BU_:  Airbag BAP_Tester ICAS1_Gateway ICAS1_KommunikationsServer LE1 LE2 Motor_BEV Schaltbetaetigung

BU_:  Airbag BAP_Tester ICAS1_Gateway ICAS1_KommunikationsServer LE1 LE2 Motor_BEV Schaltbetaetigung

BO_ 980 SMLS_01: 8 ICAS1_Gateway
 SG_ SMLS_01_CRC  : 0|8@1+ (1.000000,0.000000) [0.000000|255.000000] "" Vector__XXX
 SG_ SMLS_01_BZ  : 8|4@1+ (1.000000,0.000000) [0.000000|15.000000] "" Vector__XXX
 SG_ BH_Blinker_li  : 12|1@1+ (1.000000,0.000000) [0.000000|1.000000] "" Motor_BEV
 SG_ BH_Blinker_re  : 13|1@1+ (1.000000,0.000000) [0.000000|1.000000] "" Motor_BEV
 SG_ BH_Lichthupe  : 14|1@1+ (1.000000,0.000000) [0.000000|1.000000] "" Vector__XXX
 SG_ BH_Fernlicht  : 15|1@1+ (1.000000,0.000000) [0.000000|1.000000] "" Vector__XXX
 SG_ WH_Tipwischen  : 16|1@1+ (1.000000,0.000000) [0.000000|1.000000] "" Vector__XXX
 SG_ WH_Intervall  : 17|1@1+ (1.000000,0.000000) [0.000000|1.000000] "" Vector__XXX
 SG_ WH_WischerStufe1  : 18|1@1+ (1.000000,0.000000) [0.000000|1.000000] "" Vector__XXX
 SG_ WH_WischerStufe2  : 19|1@1+ (1.000000,0.000000) [0.000000|1.000000] "" Vector__XXX
 SG_ WH_Frontwaschen  : 20|1@1+ (1.000000,0.000000) [0.000000|1.000000] "" Vector__XXX
 SG_ WH_Heckintervall  : 21|1@1+ (1.000000,0.000000) [0.000000|1.000000] "" Vector__XXX
 SG_ WH_Heckwaschen  : 22|1@1+ (1.000000,0.000000) [0.000000|1.000000] "" Vector__XXX
 SG_ WH_Intervallstufen  : 23|4@1+ (1.000000,0.000000) [0.000000|15.000000] "" Vector__XXX
 SG_ FAS_Taster  : 27|1@1+ (1.000000,0.000000) [0.000000|1.000000] "" Vector__XXX
 SG_ FAS_Taster_Fehler  : 28|1@1+ (1.000000,0.000000) [0.000000|1.000000] "" Vector__XXX
 SG_ SMLS_Hupe  : 29|1@1+ (1.000000,0.000000) [0.000000|1.000000] "" Vector__XXX
 SG_ LRH_on_off  : 30|2@1+ (1.000000,0.000000) [0.000000|3.000000] "" Vector__XXX
 SG_ LSS_Tastencode  : 32|8@1+ (1.000000,0.000000) [0.000000|255.000000] "" Vector__XXX
 SG_ LRH_aktiv  : 40|1@1+ (1.000000,0.000000) [0.000000|1.000000] "" Vector__XXX
 SG_ SMLS_P_verriegelt  : 41|2@1+ (1.000000,0.000000) [0.000000|3.000000] "" Vector__XXX
 SG_ SMLS_P_verriegelt_plausibel  : 43|1@1+ (1.000000,0.000000) [0.000000|1.000000] "" Vector__XXX
 SG_ WH_SRA  : 44|1@1+ (1.000000,0.000000) [0.000000|1.000000] "" Vector__XXX
 SG_ WH_Wischer_Fehler  : 45|1@1+ (1.000000,0.000000) [0.000000|1.000000] "" Vector__XXX
 SG_ BH_Blinker_Fehler  : 46|1@1+ (1.000000,0.000000) [0.000000|1.000000] "" Vector__XXX
 SG_ SMLS_PTT  : 47|1@1+ (1.000000,0.000000) [0.000000|1.000000] "" Vector__XXX
 SG_ WH_Tipwischen_lang  : 48|1@1+ (1.000000,0.000000) [0.000000|1.000000] "" Vector__XXX

BO_ 2464153718 SOK_FoD_MO_01_Req_Chal_01: 8 Motor_BEV
 SG_ SOK_FoD_MO_01_Req_Challenge  : 0|64@1+ (1.000000,0.000000) [0.000000|18446744073709551616.000000] "Unit_None" ICAS1_Gateway

BO_ 2464284790 SOK_FoD_MO_01_Resp_Chal_01: 8 ICAS1_Gateway
 SG_ SOK_FoD_MO_01_Resp_Challenge  : 0|64@1+ (1.000000,0.000000) [0.000000|18446744073709551616.000000] "Unit_None" Motor_BEV

BO_ 1413 Systeminfo_01: 8 ICAS1_Gateway
 SG_ SI_Sammel_SG_Fehler  : 0|6@1+ (1.000000,0.000000) [0.000000|60.000000] "" Vector__XXX
 SG_ SI_P_Mode_gueltig  : 6|1@1+ (1.000000,0.000000) [0.000000|1.000000] "" Vector__XXX
 SG_ SI_Diagnose_Aktiv  : 7|1@1+ (1.000000,0.000000) [0.000000|1.000000] "" Vector__XXX
 SG_ SI_QRS_Mode  : 8|1@1+ (1.000000,0.000000) [0.000000|1.000000] "" Airbag Motor_BEV
 SG_ SI_T_Mode  : 9|1@1+ (1.000000,0.000000) [0.000000|1.000000] "" Motor_BEV
 SG_ SI_NWDF  : 10|1@1+ (1.000000,0.000000) [0.000000|1.000000] "" Vector__XXX
 SG_ SI_NWDF_gueltig  : 11|1@1+ (1.000000,0.000000) [0.000000|1.000000] "" Vector__XXX
 SG_ SI_Sammelfehler  : 12|1@1+ (1.000000,0.000000) [0.000000|1.000000] "" Vector__XXX
 SG_ GW_KD_Fehler  : 13|1@1+ (1.000000,0.000000) [0.000000|1.000000] "" Vector__XXX
 SG_ SI_T_Schutz  : 14|1@1+ (1.000000,0.000000) [0.000000|1.000000] "" Motor_BEV
 SG_ SI_P_Mode  : 15|1@1+ (1.000000,0.000000) [0.000000|1.000000] "" Vector__XXX
 SG_ SI_BUS_01  : 16|1@1+ (1.000000,0.000000) [0.000000|1.000000] "" Vector__XXX
 SG_ SI_BUS_02  : 17|1@1+ (1.000000,0.000000) [0.000000|1.000000] "" Vector__XXX
 SG_ SI_BUS_03  : 18|1@1+ (1.000000,0.000000) [0.000000|1.000000] "" Vector__XXX
 SG_ SI_BUS_04  : 19|1@1+ (1.000000,0.000000) [0.000000|1.000000] "" Vector__XXX
 SG_ SI_BUS_05  : 20|1@1+ (1.000000,0.000000) [0.000000|1.000000] "" Vector__XXX
 SG_ SI_BUS_06  : 21|1@1+ (1.000000,0.000000) [0.000000|1.000000] "" Vector__XXX
 SG_ SI_BUS_07  : 22|1@1+ (1.000000,0.000000) [0.000000|1.000000] "" Vector__XXX
 SG_ SI_BUS_08  : 23|1@1+ (1.000000,0.000000) [0.000000|1.000000] "" Vector__XXX
 SG_ SI_BUS_09  : 24|1@1+ (1.000000,0.000000) [0.000000|1.000000] "" Vector__XXX
 SG_ SI_BUS_10  : 25|1@1+ (1.000000,0.000000) [0.000000|1.000000] "" Vector__XXX
 SG_ SI_BUS_11  : 26|1@1+ (1.000000,0.000000) [0.000000|1.000000] "" Vector__XXX
 SG_ SI_BUS_12  : 27|1@1+ (1.000000,0.000000) [0.000000|1.000000] "" Vector__XXX
 SG_ SI_BUS_13  : 28|1@1+ (1.000000,0.000000) [0.000000|1.000000] "" Vector__XXX
 SG_ SI_BUS_14  : 29|1@1+ (1.000000,0.000000) [0.000000|1.000000] "" Vector__XXX
 SG_ SI_BUS_15  : 30|1@1+ (1.000000,0.000000) [0.000000|1.000000] "" Vector__XXX
 SG_ SI_Bus_Identifikation  : 32|8@1+ (1.000000,0.000000) [0.000000|255.000000] "" Vector__XXX
 SG_ SI_CAB_V10  : 40|24@1+ (1.000000,0.000000) [0.000000|16777215.000000] "" Vector__XXX

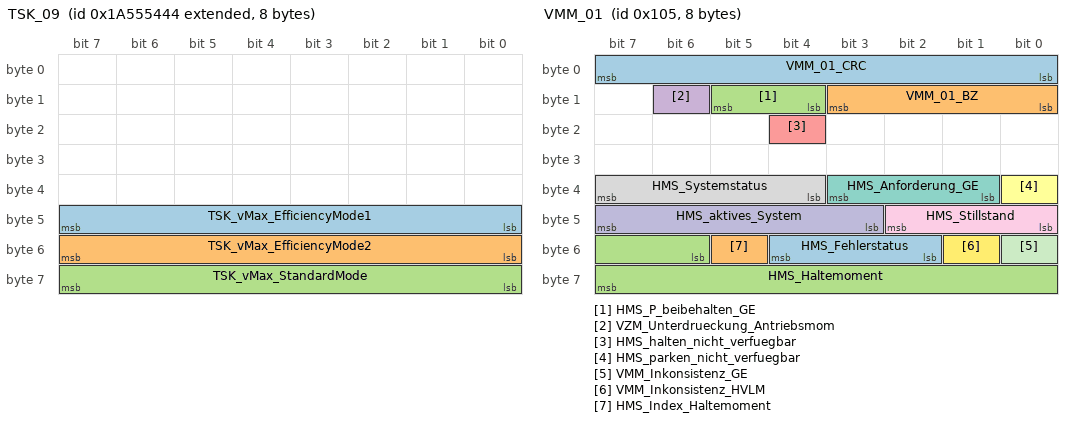
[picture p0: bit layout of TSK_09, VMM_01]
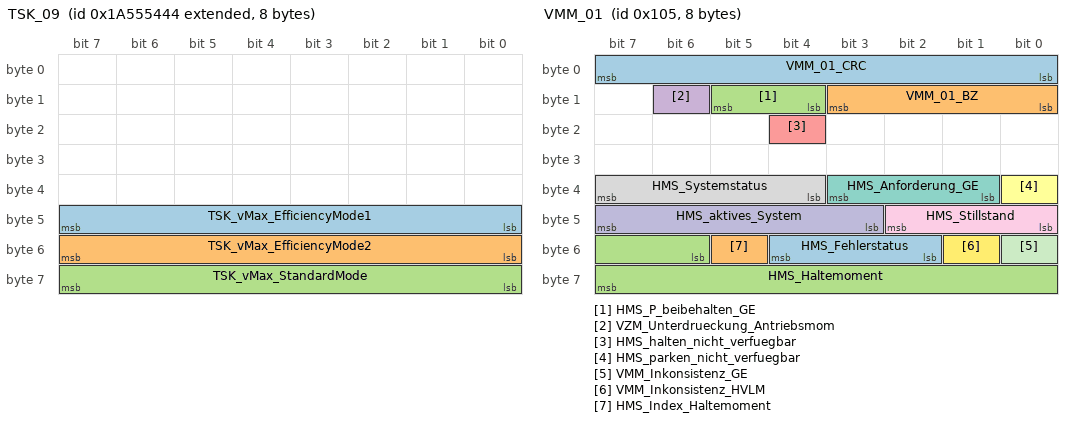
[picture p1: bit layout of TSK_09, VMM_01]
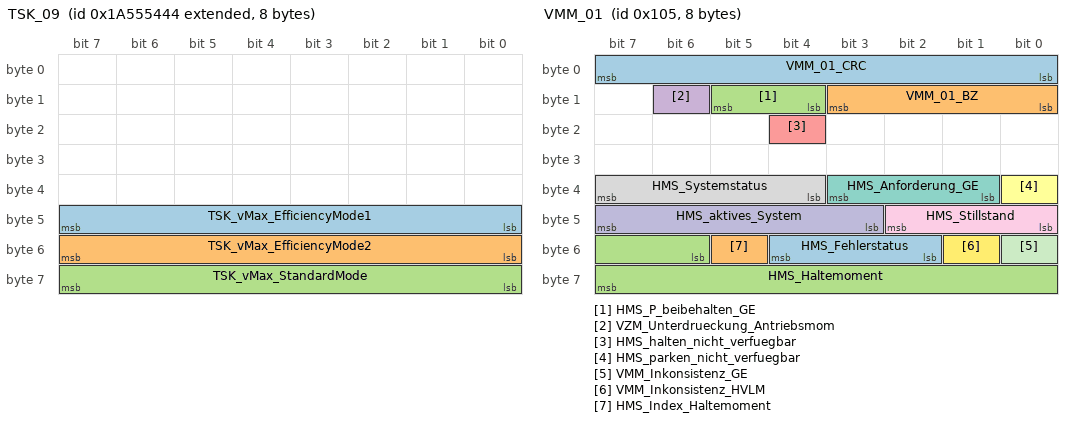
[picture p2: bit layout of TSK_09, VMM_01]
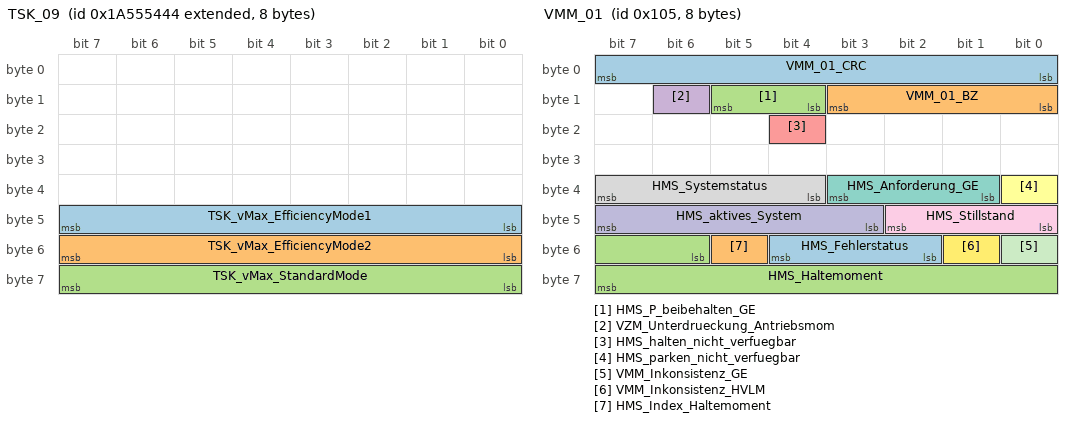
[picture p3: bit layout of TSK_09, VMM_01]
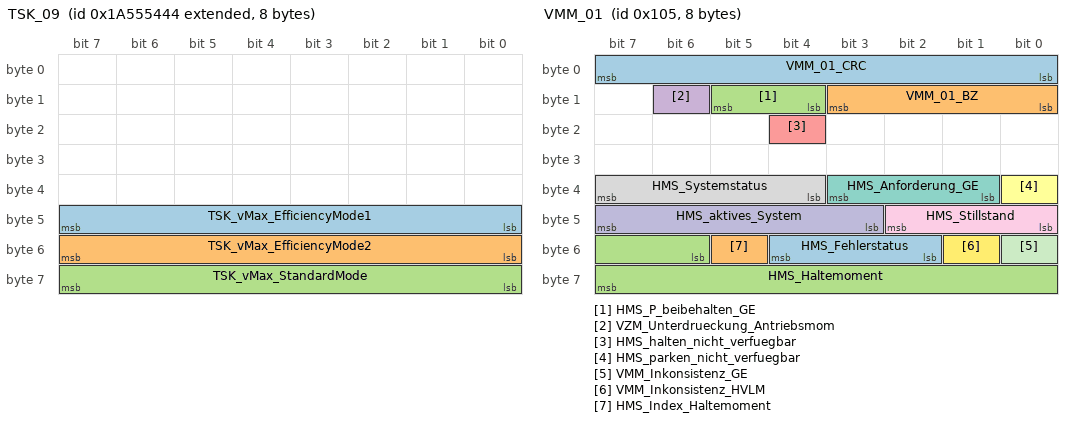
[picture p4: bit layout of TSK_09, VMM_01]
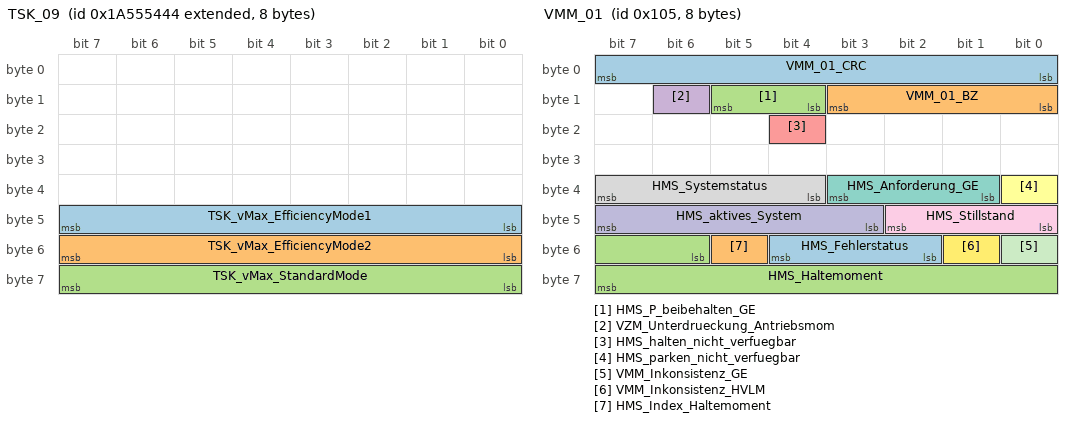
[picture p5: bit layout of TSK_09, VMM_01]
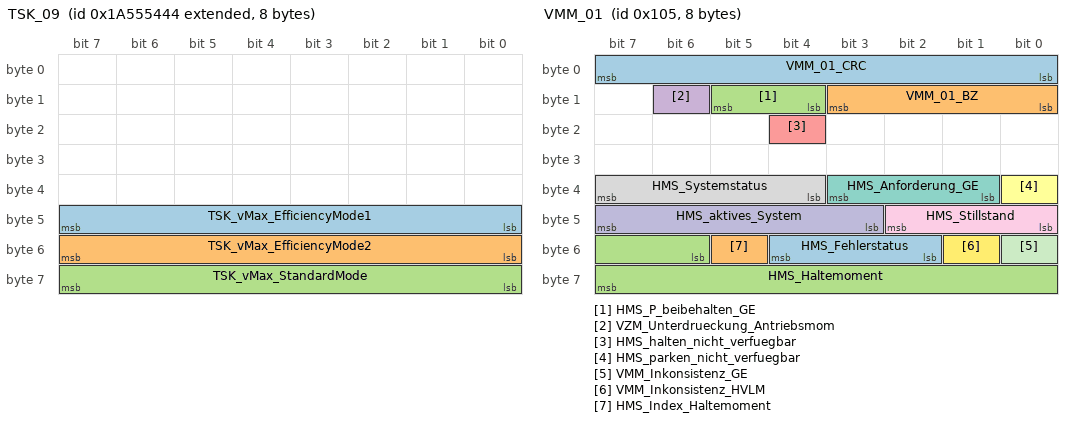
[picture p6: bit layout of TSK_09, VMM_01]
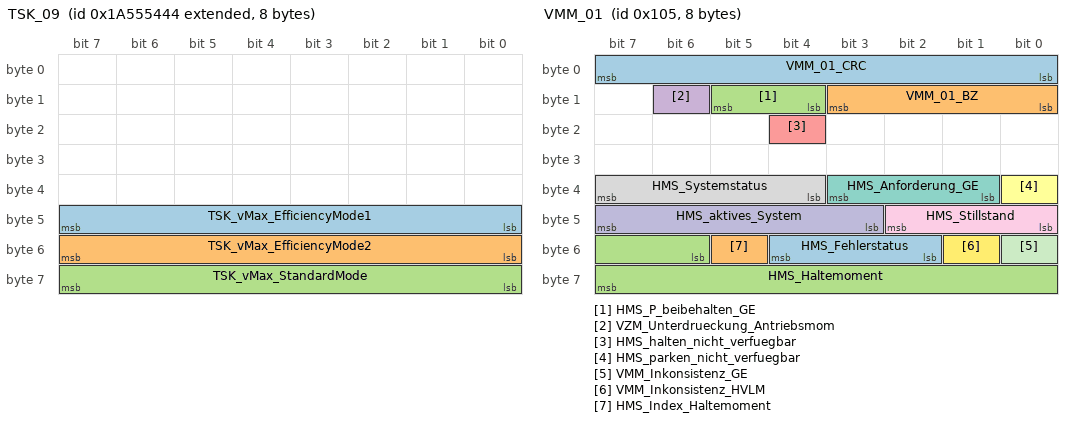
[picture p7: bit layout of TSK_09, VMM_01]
BO_ 2589283396 TSK_09: 8 Motor_BEV
 SG_ TSK_vMax_EfficiencyMode1  : 40|8@1+ (1.000000,0.000000) [0.000000|253.000000] "Unit_KiloMeterPerHour" ICAS1_Gateway
 SG_ TSK_vMax_EfficiencyMode2  : 48|8@1+ (1.000000,0.000000) [0.000000|253.000000] "Unit_KiloMeterPerHour" ICAS1_Gateway
 SG_ TSK_vMax_StandardMode  : 56|8@1+ (1.000000,0.000000) [0.000000|253.000000] "Unit_KiloMeterPerHour" ICAS1_Gateway

BO_ 1019 TSK_Ausrollkurve_01: 8 Motor_BEV
 SG_ TSK_Ausrollkurve_Schub_Reku_01 m0 : 0|7@1+ (2.000000,0.000000) [0.000000|252.000000] "Unit_KiloMeterPerHour" ICAS1_Gateway
 SG_ TSK_Ausrollkurve_Schub_Reku_05 m1 : 0|7@1+ (2.000000,0.000000) [0.000000|252.000000] "Unit_KiloMeterPerHour" ICAS1_Gateway
 SG_ TSK_Ausrollkurve_Schub_Reku_09 m2 : 0|7@1+ (2.000000,0.000000) [0.000000|252.000000] "Unit_KiloMeterPerHour" ICAS1_Gateway
 SG_ TSK_Ausrollkurve_Schub_Reku_13 m3 : 0|7@1+ (2.000000,0.000000) [0.000000|252.000000] "Unit_KiloMeterPerHour" ICAS1_Gateway
 SG_ TSK_Ausrollkurve_Schub_Reku_17 m4 : 0|7@1+ (2.000000,0.000000) [0.000000|252.000000] "Unit_KiloMeterPerHour" ICAS1_Gateway
 SG_ TSK_Ausrollkurve_Schub_Reku_02 m0 : 7|7@1+ (2.000000,0.000000) [0.000000|252.000000] "Unit_KiloMeterPerHour" ICAS1_Gateway
 SG_ TSK_Ausrollkurve_Schub_Reku_06 m1 : 7|7@1+ (2.000000,0.000000) [0.000000|252.000000] "Unit_KiloMeterPerHour" ICAS1_Gateway
 SG_ TSK_Ausrollkurve_Schub_Reku_10 m2 : 7|7@1+ (2.000000,0.000000) [0.000000|252.000000] "Unit_KiloMeterPerHour" ICAS1_Gateway
 SG_ TSK_Ausrollkurve_Schub_Reku_14 m3 : 7|7@1+ (2.000000,0.000000) [0.000000|252.000000] "Unit_KiloMeterPerHour" ICAS1_Gateway
 SG_ TSK_Ausrollkurve_Schub_Reku_18 m4 : 7|7@1+ (2.000000,0.000000) [0.000000|252.000000] "Unit_KiloMeterPerHour" ICAS1_Gateway
 SG_ TSK_Ausrollkurve_Schub_Reku_03 m0 : 14|7@1+ (2.000000,0.000000) [0.000000|252.000000] "Unit_KiloMeterPerHour" ICAS1_Gateway
 SG_ TSK_Ausrollkurve_Schub_Reku_07 m1 : 14|7@1+ (2.000000,0.000000) [0.000000|252.000000] "Unit_KiloMeterPerHour" ICAS1_Gateway
 SG_ TSK_Ausrollkurve_Schub_Reku_11 m2 : 14|7@1+ (2.000000,0.000000) [0.000000|252.000000] "Unit_KiloMeterPerHour" ICAS1_Gateway
 SG_ TSK_Ausrollkurve_Schub_Reku_15 m3 : 14|7@1+ (2.000000,0.000000) [0.000000|252.000000] "Unit_KiloMeterPerHour" ICAS1_Gateway
 SG_ TSK_Ausrollkurve_Schub_Reku_19 m4 : 14|7@1+ (2.000000,0.000000) [0.000000|252.000000] "Unit_KiloMeterPerHour" ICAS1_Gateway
 SG_ TSK_Ausrollkurve_Schub_Reku_04 m0 : 21|7@1+ (2.000000,0.000000) [0.000000|252.000000] "Unit_KiloMeterPerHour" ICAS1_Gateway
 SG_ TSK_Ausrollkurve_Schub_Reku_08 m1 : 21|7@1+ (2.000000,0.000000) [0.000000|252.000000] "Unit_KiloMeterPerHour" ICAS1_Gateway
 SG_ TSK_Ausrollkurve_Schub_Reku_12 m2 : 21|7@1+ (2.000000,0.000000) [0.000000|252.000000] "Unit_KiloMeterPerHour" ICAS1_Gateway
 SG_ TSK_Ausrollkurve_Schub_Reku_16 m3 : 21|7@1+ (2.000000,0.000000) [0.000000|252.000000] "Unit_KiloMeterPerHour" ICAS1_Gateway
 SG_ TSK_Ausrollkurve_Schub_Reku_20 m4 : 21|7@1+ (2.000000,0.000000) [0.000000|252.000000] "Unit_KiloMeterPerHour" ICAS1_Gateway
 SG_ TSK_Ausrollkurve_Segeln_01 m0 : 28|7@1+ (2.000000,0.000000) [0.000000|252.000000] "Unit_KiloMeterPerHour" ICAS1_Gateway
 SG_ TSK_Ausrollkurve_Segeln_05 m1 : 28|7@1+ (2.000000,0.000000) [0.000000|252.000000] "Unit_KiloMeterPerHour" ICAS1_Gateway
 SG_ TSK_Ausrollkurve_Segeln_09 m2 : 28|7@1+ (2.000000,0.000000) [0.000000|252.000000] "Unit_KiloMeterPerHour" ICAS1_Gateway
 SG_ TSK_Ausrollkurve_Segeln_13 m3 : 28|7@1+ (2.000000,0.000000) [0.000000|252.000000] "Unit_KiloMeterPerHour" ICAS1_Gateway
 SG_ TSK_Ausrollkurve_Segeln_17 m4 : 28|7@1+ (2.000000,0.000000) [0.000000|252.000000] "Unit_KiloMeterPerHour" ICAS1_Gateway
 SG_ TSK_Ausrollkurve_Segeln_02 m0 : 35|7@1+ (2.000000,0.000000) [0.000000|252.000000] "Unit_KiloMeterPerHour" ICAS1_Gateway
 SG_ TSK_Ausrollkurve_Segeln_06 m1 : 35|7@1+ (2.000000,0.000000) [0.000000|252.000000] "Unit_KiloMeterPerHour" ICAS1_Gateway
 SG_ TSK_Ausrollkurve_Segeln_10 m2 : 35|7@1+ (2.000000,0.000000) [0.000000|252.000000] "Unit_KiloMeterPerHour" ICAS1_Gateway
 SG_ TSK_Ausrollkurve_Segeln_14 m3 : 35|7@1+ (2.000000,0.000000) [0.000000|252.000000] "Unit_KiloMeterPerHour" ICAS1_Gateway
 SG_ TSK_Ausrollkurve_Segeln_18 m4 : 35|7@1+ (2.000000,0.000000) [0.000000|252.000000] "Unit_KiloMeterPerHour" ICAS1_Gateway
 SG_ TSK_Ausrollkurve_Segeln_03 m0 : 42|7@1+ (2.000000,0.000000) [0.000000|252.000000] "Unit_KiloMeterPerHour" ICAS1_Gateway
 SG_ TSK_Ausrollkurve_Segeln_07 m1 : 42|7@1+ (2.000000,0.000000) [0.000000|252.000000] "Unit_KiloMeterPerHour" ICAS1_Gateway
 SG_ TSK_Ausrollkurve_Segeln_11 m2 : 42|7@1+ (2.000000,0.000000) [0.000000|252.000000] "Unit_KiloMeterPerHour" ICAS1_Gateway
 SG_ TSK_Ausrollkurve_Segeln_15 m3 : 42|7@1+ (2.000000,0.000000) [0.000000|252.000000] "Unit_KiloMeterPerHour" ICAS1_Gateway
 SG_ TSK_Ausrollkurve_Segeln_19 m4 : 42|7@1+ (2.000000,0.000000) [0.000000|252.000000] "Unit_KiloMeterPerHour" ICAS1_Gateway
 SG_ TSK_Ausrollkurve_Segeln_04 m0 : 49|7@1+ (2.000000,0.000000) [0.000000|252.000000] "Unit_KiloMeterPerHour" ICAS1_Gateway
 SG_ TSK_Ausrollkurve_Segeln_08 m1 : 49|7@1+ (2.000000,0.000000) [0.000000|252.000000] "Unit_KiloMeterPerHour" ICAS1_Gateway
 SG_ TSK_Ausrollkurve_Segeln_12 m2 : 49|7@1+ (2.000000,0.000000) [0.000000|252.000000] "Unit_KiloMeterPerHour" ICAS1_Gateway
 SG_ TSK_Ausrollkurve_Segeln_16 m3 : 49|7@1+ (2.000000,0.000000) [0.000000|252.000000] "Unit_KiloMeterPerHour" ICAS1_Gateway
 SG_ TSK_Ausrollkurve_Segeln_20 m4 : 49|7@1+ (2.000000,0.000000) [0.000000|252.000000] "Unit_KiloMeterPerHour" ICAS1_Gateway
 SG_ TSK_Ausrollkurve_Mux M : 56|3@1+ (1.000000,0.000000) [0.000000|7.000000] "" ICAS1_Gateway
 SG_ TSK_Ausrollkurve_Reku  : 59|1@1+ (1.000000,0.000000) [0.000000|1.000000] "" ICAS1_Gateway
 SG_ TSK_Ausrollkurve_Schrittweite  : 60|1@1+ (1.000000,0.000000) [0.000000|1.000000] "" ICAS1_Gateway
 SG_ TSK_Ausrollkurve_Zaehler  : 61|2@1+ (1.000000,0.000000) [0.000000|3.000000] "" ICAS1_Gateway

BO_ 1716 VIN_01: 8 ICAS1_Gateway
 SG_ VIN_01_MUX M : 0|2@1+ (1.000000,0.000000) [0.000000|3.000000] "" Airbag Motor_BEV
 SG_ KS_Geheimnis_1 m0 : 8|8@1+ (1.000000,0.000000) [0.000000|255.000000] "" Airbag
 SG_ VIN_4 m1 : 8|8@1+ (1.000000,0.000000) [0.000000|255.000000] "" Airbag Motor_BEV
 SG_ VIN_11 m2 : 8|8@1+ (1.000000,0.000000) [0.000000|255.000000] "" Airbag Motor_BEV
 SG_ KS_Geheimnis_2 m0 : 16|8@1+ (1.000000,0.000000) [0.000000|255.000000] "" Airbag
 SG_ VIN_5 m1 : 16|8@1+ (1.000000,0.000000) [0.000000|255.000000] "" Airbag Motor_BEV
 SG_ VIN_12 m2 : 16|8@1+ (1.000000,0.000000) [0.000000|255.000000] "" Airbag Motor_BEV
 SG_ KS_Geheimnis_3 m0 : 24|8@1+ (1.000000,0.000000) [0.000000|255.000000] "" Airbag
 SG_ VIN_6 m1 : 24|8@1+ (1.000000,0.000000) [0.000000|255.000000] "" Airbag Motor_BEV
 SG_ VIN_13 m2 : 24|8@1+ (1.000000,0.000000) [0.000000|255.000000] "" Airbag Motor_BEV
 SG_ KS_Geheimnis_4 m0 : 32|8@1+ (1.000000,0.000000) [0.000000|255.000000] "" Airbag
 SG_ VIN_7 m1 : 32|8@1+ (1.000000,0.000000) [0.000000|255.000000] "" Airbag Motor_BEV
 SG_ VIN_14 m2 : 32|8@1+ (1.000000,0.000000) [0.000000|255.000000] "" Airbag Motor_BEV
 SG_ VIN_1 m0 : 40|8@1+ (1.000000,0.000000) [0.000000|255.000000] "" Airbag Motor_BEV
 SG_ VIN_8 m1 : 40|8@1+ (1.000000,0.000000) [0.000000|255.000000] "" Airbag Motor_BEV
 SG_ VIN_15 m2 : 40|8@1+ (1.000000,0.000000) [0.000000|255.000000] "" Airbag Motor_BEV
 SG_ VIN_2 m0 : 48|8@1+ (1.000000,0.000000) [0.000000|255.000000] "" Airbag Motor_BEV
 SG_ VIN_9 m1 : 48|8@1+ (1.000000,0.000000) [0.000000|255.000000] "" Airbag Motor_BEV
 SG_ VIN_16 m2 : 48|8@1+ (1.000000,0.000000) [0.000000|255.000000] "" Airbag Motor_BEV
 SG_ VIN_3 m0 : 56|8@1+ (1.000000,0.000000) [0.000000|255.000000] "" Airbag Motor_BEV
 SG_ VIN_10 m1 : 56|8@1+ (1.000000,0.000000) [0.000000|255.000000] "" Airbag Motor_BEV
 SG_ VIN_17 m2 : 56|8@1+ (1.000000,0.000000) [0.000000|255.000000] "" Airbag Motor_BEV

BO_ 261 VMM_01: 8 ICAS1_Gateway
 SG_ VMM_01_CRC  : 0|8@1+ (1.000000,0.000000) [0.000000|255.000000] "" Motor_BEV
 SG_ VMM_01_BZ  : 8|4@1+ (1.000000,0.000000) [0.000000|15.000000] "" Motor_BEV
 SG_ HMS_P_beibehalten_GE  : 12|2@1+ (1.000000,0.000000) [0.000000|3.000000] "" Vector__XXX
 SG_ VZM_Unterdrueckung_Antriebsmom  : 14|1@1+ (1.000000,0.000000) [0.000000|1.000000] "" Airbag Motor_BEV
 SG_ HMS_halten_nicht_verfuegbar  : 20|1@1+ (1.000000,0.000000) [0.000000|1.000000] "" Vector__XXX
 SG_ HMS_parken_nicht_verfuegbar  : 32|1@1+ (1.000000,0.000000) [0.000000|1.000000] "" Vector__XXX
 SG_ HMS_Anforderung_GE  : 33|3@1+ (1.000000,0.000000) [0.000000|7.000000] "" Vector__XXX
 SG_ HMS_Systemstatus  : 36|4@1+ (1.000000,0.000000) [0.000000|15.000000] "" Motor_BEV
 SG_ HMS_Stillstand  : 40|3@1+ (1.000000,0.000000) [0.000000|7.000000] "" Motor_BEV
 SG_ HMS_aktives_System  : 43|5@1+ (1.000000,0.000000) [0.000000|31.000000] "" Motor_BEV
 SG_ VMM_Inkonsistenz_GE  : 48|1@1+ (1.000000,0.000000) [0.000000|1.000000] "" Motor_BEV
 SG_ VMM_Inkonsistenz_HVLM  : 49|1@1+ (1.000000,0.000000) [0.000000|1.000000] "" Motor_BEV
 SG_ HMS_Fehlerstatus  : 50|3@1+ (1.000000,0.000000) [0.000000|7.000000] "" Vector__XXX
 SG_ HMS_Index_Haltemoment  : 53|1@1+ (1.000000,0.000000) [0.000000|1.000000] "" Motor_BEV
 SG_ HMS_Haltemoment  : 54|10@1+ (10.000000,0.000000) [0.000000|10210.000000] "Unit_NewtoMeter" Motor_BEV

BO_ 313 VMM_02: 32 ICAS1_Gateway
 SG_ VMM_02_CRC  : 0|8@1+ (1.000000,0.000000) [0.000000|255.000000] "" Motor_BEV
 SG_ VMM_02_BZ  : 8|4@1+ (1.000000,0.000000) [0.000000|15.000000] "" Motor_BEV
 SG_ VZM_aktiver_Basisservice  : 12|3@1+ (1.000000,0.000000) [0.000000|7.000000] "" Motor_BEV
 SG_ VZM_Anhalteweg_nicht_verfuegbar  : 15|1@1+ (1.000000,0.000000) [0.000000|1.000000] "" Motor_BEV
 SG_ VZM_Fahrer_bremst  : 16|1@1+ (1.000000,0.000000) [0.000000|1.000000] "" Motor_BEV
 SG_ VZM_QBit_Fahrer_bremst  : 17|1@1+ (1.000000,0.000000) [0.000000|1.000000] "" Motor_BEV
 SG_ VMM_MKB_codiert  : 18|1@1+ (1.000000,0.000000) [0.000000|1.000000] "" Airbag
 SG_ VMM_Inkonsistenz_EBKV  : 19|1@1+ (1.000000,0.000000) [0.000000|1.000000] "" Vector__XXX
 SG_ VMM_Notstopp_Status  : 20|3@1+ (1.000000,0.000000) [0.000000|7.000000] "" Motor_BEV
 SG_ VZM_Warnruck_nicht_verfuegbar  : 23|1@1+ (1.000000,0.000000) [0.000000|1.000000] "" Motor_BEV
 SG_ VZM_Warnruckeln_nicht_verfuegbar  : 24|1@1+ (1.000000,0.000000) [0.000000|1.000000] "" Motor_BEV
 SG_ VZM_Bkd_nicht_verfuegbar  : 25|1@1+ (1.000000,0.000000) [0.000000|1.000000] "" Motor_BEV
 SG_ VMM_Bremslicht_defekt  : 26|1@1+ (1.000000,0.000000) [0.000000|1.000000] "" Motor_BEV
 SG_ VZM_Fahrer_bremst_deutlich  : 27|1@1+ (1.000000,0.000000) [0.000000|1.000000] "" Airbag Motor_BEV
 SG_ VZM_TSK_SRBM_Anf  : 28|1@1+ (1.000000,0.000000) [0.000000|1.000000] "" Motor_BEV
 SG_ VZM_TSK_SRBM_nicht_verfuegbar  : 29|1@1+ (1.000000,0.000000) [0.000000|1.000000] "" Motor_BEV
 SG_ VZM_Verz_Reg_aktiv  : 30|5@1+ (1.000000,0.000000) [0.000000|31.000000] "" Motor_BEV
 SG_ VZM_Verz_Reg_nicht_verfuegbar  : 35|1@1+ (1.000000,0.000000) [0.000000|1.000000] "" Motor_BEV
 SG_ VMM_Inkonsistenz_KAS  : 36|1@1+ (1.000000,0.000000) [0.000000|1.000000] "" Motor_BEV
 SG_ VMM_Bremslicht_unplausibel  : 37|1@1+ (1.000000,0.000000) [0.000000|1.000000] "" Motor_BEV
 SG_ VMM_Inkonsistenz_ACC  : 38|1@1+ (1.000000,0.000000) [0.000000|1.000000] "" Motor_BEV
 SG_ VMM_Inkonsistenz_AWV_PCF  : 39|1@1+ (1.000000,0.000000) [0.000000|1.000000] "" Motor_BEV
 SG_ VMM_Inkonsistenz_ARA  : 40|1@1+ (1.000000,0.000000) [0.000000|1.000000] "" Motor_BEV
 SG_ VMM_Inkonsistenz_ParkAssist  : 41|1@1+ (1.000000,0.000000) [0.000000|1.000000] "" Motor_BEV
 SG_ VMM_Inkonsistenz_FAS_VK  : 42|1@1+ (1.000000,0.000000) [0.000000|1.000000] "" Motor_BEV
 SG_ VMM_Inkonsistenz_NV  : 43|1@1+ (1.000000,0.000000) [0.000000|1.000000] "" Motor_BEV
 SG_ VMM_Inkonsistenz_RCTA  : 44|1@1+ (1.000000,0.000000) [0.000000|1.000000] "" Motor_BEV
 SG_ VMM_Inkonsistenz_TSK  : 45|1@1+ (1.000000,0.000000) [0.000000|1.000000] "" Motor_BEV
 SG_ VMM_Inkonsistenz_MO  : 46|1@1+ (1.000000,0.000000) [0.000000|1.000000] "" Motor_BEV
 SG_ VMM_Inkonsistenz_AEB  : 47|1@1+ (1.000000,0.000000) [0.000000|1.000000] "" Vector__XXX
 SG_ VMM_Fahrer_Bremskraft_bestimmend  : 48|1@1+ (1.000000,0.000000) [0.000000|1.000000] "" Motor_BEV
 SG_ VMM_Inkonsistenz_EA  : 49|1@1+ (1.000000,0.000000) [0.000000|1.000000] "" Motor_BEV
 SG_ VZM_Status_Wegregelung  : 50|2@1+ (1.000000,0.000000) [0.000000|3.000000] "" Motor_BEV
 SG_ VZM_Verz_ASIL_Verfuegbarkeit  : 52|3@1+ (1.000000,0.000000) [0.000000|7.000000] "" Motor_BEV
 SG_ VZM_aktives_System  : 55|5@1+ (1.000000,0.000000) [0.000000|31.000000] "" Airbag Motor_BEV
 SG_ VZM_Verz_Begrenzung  : 60|1@1+ (1.000000,0.000000) [0.000000|1.000000] "" Motor_BEV
 SG_ VZM_Systemstatus  : 61|3@1+ (1.000000,0.000000) [0.000000|7.000000] "" Motor_BEV
 SG_ VZM_SRBM_Soll  : 64|12@1+ (8.000000,0.000000) [0.000000|32744.000000] "Unit_NewtoMeter" Motor_BEV
 SG_ VZM_SRBM_Ist  : 76|12@1+ (8.000000,0.000000) [0.000000|32744.000000] "Unit_NewtoMeter" Motor_BEV
 SG_ VZM_SRBM_max_Gradient  : 88|7@1+ (50.000000,0.000000) [0.000000|6250.000000] "Unit_NewtoMeterPerSecon" Motor_BEV
 SG_ VMM_Inkonsistenz_KAM  : 95|1@1+ (1.000000,0.000000) [0.000000|1.000000] "" Vector__XXX

BU_:  Airbag BAP_Tester ICAS1_Gateway ICAS1_KommunikationsServer LE1 LE2 Motor_BEV Schaltbetaetigung

BO_ 980 SMLS_01: 8 ICAS1_Gateway
 SG_ SMLS_01_CRC  : 0|8@1+ (1.000000,0.000000) [0.000000|255.000000] "" Vector__XXX
 SG_ SMLS_01_BZ  : 8|4@1+ (1.000000,0.000000) [0.000000|15.000000] "" Vector__XXX
 SG_ BH_Blinker_li  : 12|1@1+ (1.000000,0.000000) [0.000000|1.000000] "" Motor_BEV
 SG_ BH_Blinker_re  : 13|1@1+ (1.000000,0.000000) [0.000000|1.000000] "" Motor_BEV
 SG_ BH_Lichthupe  : 14|1@1+ (1.000000,0.000000) [0.000000|1.000000] "" Vector__XXX
 SG_ BH_Fernlicht  : 15|1@1+ (1.000000,0.000000) [0.000000|1.000000] "" Vector__XXX
 SG_ WH_Tipwischen  : 16|1@1+ (1.000000,0.000000) [0.000000|1.000000] "" Vector__XXX
 SG_ WH_Intervall  : 17|1@1+ (1.000000,0.000000) [0.000000|1.000000] "" Vector__XXX
 SG_ WH_WischerStufe1  : 18|1@1+ (1.000000,0.000000) [0.000000|1.000000] "" Vector__XXX
 SG_ WH_WischerStufe2  : 19|1@1+ (1.000000,0.000000) [0.000000|1.000000] "" Vector__XXX
 SG_ WH_Frontwaschen  : 20|1@1+ (1.000000,0.000000) [0.000000|1.000000] "" Vector__XXX
 SG_ WH_Heckintervall  : 21|1@1+ (1.000000,0.000000) [0.000000|1.000000] "" Vector__XXX
 SG_ WH_Heckwaschen  : 22|1@1+ (1.000000,0.000000) [0.000000|1.000000] "" Vector__XXX
 SG_ WH_Intervallstufen  : 23|4@1+ (1.000000,0.000000) [0.000000|15.000000] "" Vector__XXX
 SG_ FAS_Taster  : 27|1@1+ (1.000000,0.000000) [0.000000|1.000000] "" Vector__XXX
 SG_ FAS_Taster_Fehler  : 28|1@1+ (1.000000,0.000000) [0.000000|1.000000] "" Vector__XXX
 SG_ SMLS_Hupe  : 29|1@1+ (1.000000,0.000000) [0.000000|1.000000] "" Vector__XXX
 SG_ LRH_on_off  : 30|2@1+ (1.000000,0.000000) [0.000000|3.000000] "" Vector__XXX
 SG_ LSS_Tastencode  : 32|8@1+ (1.000000,0.000000) [0.000000|255.000000] "" Vector__XXX
 SG_ LRH_aktiv  : 40|1@1+ (1.000000,0.000000) [0.000000|1.000000] "" Vector__XXX
 SG_ SMLS_P_verriegelt  : 41|2@1+ (1.000000,0.000000) [0.000000|3.000000] "" Vector__XXX
 SG_ SMLS_P_verriegelt_plausibel  : 43|1@1+ (1.000000,0.000000) [0.000000|1.000000] "" Vector__XXX
 SG_ WH_SRA  : 44|1@1+ (1.000000,0.000000) [0.000000|1.000000] "" Vector__XXX
 SG_ WH_Wischer_Fehler  : 45|1@1+ (1.000000,0.000000) [0.000000|1.000000] "" Vector__XXX
 SG_ BH_Blinker_Fehler  : 46|1@1+ (1.000000,0.000000) [0.000000|1.000000] "" Vector__XXX
 SG_ SMLS_PTT  : 47|1@1+ (1.000000,0.000000) [0.000000|1.000000] "" Vector__XXX
 SG_ WH_Tipwischen_lang  : 48|1@1+ (1.000000,0.000000) [0.000000|1.000000] "" Vector__XXX

BO_ 2464153718 SOK_FoD_MO_01_Req_Chal_01: 8 Motor_BEV
 SG_ SOK_FoD_MO_01_Req_Challenge  : 0|64@1+ (1.000000,0.000000) [0.000000|18446744073709551616.000000] "Unit_None" ICAS1_Gateway

BO_ 2464284790 SOK_FoD_MO_01_Resp_Chal_01: 8 ICAS1_Gateway
 SG_ SOK_FoD_MO_01_Resp_Challenge  : 0|64@1+ (1.000000,0.000000) [0.000000|18446744073709551616.000000] "Unit_None" Motor_BEV

BO_ 1413 Systeminfo_01: 8 ICAS1_Gateway
 SG_ SI_Sammel_SG_Fehler  : 0|6@1+ (1.000000,0.000000) [0.000000|60.000000] "" Vector__XXX
 SG_ SI_P_Mode_gueltig  : 6|1@1+ (1.000000,0.000000) [0.000000|1.000000] "" Vector__XXX
 SG_ SI_Diagnose_Aktiv  : 7|1@1+ (1.000000,0.000000) [0.000000|1.000000] "" Vector__XXX
 SG_ SI_QRS_Mode  : 8|1@1+ (1.000000,0.000000) [0.000000|1.000000] "" Airbag Motor_BEV
 SG_ SI_T_Mode  : 9|1@1+ (1.000000,0.000000) [0.000000|1.000000] "" Motor_BEV
 SG_ SI_NWDF  : 10|1@1+ (1.000000,0.000000) [0.000000|1.000000] "" Vector__XXX
 SG_ SI_NWDF_gueltig  : 11|1@1+ (1.000000,0.000000) [0.000000|1.000000] "" Vector__XXX
 SG_ SI_Sammelfehler  : 12|1@1+ (1.000000,0.000000) [0.000000|1.000000] "" Vector__XXX
 SG_ GW_KD_Fehler  : 13|1@1+ (1.000000,0.000000) [0.000000|1.000000] "" Vector__XXX
 SG_ SI_T_Schutz  : 14|1@1+ (1.000000,0.000000) [0.000000|1.000000] "" Motor_BEV
 SG_ SI_P_Mode  : 15|1@1+ (1.000000,0.000000) [0.000000|1.000000] "" Vector__XXX
 SG_ SI_BUS_01  : 16|1@1+ (1.000000,0.000000) [0.000000|1.000000] "" Vector__XXX
 SG_ SI_BUS_02  : 17|1@1+ (1.000000,0.000000) [0.000000|1.000000] "" Vector__XXX
 SG_ SI_BUS_03  : 18|1@1+ (1.000000,0.000000) [0.000000|1.000000] "" Vector__XXX
 SG_ SI_BUS_04  : 19|1@1+ (1.000000,0.000000) [0.000000|1.000000] "" Vector__XXX
 SG_ SI_BUS_05  : 20|1@1+ (1.000000,0.000000) [0.000000|1.000000] "" Vector__XXX
 SG_ SI_BUS_06  : 21|1@1+ (1.000000,0.000000) [0.000000|1.000000] "" Vector__XXX
 SG_ SI_BUS_07  : 22|1@1+ (1.000000,0.000000) [0.000000|1.000000] "" Vector__XXX
 SG_ SI_BUS_08  : 23|1@1+ (1.000000,0.000000) [0.000000|1.000000] "" Vector__XXX
 SG_ SI_BUS_09  : 24|1@1+ (1.000000,0.000000) [0.000000|1.000000] "" Vector__XXX
 SG_ SI_BUS_10  : 25|1@1+ (1.000000,0.000000) [0.000000|1.000000] "" Vector__XXX
 SG_ SI_BUS_11  : 26|1@1+ (1.000000,0.000000) [0.000000|1.000000] "" Vector__XXX
 SG_ SI_BUS_12  : 27|1@1+ (1.000000,0.000000) [0.000000|1.000000] "" Vector__XXX
 SG_ SI_BUS_13  : 28|1@1+ (1.000000,0.000000) [0.000000|1.000000] "" Vector__XXX
 SG_ SI_BUS_14  : 29|1@1+ (1.000000,0.000000) [0.000000|1.000000] "" Vector__XXX
 SG_ SI_BUS_15  : 30|1@1+ (1.000000,0.000000) [0.000000|1.000000] "" Vector__XXX
 SG_ SI_Bus_Identifikation  : 32|8@1+ (1.000000,0.000000) [0.000000|255.000000] "" Vector__XXX
 SG_ SI_CAB_V10  : 40|24@1+ (1.000000,0.000000) [0.000000|16777215.000000] "" Vector__XXX

BO_ 2589283396 TSK_09: 8 Motor_BEV
 SG_ TSK_vMax_EfficiencyMode1  : 40|8@1+ (1.000000,0.000000) [0.000000|253.000000] "Unit_KiloMeterPerHour" ICAS1_Gateway
 SG_ TSK_vMax_EfficiencyMode2  : 48|8@1+ (1.000000,0.000000) [0.000000|253.000000] "Unit_KiloMeterPerHour" ICAS1_Gateway
 SG_ TSK_vMax_StandardMode  : 56|8@1+ (1.000000,0.000000) [0.000000|253.000000] "Unit_KiloMeterPerHour" ICAS1_Gateway

BO_ 1019 TSK_Ausrollkurve_01: 8 Motor_BEV
 SG_ TSK_Ausrollkurve_Schub_Reku_01 m0 : 0|7@1+ (2.000000,0.000000) [0.000000|252.000000] "Unit_KiloMeterPerHour" ICAS1_Gateway
 SG_ TSK_Ausrollkurve_Schub_Reku_05 m1 : 0|7@1+ (2.000000,0.000000) [0.000000|252.000000] "Unit_KiloMeterPerHour" ICAS1_Gateway
 SG_ TSK_Ausrollkurve_Schub_Reku_09 m2 : 0|7@1+ (2.000000,0.000000) [0.000000|252.000000] "Unit_KiloMeterPerHour" ICAS1_Gateway
 SG_ TSK_Ausrollkurve_Schub_Reku_13 m3 : 0|7@1+ (2.000000,0.000000) [0.000000|252.000000] "Unit_KiloMeterPerHour" ICAS1_Gateway
 SG_ TSK_Ausrollkurve_Schub_Reku_17 m4 : 0|7@1+ (2.000000,0.000000) [0.000000|252.000000] "Unit_KiloMeterPerHour" ICAS1_Gateway
 SG_ TSK_Ausrollkurve_Schub_Reku_02 m0 : 7|7@1+ (2.000000,0.000000) [0.000000|252.000000] "Unit_KiloMeterPerHour" ICAS1_Gateway
 SG_ TSK_Ausrollkurve_Schub_Reku_06 m1 : 7|7@1+ (2.000000,0.000000) [0.000000|252.000000] "Unit_KiloMeterPerHour" ICAS1_Gateway
 SG_ TSK_Ausrollkurve_Schub_Reku_10 m2 : 7|7@1+ (2.000000,0.000000) [0.000000|252.000000] "Unit_KiloMeterPerHour" ICAS1_Gateway
 SG_ TSK_Ausrollkurve_Schub_Reku_14 m3 : 7|7@1+ (2.000000,0.000000) [0.000000|252.000000] "Unit_KiloMeterPerHour" ICAS1_Gateway
 SG_ TSK_Ausrollkurve_Schub_Reku_18 m4 : 7|7@1+ (2.000000,0.000000) [0.000000|252.000000] "Unit_KiloMeterPerHour" ICAS1_Gateway
 SG_ TSK_Ausrollkurve_Schub_Reku_03 m0 : 14|7@1+ (2.000000,0.000000) [0.000000|252.000000] "Unit_KiloMeterPerHour" ICAS1_Gateway
 SG_ TSK_Ausrollkurve_Schub_Reku_07 m1 : 14|7@1+ (2.000000,0.000000) [0.000000|252.000000] "Unit_KiloMeterPerHour" ICAS1_Gateway
 SG_ TSK_Ausrollkurve_Schub_Reku_11 m2 : 14|7@1+ (2.000000,0.000000) [0.000000|252.000000] "Unit_KiloMeterPerHour" ICAS1_Gateway
 SG_ TSK_Ausrollkurve_Schub_Reku_15 m3 : 14|7@1+ (2.000000,0.000000) [0.000000|252.000000] "Unit_KiloMeterPerHour" ICAS1_Gateway
 SG_ TSK_Ausrollkurve_Schub_Reku_19 m4 : 14|7@1+ (2.000000,0.000000) [0.000000|252.000000] "Unit_KiloMeterPerHour" ICAS1_Gateway
 SG_ TSK_Ausrollkurve_Schub_Reku_04 m0 : 21|7@1+ (2.000000,0.000000) [0.000000|252.000000] "Unit_KiloMeterPerHour" ICAS1_Gateway
 SG_ TSK_Ausrollkurve_Schub_Reku_08 m1 : 21|7@1+ (2.000000,0.000000) [0.000000|252.000000] "Unit_KiloMeterPerHour" ICAS1_Gateway
 SG_ TSK_Ausrollkurve_Schub_Reku_12 m2 : 21|7@1+ (2.000000,0.000000) [0.000000|252.000000] "Unit_KiloMeterPerHour" ICAS1_Gateway
 SG_ TSK_Ausrollkurve_Schub_Reku_16 m3 : 21|7@1+ (2.000000,0.000000) [0.000000|252.000000] "Unit_KiloMeterPerHour" ICAS1_Gateway
 SG_ TSK_Ausrollkurve_Schub_Reku_20 m4 : 21|7@1+ (2.000000,0.000000) [0.000000|252.000000] "Unit_KiloMeterPerHour" ICAS1_Gateway
 SG_ TSK_Ausrollkurve_Segeln_01 m0 : 28|7@1+ (2.000000,0.000000) [0.000000|252.000000] "Unit_KiloMeterPerHour" ICAS1_Gateway
 SG_ TSK_Ausrollkurve_Segeln_05 m1 : 28|7@1+ (2.000000,0.000000) [0.000000|252.000000] "Unit_KiloMeterPerHour" ICAS1_Gateway
 SG_ TSK_Ausrollkurve_Segeln_09 m2 : 28|7@1+ (2.000000,0.000000) [0.000000|252.000000] "Unit_KiloMeterPerHour" ICAS1_Gateway
 SG_ TSK_Ausrollkurve_Segeln_13 m3 : 28|7@1+ (2.000000,0.000000) [0.000000|252.000000] "Unit_KiloMeterPerHour" ICAS1_Gateway
 SG_ TSK_Ausrollkurve_Segeln_17 m4 : 28|7@1+ (2.000000,0.000000) [0.000000|252.000000] "Unit_KiloMeterPerHour" ICAS1_Gateway
 SG_ TSK_Ausrollkurve_Segeln_02 m0 : 35|7@1+ (2.000000,0.000000) [0.000000|252.000000] "Unit_KiloMeterPerHour" ICAS1_Gateway
 SG_ TSK_Ausrollkurve_Segeln_06 m1 : 35|7@1+ (2.000000,0.000000) [0.000000|252.000000] "Unit_KiloMeterPerHour" ICAS1_Gateway
 SG_ TSK_Ausrollkurve_Segeln_10 m2 : 35|7@1+ (2.000000,0.000000) [0.000000|252.000000] "Unit_KiloMeterPerHour" ICAS1_Gateway
 SG_ TSK_Ausrollkurve_Segeln_14 m3 : 35|7@1+ (2.000000,0.000000) [0.000000|252.000000] "Unit_KiloMeterPerHour" ICAS1_Gateway
 SG_ TSK_Ausrollkurve_Segeln_18 m4 : 35|7@1+ (2.000000,0.000000) [0.000000|252.000000] "Unit_KiloMeterPerHour" ICAS1_Gateway
 SG_ TSK_Ausrollkurve_Segeln_03 m0 : 42|7@1+ (2.000000,0.000000) [0.000000|252.000000] "Unit_KiloMeterPerHour" ICAS1_Gateway
 SG_ TSK_Ausrollkurve_Segeln_07 m1 : 42|7@1+ (2.000000,0.000000) [0.000000|252.000000] "Unit_KiloMeterPerHour" ICAS1_Gateway
 SG_ TSK_Ausrollkurve_Segeln_11 m2 : 42|7@1+ (2.000000,0.000000) [0.000000|252.000000] "Unit_KiloMeterPerHour" ICAS1_Gateway
 SG_ TSK_Ausrollkurve_Segeln_15 m3 : 42|7@1+ (2.000000,0.000000) [0.000000|252.000000] "Unit_KiloMeterPerHour" ICAS1_Gateway
 SG_ TSK_Ausrollkurve_Segeln_19 m4 : 42|7@1+ (2.000000,0.000000) [0.000000|252.000000] "Unit_KiloMeterPerHour" ICAS1_Gateway
 SG_ TSK_Ausrollkurve_Segeln_04 m0 : 49|7@1+ (2.000000,0.000000) [0.000000|252.000000] "Unit_KiloMeterPerHour" ICAS1_Gateway
 SG_ TSK_Ausrollkurve_Segeln_08 m1 : 49|7@1+ (2.000000,0.000000) [0.000000|252.000000] "Unit_KiloMeterPerHour" ICAS1_Gateway
 SG_ TSK_Ausrollkurve_Segeln_12 m2 : 49|7@1+ (2.000000,0.000000) [0.000000|252.000000] "Unit_KiloMeterPerHour" ICAS1_Gateway
 SG_ TSK_Ausrollkurve_Segeln_16 m3 : 49|7@1+ (2.000000,0.000000) [0.000000|252.000000] "Unit_KiloMeterPerHour" ICAS1_Gateway
 SG_ TSK_Ausrollkurve_Segeln_20 m4 : 49|7@1+ (2.000000,0.000000) [0.000000|252.000000] "Unit_KiloMeterPerHour" ICAS1_Gateway
 SG_ TSK_Ausrollkurve_Mux M : 56|3@1+ (1.000000,0.000000) [0.000000|7.000000] "" ICAS1_Gateway
 SG_ TSK_Ausrollkurve_Reku  : 59|1@1+ (1.000000,0.000000) [0.000000|1.000000] "" ICAS1_Gateway
 SG_ TSK_Ausrollkurve_Schrittweite  : 60|1@1+ (1.000000,0.000000) [0.000000|1.000000] "" ICAS1_Gateway
 SG_ TSK_Ausrollkurve_Zaehler  : 61|2@1+ (1.000000,0.000000) [0.000000|3.000000] "" ICAS1_Gateway

BO_ 1716 VIN_01: 8 ICAS1_Gateway
 SG_ VIN_01_MUX M : 0|2@1+ (1.000000,0.000000) [0.000000|3.000000] "" Airbag Motor_BEV
 SG_ KS_Geheimnis_1 m0 : 8|8@1+ (1.000000,0.000000) [0.000000|255.000000] "" Airbag
 SG_ VIN_4 m1 : 8|8@1+ (1.000000,0.000000) [0.000000|255.000000] "" Airbag Motor_BEV
 SG_ VIN_11 m2 : 8|8@1+ (1.000000,0.000000) [0.000000|255.000000] "" Airbag Motor_BEV
 SG_ KS_Geheimnis_2 m0 : 16|8@1+ (1.000000,0.000000) [0.000000|255.000000] "" Airbag
 SG_ VIN_5 m1 : 16|8@1+ (1.000000,0.000000) [0.000000|255.000000] "" Airbag Motor_BEV
 SG_ VIN_12 m2 : 16|8@1+ (1.000000,0.000000) [0.000000|255.000000] "" Airbag Motor_BEV
 SG_ KS_Geheimnis_3 m0 : 24|8@1+ (1.000000,0.000000) [0.000000|255.000000] "" Airbag
 SG_ VIN_6 m1 : 24|8@1+ (1.000000,0.000000) [0.000000|255.000000] "" Airbag Motor_BEV
 SG_ VIN_13 m2 : 24|8@1+ (1.000000,0.000000) [0.000000|255.000000] "" Airbag Motor_BEV
 SG_ KS_Geheimnis_4 m0 : 32|8@1+ (1.000000,0.000000) [0.000000|255.000000] "" Airbag
 SG_ VIN_7 m1 : 32|8@1+ (1.000000,0.000000) [0.000000|255.000000] "" Airbag Motor_BEV
 SG_ VIN_14 m2 : 32|8@1+ (1.000000,0.000000) [0.000000|255.000000] "" Airbag Motor_BEV
 SG_ VIN_1 m0 : 40|8@1+ (1.000000,0.000000) [0.000000|255.000000] "" Airbag Motor_BEV
 SG_ VIN_8 m1 : 40|8@1+ (1.000000,0.000000) [0.000000|255.000000] "" Airbag Motor_BEV
 SG_ VIN_15 m2 : 40|8@1+ (1.000000,0.000000) [0.000000|255.000000] "" Airbag Motor_BEV
 SG_ VIN_2 m0 : 48|8@1+ (1.000000,0.000000) [0.000000|255.000000] "" Airbag Motor_BEV
 SG_ VIN_9 m1 : 48|8@1+ (1.000000,0.000000) [0.000000|255.000000] "" Airbag Motor_BEV
 SG_ VIN_16 m2 : 48|8@1+ (1.000000,0.000000) [0.000000|255.000000] "" Airbag Motor_BEV
 SG_ VIN_3 m0 : 56|8@1+ (1.000000,0.000000) [0.000000|255.000000] "" Airbag Motor_BEV
 SG_ VIN_10 m1 : 56|8@1+ (1.000000,0.000000) [0.000000|255.000000] "" Airbag Motor_BEV
 SG_ VIN_17 m2 : 56|8@1+ (1.000000,0.000000) [0.000000|255.000000] "" Airbag Motor_BEV

BO_ 261 VMM_01: 8 ICAS1_Gateway
 SG_ VMM_01_CRC  : 0|8@1+ (1.000000,0.000000) [0.000000|255.000000] "" Motor_BEV
 SG_ VMM_01_BZ  : 8|4@1+ (1.000000,0.000000) [0.000000|15.000000] "" Motor_BEV
 SG_ HMS_P_beibehalten_GE  : 12|2@1+ (1.000000,0.000000) [0.000000|3.000000] "" Vector__XXX
 SG_ VZM_Unterdrueckung_Antriebsmom  : 14|1@1+ (1.000000,0.000000) [0.000000|1.000000] "" Airbag Motor_BEV
 SG_ HMS_halten_nicht_verfuegbar  : 20|1@1+ (1.000000,0.000000) [0.000000|1.000000] "" Vector__XXX
 SG_ HMS_parken_nicht_verfuegbar  : 32|1@1+ (1.000000,0.000000) [0.000000|1.000000] "" Vector__XXX
 SG_ HMS_Anforderung_GE  : 33|3@1+ (1.000000,0.000000) [0.000000|7.000000] "" Vector__XXX
 SG_ HMS_Systemstatus  : 36|4@1+ (1.000000,0.000000) [0.000000|15.000000] "" Motor_BEV
 SG_ HMS_Stillstand  : 40|3@1+ (1.000000,0.000000) [0.000000|7.000000] "" Motor_BEV
 SG_ HMS_aktives_System  : 43|5@1+ (1.000000,0.000000) [0.000000|31.000000] "" Motor_BEV
 SG_ VMM_Inkonsistenz_GE  : 48|1@1+ (1.000000,0.000000) [0.000000|1.000000] "" Motor_BEV
 SG_ VMM_Inkonsistenz_HVLM  : 49|1@1+ (1.000000,0.000000) [0.000000|1.000000] "" Motor_BEV
 SG_ HMS_Fehlerstatus  : 50|3@1+ (1.000000,0.000000) [0.000000|7.000000] "" Vector__XXX
 SG_ HMS_Index_Haltemoment  : 53|1@1+ (1.000000,0.000000) [0.000000|1.000000] "" Motor_BEV
 SG_ HMS_Haltemoment  : 54|10@1+ (10.000000,0.000000) [0.000000|10210.000000] "Unit_NewtoMeter" Motor_BEV

BO_ 313 VMM_02: 32 ICAS1_Gateway
 SG_ VMM_02_CRC  : 0|8@1+ (1.000000,0.000000) [0.000000|255.000000] "" Motor_BEV
 SG_ VMM_02_BZ  : 8|4@1+ (1.000000,0.000000) [0.000000|15.000000] "" Motor_BEV
 SG_ VZM_aktiver_Basisservice  : 12|3@1+ (1.000000,0.000000) [0.000000|7.000000] "" Motor_BEV
 SG_ VZM_Anhalteweg_nicht_verfuegbar  : 15|1@1+ (1.000000,0.000000) [0.000000|1.000000] "" Motor_BEV
 SG_ VZM_Fahrer_bremst  : 16|1@1+ (1.000000,0.000000) [0.000000|1.000000] "" Motor_BEV
 SG_ VZM_QBit_Fahrer_bremst  : 17|1@1+ (1.000000,0.000000) [0.000000|1.000000] "" Motor_BEV
 SG_ VMM_MKB_codiert  : 18|1@1+ (1.000000,0.000000) [0.000000|1.000000] "" Airbag
 SG_ VMM_Inkonsistenz_EBKV  : 19|1@1+ (1.000000,0.000000) [0.000000|1.000000] "" Vector__XXX
 SG_ VMM_Notstopp_Status  : 20|3@1+ (1.000000,0.000000) [0.000000|7.000000] "" Motor_BEV
 SG_ VZM_Warnruck_nicht_verfuegbar  : 23|1@1+ (1.000000,0.000000) [0.000000|1.000000] "" Motor_BEV
 SG_ VZM_Warnruckeln_nicht_verfuegbar  : 24|1@1+ (1.000000,0.000000) [0.000000|1.000000] "" Motor_BEV
 SG_ VZM_Bkd_nicht_verfuegbar  : 25|1@1+ (1.000000,0.000000) [0.000000|1.000000] "" Motor_BEV
 SG_ VMM_Bremslicht_defekt  : 26|1@1+ (1.000000,0.000000) [0.000000|1.000000] "" Motor_BEV
 SG_ VZM_Fahrer_bremst_deutlich  : 27|1@1+ (1.000000,0.000000) [0.000000|1.000000] "" Airbag Motor_BEV
 SG_ VZM_TSK_SRBM_Anf  : 28|1@1+ (1.000000,0.000000) [0.000000|1.000000] "" Motor_BEV
 SG_ VZM_TSK_SRBM_nicht_verfuegbar  : 29|1@1+ (1.000000,0.000000) [0.000000|1.000000] "" Motor_BEV
 SG_ VZM_Verz_Reg_aktiv  : 30|5@1+ (1.000000,0.000000) [0.000000|31.000000] "" Motor_BEV
 SG_ VZM_Verz_Reg_nicht_verfuegbar  : 35|1@1+ (1.000000,0.000000) [0.000000|1.000000] "" Motor_BEV
 SG_ VMM_Inkonsistenz_KAS  : 36|1@1+ (1.000000,0.000000) [0.000000|1.000000] "" Motor_BEV
 SG_ VMM_Bremslicht_unplausibel  : 37|1@1+ (1.000000,0.000000) [0.000000|1.000000] "" Motor_BEV
 SG_ VMM_Inkonsistenz_ACC  : 38|1@1+ (1.000000,0.000000) [0.000000|1.000000] "" Motor_BEV
 SG_ VMM_Inkonsistenz_AWV_PCF  : 39|1@1+ (1.000000,0.000000) [0.000000|1.000000] "" Motor_BEV
 SG_ VMM_Inkonsistenz_ARA  : 40|1@1+ (1.000000,0.000000) [0.000000|1.000000] "" Motor_BEV
 SG_ VMM_Inkonsistenz_ParkAssist  : 41|1@1+ (1.000000,0.000000) [0.000000|1.000000] "" Motor_BEV
 SG_ VMM_Inkonsistenz_FAS_VK  : 42|1@1+ (1.000000,0.000000) [0.000000|1.000000] "" Motor_BEV
 SG_ VMM_Inkonsistenz_NV  : 43|1@1+ (1.000000,0.000000) [0.000000|1.000000] "" Motor_BEV
 SG_ VMM_Inkonsistenz_RCTA  : 44|1@1+ (1.000000,0.000000) [0.000000|1.000000] "" Motor_BEV
 SG_ VMM_Inkonsistenz_TSK  : 45|1@1+ (1.000000,0.000000) [0.000000|1.000000] "" Motor_BEV
 SG_ VMM_Inkonsistenz_MO  : 46|1@1+ (1.000000,0.000000) [0.000000|1.000000] "" Motor_BEV
 SG_ VMM_Inkonsistenz_AEB  : 47|1@1+ (1.000000,0.000000) [0.000000|1.000000] "" Vector__XXX
 SG_ VMM_Fahrer_Bremskraft_bestimmend  : 48|1@1+ (1.000000,0.000000) [0.000000|1.000000] "" Motor_BEV
 SG_ VMM_Inkonsistenz_EA  : 49|1@1+ (1.000000,0.000000) [0.000000|1.000000] "" Motor_BEV
 SG_ VZM_Status_Wegregelung  : 50|2@1+ (1.000000,0.000000) [0.000000|3.000000] "" Motor_BEV
 SG_ VZM_Verz_ASIL_Verfuegbarkeit  : 52|3@1+ (1.000000,0.000000) [0.000000|7.000000] "" Motor_BEV
 SG_ VZM_aktives_System  : 55|5@1+ (1.000000,0.000000) [0.000000|31.000000] "" Airbag Motor_BEV
 SG_ VZM_Verz_Begrenzung  : 60|1@1+ (1.000000,0.000000) [0.000000|1.000000] "" Motor_BEV
 SG_ VZM_Systemstatus  : 61|3@1+ (1.000000,0.000000) [0.000000|7.000000] "" Motor_BEV
 SG_ VZM_SRBM_Soll  : 64|12@1+ (8.000000,0.000000) [0.000000|32744.000000] "Unit_NewtoMeter" Motor_BEV
 SG_ VZM_SRBM_Ist  : 76|12@1+ (8.000000,0.000000) [0.000000|32744.000000] "Unit_NewtoMeter" Motor_BEV
 SG_ VZM_SRBM_max_Gradient  : 88|7@1+ (50.000000,0.000000) [0.000000|6250.000000] "Unit_NewtoMeterPerSecon" Motor_BEV
 SG_ VMM_Inkonsistenz_KAM  : 95|1@1+ (1.000000,0.000000) [0.000000|1.000000] "" Vector__XXX

BU_:  Airbag BAP_Tester ICAS1_Gateway ICAS1_KommunikationsServer LE1 LE2 Motor_BEV Schaltbetaetigung

BO_ 980 SMLS_01: 8 ICAS1_Gateway
 SG_ SMLS_01_CRC  : 0|8@1+ (1.000000,0.000000) [0.000000|255.000000] "" Vector__XXX
 SG_ SMLS_01_BZ  : 8|4@1+ (1.000000,0.000000) [0.000000|15.000000] "" Vector__XXX
 SG_ BH_Blinker_li  : 12|1@1+ (1.000000,0.000000) [0.000000|1.000000] "" Motor_BEV
 SG_ BH_Blinker_re  : 13|1@1+ (1.000000,0.000000) [0.000000|1.000000] "" Motor_BEV
 SG_ BH_Lichthupe  : 14|1@1+ (1.000000,0.000000) [0.000000|1.000000] "" Vector__XXX
 SG_ BH_Fernlicht  : 15|1@1+ (1.000000,0.000000) [0.000000|1.000000] "" Vector__XXX
 SG_ WH_Tipwischen  : 16|1@1+ (1.000000,0.000000) [0.000000|1.000000] "" Vector__XXX
 SG_ WH_Intervall  : 17|1@1+ (1.000000,0.000000) [0.000000|1.000000] "" Vector__XXX
 SG_ WH_WischerStufe1  : 18|1@1+ (1.000000,0.000000) [0.000000|1.000000] "" Vector__XXX
 SG_ WH_WischerStufe2  : 19|1@1+ (1.000000,0.000000) [0.000000|1.000000] "" Vector__XXX
 SG_ WH_Frontwaschen  : 20|1@1+ (1.000000,0.000000) [0.000000|1.000000] "" Vector__XXX
 SG_ WH_Heckintervall  : 21|1@1+ (1.000000,0.000000) [0.000000|1.000000] "" Vector__XXX
 SG_ WH_Heckwaschen  : 22|1@1+ (1.000000,0.000000) [0.000000|1.000000] "" Vector__XXX
 SG_ WH_Intervallstufen  : 23|4@1+ (1.000000,0.000000) [0.000000|15.000000] "" Vector__XXX
 SG_ FAS_Taster  : 27|1@1+ (1.000000,0.000000) [0.000000|1.000000] "" Vector__XXX
 SG_ FAS_Taster_Fehler  : 28|1@1+ (1.000000,0.000000) [0.000000|1.000000] "" Vector__XXX
 SG_ SMLS_Hupe  : 29|1@1+ (1.000000,0.000000) [0.000000|1.000000] "" Vector__XXX
 SG_ LRH_on_off  : 30|2@1+ (1.000000,0.000000) [0.000000|3.000000] "" Vector__XXX
 SG_ LSS_Tastencode  : 32|8@1+ (1.000000,0.000000) [0.000000|255.000000] "" Vector__XXX
 SG_ LRH_aktiv  : 40|1@1+ (1.000000,0.000000) [0.000000|1.000000] "" Vector__XXX
 SG_ SMLS_P_verriegelt  : 41|2@1+ (1.000000,0.000000) [0.000000|3.000000] "" Vector__XXX
 SG_ SMLS_P_verriegelt_plausibel  : 43|1@1+ (1.000000,0.000000) [0.000000|1.000000] "" Vector__XXX
 SG_ WH_SRA  : 44|1@1+ (1.000000,0.000000) [0.000000|1.000000] "" Vector__XXX
 SG_ WH_Wischer_Fehler  : 45|1@1+ (1.000000,0.000000) [0.000000|1.000000] "" Vector__XXX
 SG_ BH_Blinker_Fehler  : 46|1@1+ (1.000000,0.000000) [0.000000|1.000000] "" Vector__XXX
 SG_ SMLS_PTT  : 47|1@1+ (1.000000,0.000000) [0.000000|1.000000] "" Vector__XXX
 SG_ WH_Tipwischen_lang  : 48|1@1+ (1.000000,0.000000) [0.000000|1.000000] "" Vector__XXX

BO_ 2464153718 SOK_FoD_MO_01_Req_Chal_01: 8 Motor_BEV
 SG_ SOK_FoD_MO_01_Req_Challenge  : 0|64@1+ (1.000000,0.000000) [0.000000|18446744073709551616.000000] "Unit_None" ICAS1_Gateway

BO_ 2464284790 SOK_FoD_MO_01_Resp_Chal_01: 8 ICAS1_Gateway
 SG_ SOK_FoD_MO_01_Resp_Challenge  : 0|64@1+ (1.000000,0.000000) [0.000000|18446744073709551616.000000] "Unit_None" Motor_BEV

BO_ 1413 Systeminfo_01: 8 ICAS1_Gateway
 SG_ SI_Sammel_SG_Fehler  : 0|6@1+ (1.000000,0.000000) [0.000000|60.000000] "" Vector__XXX
 SG_ SI_P_Mode_gueltig  : 6|1@1+ (1.000000,0.000000) [0.000000|1.000000] "" Vector__XXX
 SG_ SI_Diagnose_Aktiv  : 7|1@1+ (1.000000,0.000000) [0.000000|1.000000] "" Vector__XXX
 SG_ SI_QRS_Mode  : 8|1@1+ (1.000000,0.000000) [0.000000|1.000000] "" Airbag Motor_BEV
 SG_ SI_T_Mode  : 9|1@1+ (1.000000,0.000000) [0.000000|1.000000] "" Motor_BEV
 SG_ SI_NWDF  : 10|1@1+ (1.000000,0.000000) [0.000000|1.000000] "" Vector__XXX
 SG_ SI_NWDF_gueltig  : 11|1@1+ (1.000000,0.000000) [0.000000|1.000000] "" Vector__XXX
 SG_ SI_Sammelfehler  : 12|1@1+ (1.000000,0.000000) [0.000000|1.000000] "" Vector__XXX
 SG_ GW_KD_Fehler  : 13|1@1+ (1.000000,0.000000) [0.000000|1.000000] "" Vector__XXX
 SG_ SI_T_Schutz  : 14|1@1+ (1.000000,0.000000) [0.000000|1.000000] "" Motor_BEV
 SG_ SI_P_Mode  : 15|1@1+ (1.000000,0.000000) [0.000000|1.000000] "" Vector__XXX
 SG_ SI_BUS_01  : 16|1@1+ (1.000000,0.000000) [0.000000|1.000000] "" Vector__XXX
 SG_ SI_BUS_02  : 17|1@1+ (1.000000,0.000000) [0.000000|1.000000] "" Vector__XXX
 SG_ SI_BUS_03  : 18|1@1+ (1.000000,0.000000) [0.000000|1.000000] "" Vector__XXX
 SG_ SI_BUS_04  : 19|1@1+ (1.000000,0.000000) [0.000000|1.000000] "" Vector__XXX
 SG_ SI_BUS_05  : 20|1@1+ (1.000000,0.000000) [0.000000|1.000000] "" Vector__XXX
 SG_ SI_BUS_06  : 21|1@1+ (1.000000,0.000000) [0.000000|1.000000] "" Vector__XXX
 SG_ SI_BUS_07  : 22|1@1+ (1.000000,0.000000) [0.000000|1.000000] "" Vector__XXX
 SG_ SI_BUS_08  : 23|1@1+ (1.000000,0.000000) [0.000000|1.000000] "" Vector__XXX
 SG_ SI_BUS_09  : 24|1@1+ (1.000000,0.000000) [0.000000|1.000000] "" Vector__XXX
 SG_ SI_BUS_10  : 25|1@1+ (1.000000,0.000000) [0.000000|1.000000] "" Vector__XXX
 SG_ SI_BUS_11  : 26|1@1+ (1.000000,0.000000) [0.000000|1.000000] "" Vector__XXX
 SG_ SI_BUS_12  : 27|1@1+ (1.000000,0.000000) [0.000000|1.000000] "" Vector__XXX
 SG_ SI_BUS_13  : 28|1@1+ (1.000000,0.000000) [0.000000|1.000000] "" Vector__XXX
 SG_ SI_BUS_14  : 29|1@1+ (1.000000,0.000000) [0.000000|1.000000] "" Vector__XXX
 SG_ SI_BUS_15  : 30|1@1+ (1.000000,0.000000) [0.000000|1.000000] "" Vector__XXX
 SG_ SI_Bus_Identifikation  : 32|8@1+ (1.000000,0.000000) [0.000000|255.000000] "" Vector__XXX
 SG_ SI_CAB_V10  : 40|24@1+ (1.000000,0.000000) [0.000000|16777215.000000] "" Vector__XXX

BO_ 2589283396 TSK_09: 8 Motor_BEV
 SG_ TSK_vMax_EfficiencyMode1  : 40|8@1+ (1.000000,0.000000) [0.000000|253.000000] "Unit_KiloMeterPerHour" ICAS1_Gateway
 SG_ TSK_vMax_EfficiencyMode2  : 48|8@1+ (1.000000,0.000000) [0.000000|253.000000] "Unit_KiloMeterPerHour" ICAS1_Gateway
 SG_ TSK_vMax_StandardMode  : 56|8@1+ (1.000000,0.000000) [0.000000|253.000000] "Unit_KiloMeterPerHour" ICAS1_Gateway

BO_ 1019 TSK_Ausrollkurve_01: 8 Motor_BEV
 SG_ TSK_Ausrollkurve_Schub_Reku_01 m0 : 0|7@1+ (2.000000,0.000000) [0.000000|252.000000] "Unit_KiloMeterPerHour" ICAS1_Gateway
 SG_ TSK_Ausrollkurve_Schub_Reku_05 m1 : 0|7@1+ (2.000000,0.000000) [0.000000|252.000000] "Unit_KiloMeterPerHour" ICAS1_Gateway
 SG_ TSK_Ausrollkurve_Schub_Reku_09 m2 : 0|7@1+ (2.000000,0.000000) [0.000000|252.000000] "Unit_KiloMeterPerHour" ICAS1_Gateway
 SG_ TSK_Ausrollkurve_Schub_Reku_13 m3 : 0|7@1+ (2.000000,0.000000) [0.000000|252.000000] "Unit_KiloMeterPerHour" ICAS1_Gateway
 SG_ TSK_Ausrollkurve_Schub_Reku_17 m4 : 0|7@1+ (2.000000,0.000000) [0.000000|252.000000] "Unit_KiloMeterPerHour" ICAS1_Gateway
 SG_ TSK_Ausrollkurve_Schub_Reku_02 m0 : 7|7@1+ (2.000000,0.000000) [0.000000|252.000000] "Unit_KiloMeterPerHour" ICAS1_Gateway
 SG_ TSK_Ausrollkurve_Schub_Reku_06 m1 : 7|7@1+ (2.000000,0.000000) [0.000000|252.000000] "Unit_KiloMeterPerHour" ICAS1_Gateway
 SG_ TSK_Ausrollkurve_Schub_Reku_10 m2 : 7|7@1+ (2.000000,0.000000) [0.000000|252.000000] "Unit_KiloMeterPerHour" ICAS1_Gateway
 SG_ TSK_Ausrollkurve_Schub_Reku_14 m3 : 7|7@1+ (2.000000,0.000000) [0.000000|252.000000] "Unit_KiloMeterPerHour" ICAS1_Gateway
 SG_ TSK_Ausrollkurve_Schub_Reku_18 m4 : 7|7@1+ (2.000000,0.000000) [0.000000|252.000000] "Unit_KiloMeterPerHour" ICAS1_Gateway
 SG_ TSK_Ausrollkurve_Schub_Reku_03 m0 : 14|7@1+ (2.000000,0.000000) [0.000000|252.000000] "Unit_KiloMeterPerHour" ICAS1_Gateway
 SG_ TSK_Ausrollkurve_Schub_Reku_07 m1 : 14|7@1+ (2.000000,0.000000) [0.000000|252.000000] "Unit_KiloMeterPerHour" ICAS1_Gateway
 SG_ TSK_Ausrollkurve_Schub_Reku_11 m2 : 14|7@1+ (2.000000,0.000000) [0.000000|252.000000] "Unit_KiloMeterPerHour" ICAS1_Gateway
 SG_ TSK_Ausrollkurve_Schub_Reku_15 m3 : 14|7@1+ (2.000000,0.000000) [0.000000|252.000000] "Unit_KiloMeterPerHour" ICAS1_Gateway
 SG_ TSK_Ausrollkurve_Schub_Reku_19 m4 : 14|7@1+ (2.000000,0.000000) [0.000000|252.000000] "Unit_KiloMeterPerHour" ICAS1_Gateway
 SG_ TSK_Ausrollkurve_Schub_Reku_04 m0 : 21|7@1+ (2.000000,0.000000) [0.000000|252.000000] "Unit_KiloMeterPerHour" ICAS1_Gateway
 SG_ TSK_Ausrollkurve_Schub_Reku_08 m1 : 21|7@1+ (2.000000,0.000000) [0.000000|252.000000] "Unit_KiloMeterPerHour" ICAS1_Gateway
 SG_ TSK_Ausrollkurve_Schub_Reku_12 m2 : 21|7@1+ (2.000000,0.000000) [0.000000|252.000000] "Unit_KiloMeterPerHour" ICAS1_Gateway
 SG_ TSK_Ausrollkurve_Schub_Reku_16 m3 : 21|7@1+ (2.000000,0.000000) [0.000000|252.000000] "Unit_KiloMeterPerHour" ICAS1_Gateway
 SG_ TSK_Ausrollkurve_Schub_Reku_20 m4 : 21|7@1+ (2.000000,0.000000) [0.000000|252.000000] "Unit_KiloMeterPerHour" ICAS1_Gateway
 SG_ TSK_Ausrollkurve_Segeln_01 m0 : 28|7@1+ (2.000000,0.000000) [0.000000|252.000000] "Unit_KiloMeterPerHour" ICAS1_Gateway
 SG_ TSK_Ausrollkurve_Segeln_05 m1 : 28|7@1+ (2.000000,0.000000) [0.000000|252.000000] "Unit_KiloMeterPerHour" ICAS1_Gateway
 SG_ TSK_Ausrollkurve_Segeln_09 m2 : 28|7@1+ (2.000000,0.000000) [0.000000|252.000000] "Unit_KiloMeterPerHour" ICAS1_Gateway
 SG_ TSK_Ausrollkurve_Segeln_13 m3 : 28|7@1+ (2.000000,0.000000) [0.000000|252.000000] "Unit_KiloMeterPerHour" ICAS1_Gateway
 SG_ TSK_Ausrollkurve_Segeln_17 m4 : 28|7@1+ (2.000000,0.000000) [0.000000|252.000000] "Unit_KiloMeterPerHour" ICAS1_Gateway
 SG_ TSK_Ausrollkurve_Segeln_02 m0 : 35|7@1+ (2.000000,0.000000) [0.000000|252.000000] "Unit_KiloMeterPerHour" ICAS1_Gateway
 SG_ TSK_Ausrollkurve_Segeln_06 m1 : 35|7@1+ (2.000000,0.000000) [0.000000|252.000000] "Unit_KiloMeterPerHour" ICAS1_Gateway
 SG_ TSK_Ausrollkurve_Segeln_10 m2 : 35|7@1+ (2.000000,0.000000) [0.000000|252.000000] "Unit_KiloMeterPerHour" ICAS1_Gateway
 SG_ TSK_Ausrollkurve_Segeln_14 m3 : 35|7@1+ (2.000000,0.000000) [0.000000|252.000000] "Unit_KiloMeterPerHour" ICAS1_Gateway
 SG_ TSK_Ausrollkurve_Segeln_18 m4 : 35|7@1+ (2.000000,0.000000) [0.000000|252.000000] "Unit_KiloMeterPerHour" ICAS1_Gateway
 SG_ TSK_Ausrollkurve_Segeln_03 m0 : 42|7@1+ (2.000000,0.000000) [0.000000|252.000000] "Unit_KiloMeterPerHour" ICAS1_Gateway
 SG_ TSK_Ausrollkurve_Segeln_07 m1 : 42|7@1+ (2.000000,0.000000) [0.000000|252.000000] "Unit_KiloMeterPerHour" ICAS1_Gateway
 SG_ TSK_Ausrollkurve_Segeln_11 m2 : 42|7@1+ (2.000000,0.000000) [0.000000|252.000000] "Unit_KiloMeterPerHour" ICAS1_Gateway
 SG_ TSK_Ausrollkurve_Segeln_15 m3 : 42|7@1+ (2.000000,0.000000) [0.000000|252.000000] "Unit_KiloMeterPerHour" ICAS1_Gateway
 SG_ TSK_Ausrollkurve_Segeln_19 m4 : 42|7@1+ (2.000000,0.000000) [0.000000|252.000000] "Unit_KiloMeterPerHour" ICAS1_Gateway
 SG_ TSK_Ausrollkurve_Segeln_04 m0 : 49|7@1+ (2.000000,0.000000) [0.000000|252.000000] "Unit_KiloMeterPerHour" ICAS1_Gateway
 SG_ TSK_Ausrollkurve_Segeln_08 m1 : 49|7@1+ (2.000000,0.000000) [0.000000|252.000000] "Unit_KiloMeterPerHour" ICAS1_Gateway
 SG_ TSK_Ausrollkurve_Segeln_12 m2 : 49|7@1+ (2.000000,0.000000) [0.000000|252.000000] "Unit_KiloMeterPerHour" ICAS1_Gateway
 SG_ TSK_Ausrollkurve_Segeln_16 m3 : 49|7@1+ (2.000000,0.000000) [0.000000|252.000000] "Unit_KiloMeterPerHour" ICAS1_Gateway
 SG_ TSK_Ausrollkurve_Segeln_20 m4 : 49|7@1+ (2.000000,0.000000) [0.000000|252.000000] "Unit_KiloMeterPerHour" ICAS1_Gateway
 SG_ TSK_Ausrollkurve_Mux M : 56|3@1+ (1.000000,0.000000) [0.000000|7.000000] "" ICAS1_Gateway
 SG_ TSK_Ausrollkurve_Reku  : 59|1@1+ (1.000000,0.000000) [0.000000|1.000000] "" ICAS1_Gateway
 SG_ TSK_Ausrollkurve_Schrittweite  : 60|1@1+ (1.000000,0.000000) [0.000000|1.000000] "" ICAS1_Gateway
 SG_ TSK_Ausrollkurve_Zaehler  : 61|2@1+ (1.000000,0.000000) [0.000000|3.000000] "" ICAS1_Gateway

BO_ 1716 VIN_01: 8 ICAS1_Gateway
 SG_ VIN_01_MUX M : 0|2@1+ (1.000000,0.000000) [0.000000|3.000000] "" Airbag Motor_BEV
 SG_ KS_Geheimnis_1 m0 : 8|8@1+ (1.000000,0.000000) [0.000000|255.000000] "" Airbag
 SG_ VIN_4 m1 : 8|8@1+ (1.000000,0.000000) [0.000000|255.000000] "" Airbag Motor_BEV
 SG_ VIN_11 m2 : 8|8@1+ (1.000000,0.000000) [0.000000|255.000000] "" Airbag Motor_BEV
 SG_ KS_Geheimnis_2 m0 : 16|8@1+ (1.000000,0.000000) [0.000000|255.000000] "" Airbag
 SG_ VIN_5 m1 : 16|8@1+ (1.000000,0.000000) [0.000000|255.000000] "" Airbag Motor_BEV
 SG_ VIN_12 m2 : 16|8@1+ (1.000000,0.000000) [0.000000|255.000000] "" Airbag Motor_BEV
 SG_ KS_Geheimnis_3 m0 : 24|8@1+ (1.000000,0.000000) [0.000000|255.000000] "" Airbag
 SG_ VIN_6 m1 : 24|8@1+ (1.000000,0.000000) [0.000000|255.000000] "" Airbag Motor_BEV
 SG_ VIN_13 m2 : 24|8@1+ (1.000000,0.000000) [0.000000|255.000000] "" Airbag Motor_BEV
 SG_ KS_Geheimnis_4 m0 : 32|8@1+ (1.000000,0.000000) [0.000000|255.000000] "" Airbag
 SG_ VIN_7 m1 : 32|8@1+ (1.000000,0.000000) [0.000000|255.000000] "" Airbag Motor_BEV
 SG_ VIN_14 m2 : 32|8@1+ (1.000000,0.000000) [0.000000|255.000000] "" Airbag Motor_BEV
 SG_ VIN_1 m0 : 40|8@1+ (1.000000,0.000000) [0.000000|255.000000] "" Airbag Motor_BEV
 SG_ VIN_8 m1 : 40|8@1+ (1.000000,0.000000) [0.000000|255.000000] "" Airbag Motor_BEV
 SG_ VIN_15 m2 : 40|8@1+ (1.000000,0.000000) [0.000000|255.000000] "" Airbag Motor_BEV
 SG_ VIN_2 m0 : 48|8@1+ (1.000000,0.000000) [0.000000|255.000000] "" Airbag Motor_BEV
 SG_ VIN_9 m1 : 48|8@1+ (1.000000,0.000000) [0.000000|255.000000] "" Airbag Motor_BEV
 SG_ VIN_16 m2 : 48|8@1+ (1.000000,0.000000) [0.000000|255.000000] "" Airbag Motor_BEV
 SG_ VIN_3 m0 : 56|8@1+ (1.000000,0.000000) [0.000000|255.000000] "" Airbag Motor_BEV
 SG_ VIN_10 m1 : 56|8@1+ (1.000000,0.000000) [0.000000|255.000000] "" Airbag Motor_BEV
 SG_ VIN_17 m2 : 56|8@1+ (1.000000,0.000000) [0.000000|255.000000] "" Airbag Motor_BEV

BO_ 261 VMM_01: 8 ICAS1_Gateway
 SG_ VMM_01_CRC  : 0|8@1+ (1.000000,0.000000) [0.000000|255.000000] "" Motor_BEV
 SG_ VMM_01_BZ  : 8|4@1+ (1.000000,0.000000) [0.000000|15.000000] "" Motor_BEV
 SG_ HMS_P_beibehalten_GE  : 12|2@1+ (1.000000,0.000000) [0.000000|3.000000] "" Vector__XXX
 SG_ VZM_Unterdrueckung_Antriebsmom  : 14|1@1+ (1.000000,0.000000) [0.000000|1.000000] "" Airbag Motor_BEV
 SG_ HMS_halten_nicht_verfuegbar  : 20|1@1+ (1.000000,0.000000) [0.000000|1.000000] "" Vector__XXX
 SG_ HMS_parken_nicht_verfuegbar  : 32|1@1+ (1.000000,0.000000) [0.000000|1.000000] "" Vector__XXX
 SG_ HMS_Anforderung_GE  : 33|3@1+ (1.000000,0.000000) [0.000000|7.000000] "" Vector__XXX
 SG_ HMS_Systemstatus  : 36|4@1+ (1.000000,0.000000) [0.000000|15.000000] "" Motor_BEV
 SG_ HMS_Stillstand  : 40|3@1+ (1.000000,0.000000) [0.000000|7.000000] "" Motor_BEV
 SG_ HMS_aktives_System  : 43|5@1+ (1.000000,0.000000) [0.000000|31.000000] "" Motor_BEV
 SG_ VMM_Inkonsistenz_GE  : 48|1@1+ (1.000000,0.000000) [0.000000|1.000000] "" Motor_BEV
 SG_ VMM_Inkonsistenz_HVLM  : 49|1@1+ (1.000000,0.000000) [0.000000|1.000000] "" Motor_BEV
 SG_ HMS_Fehlerstatus  : 50|3@1+ (1.000000,0.000000) [0.000000|7.000000] "" Vector__XXX
 SG_ HMS_Index_Haltemoment  : 53|1@1+ (1.000000,0.000000) [0.000000|1.000000] "" Motor_BEV
 SG_ HMS_Haltemoment  : 54|10@1+ (10.000000,0.000000) [0.000000|10210.000000] "Unit_NewtoMeter" Motor_BEV

BO_ 313 VMM_02: 32 ICAS1_Gateway
 SG_ VMM_02_CRC  : 0|8@1+ (1.000000,0.000000) [0.000000|255.000000] "" Motor_BEV
 SG_ VMM_02_BZ  : 8|4@1+ (1.000000,0.000000) [0.000000|15.000000] "" Motor_BEV
 SG_ VZM_aktiver_Basisservice  : 12|3@1+ (1.000000,0.000000) [0.000000|7.000000] "" Motor_BEV
 SG_ VZM_Anhalteweg_nicht_verfuegbar  : 15|1@1+ (1.000000,0.000000) [0.000000|1.000000] "" Motor_BEV
 SG_ VZM_Fahrer_bremst  : 16|1@1+ (1.000000,0.000000) [0.000000|1.000000] "" Motor_BEV
 SG_ VZM_QBit_Fahrer_bremst  : 17|1@1+ (1.000000,0.000000) [0.000000|1.000000] "" Motor_BEV
 SG_ VMM_MKB_codiert  : 18|1@1+ (1.000000,0.000000) [0.000000|1.000000] "" Airbag
 SG_ VMM_Inkonsistenz_EBKV  : 19|1@1+ (1.000000,0.000000) [0.000000|1.000000] "" Vector__XXX
 SG_ VMM_Notstopp_Status  : 20|3@1+ (1.000000,0.000000) [0.000000|7.000000] "" Motor_BEV
 SG_ VZM_Warnruck_nicht_verfuegbar  : 23|1@1+ (1.000000,0.000000) [0.000000|1.000000] "" Motor_BEV
 SG_ VZM_Warnruckeln_nicht_verfuegbar  : 24|1@1+ (1.000000,0.000000) [0.000000|1.000000] "" Motor_BEV
 SG_ VZM_Bkd_nicht_verfuegbar  : 25|1@1+ (1.000000,0.000000) [0.000000|1.000000] "" Motor_BEV
 SG_ VMM_Bremslicht_defekt  : 26|1@1+ (1.000000,0.000000) [0.000000|1.000000] "" Motor_BEV
 SG_ VZM_Fahrer_bremst_deutlich  : 27|1@1+ (1.000000,0.000000) [0.000000|1.000000] "" Airbag Motor_BEV
 SG_ VZM_TSK_SRBM_Anf  : 28|1@1+ (1.000000,0.000000) [0.000000|1.000000] "" Motor_BEV
 SG_ VZM_TSK_SRBM_nicht_verfuegbar  : 29|1@1+ (1.000000,0.000000) [0.000000|1.000000] "" Motor_BEV
 SG_ VZM_Verz_Reg_aktiv  : 30|5@1+ (1.000000,0.000000) [0.000000|31.000000] "" Motor_BEV
 SG_ VZM_Verz_Reg_nicht_verfuegbar  : 35|1@1+ (1.000000,0.000000) [0.000000|1.000000] "" Motor_BEV
 SG_ VMM_Inkonsistenz_KAS  : 36|1@1+ (1.000000,0.000000) [0.000000|1.000000] "" Motor_BEV
 SG_ VMM_Bremslicht_unplausibel  : 37|1@1+ (1.000000,0.000000) [0.000000|1.000000] "" Motor_BEV
 SG_ VMM_Inkonsistenz_ACC  : 38|1@1+ (1.000000,0.000000) [0.000000|1.000000] "" Motor_BEV
 SG_ VMM_Inkonsistenz_AWV_PCF  : 39|1@1+ (1.000000,0.000000) [0.000000|1.000000] "" Motor_BEV
 SG_ VMM_Inkonsistenz_ARA  : 40|1@1+ (1.000000,0.000000) [0.000000|1.000000] "" Motor_BEV
 SG_ VMM_Inkonsistenz_ParkAssist  : 41|1@1+ (1.000000,0.000000) [0.000000|1.000000] "" Motor_BEV
 SG_ VMM_Inkonsistenz_FAS_VK  : 42|1@1+ (1.000000,0.000000) [0.000000|1.000000] "" Motor_BEV
 SG_ VMM_Inkonsistenz_NV  : 43|1@1+ (1.000000,0.000000) [0.000000|1.000000] "" Motor_BEV
 SG_ VMM_Inkonsistenz_RCTA  : 44|1@1+ (1.000000,0.000000) [0.000000|1.000000] "" Motor_BEV
 SG_ VMM_Inkonsistenz_TSK  : 45|1@1+ (1.000000,0.000000) [0.000000|1.000000] "" Motor_BEV
 SG_ VMM_Inkonsistenz_MO  : 46|1@1+ (1.000000,0.000000) [0.000000|1.000000] "" Motor_BEV
 SG_ VMM_Inkonsistenz_AEB  : 47|1@1+ (1.000000,0.000000) [0.000000|1.000000] "" Vector__XXX
 SG_ VMM_Fahrer_Bremskraft_bestimmend  : 48|1@1+ (1.000000,0.000000) [0.000000|1.000000] "" Motor_BEV
 SG_ VMM_Inkonsistenz_EA  : 49|1@1+ (1.000000,0.000000) [0.000000|1.000000] "" Motor_BEV
 SG_ VZM_Status_Wegregelung  : 50|2@1+ (1.000000,0.000000) [0.000000|3.000000] "" Motor_BEV
 SG_ VZM_Verz_ASIL_Verfuegbarkeit  : 52|3@1+ (1.000000,0.000000) [0.000000|7.000000] "" Motor_BEV
 SG_ VZM_aktives_System  : 55|5@1+ (1.000000,0.000000) [0.000000|31.000000] "" Airbag Motor_BEV
 SG_ VZM_Verz_Begrenzung  : 60|1@1+ (1.000000,0.000000) [0.000000|1.000000] "" Motor_BEV
 SG_ VZM_Systemstatus  : 61|3@1+ (1.000000,0.000000) [0.000000|7.000000] "" Motor_BEV
 SG_ VZM_SRBM_Soll  : 64|12@1+ (8.000000,0.000000) [0.000000|32744.000000] "Unit_NewtoMeter" Motor_BEV
 SG_ VZM_SRBM_Ist  : 76|12@1+ (8.000000,0.000000) [0.000000|32744.000000] "Unit_NewtoMeter" Motor_BEV
 SG_ VZM_SRBM_max_Gradient  : 88|7@1+ (50.000000,0.000000) [0.000000|6250.000000] "Unit_NewtoMeterPerSecon" Motor_BEV
 SG_ VMM_Inkonsistenz_KAM  : 95|1@1+ (1.000000,0.000000) [0.000000|1.000000] "" Vector__XXX

BU_:  Airbag BAP_Tester ICAS1_Gateway ICAS1_KommunikationsServer LE1 LE2 Motor_BEV Schaltbetaetigung

BO_ 980 SMLS_01: 8 ICAS1_Gateway
 SG_ SMLS_01_CRC  : 0|8@1+ (1.000000,0.000000) [0.000000|255.000000] "" Vector__XXX
 SG_ SMLS_01_BZ  : 8|4@1+ (1.000000,0.000000) [0.000000|15.000000] "" Vector__XXX
 SG_ BH_Blinker_li  : 12|1@1+ (1.000000,0.000000) [0.000000|1.000000] "" Motor_BEV
 SG_ BH_Blinker_re  : 13|1@1+ (1.000000,0.000000) [0.000000|1.000000] "" Motor_BEV
 SG_ BH_Lichthupe  : 14|1@1+ (1.000000,0.000000) [0.000000|1.000000] "" Vector__XXX
 SG_ BH_Fernlicht  : 15|1@1+ (1.000000,0.000000) [0.000000|1.000000] "" Vector__XXX
 SG_ WH_Tipwischen  : 16|1@1+ (1.000000,0.000000) [0.000000|1.000000] "" Vector__XXX
 SG_ WH_Intervall  : 17|1@1+ (1.000000,0.000000) [0.000000|1.000000] "" Vector__XXX
 SG_ WH_WischerStufe1  : 18|1@1+ (1.000000,0.000000) [0.000000|1.000000] "" Vector__XXX
 SG_ WH_WischerStufe2  : 19|1@1+ (1.000000,0.000000) [0.000000|1.000000] "" Vector__XXX
 SG_ WH_Frontwaschen  : 20|1@1+ (1.000000,0.000000) [0.000000|1.000000] "" Vector__XXX
 SG_ WH_Heckintervall  : 21|1@1+ (1.000000,0.000000) [0.000000|1.000000] "" Vector__XXX
 SG_ WH_Heckwaschen  : 22|1@1+ (1.000000,0.000000) [0.000000|1.000000] "" Vector__XXX
 SG_ WH_Intervallstufen  : 23|4@1+ (1.000000,0.000000) [0.000000|15.000000] "" Vector__XXX
 SG_ FAS_Taster  : 27|1@1+ (1.000000,0.000000) [0.000000|1.000000] "" Vector__XXX
 SG_ FAS_Taster_Fehler  : 28|1@1+ (1.000000,0.000000) [0.000000|1.000000] "" Vector__XXX
 SG_ SMLS_Hupe  : 29|1@1+ (1.000000,0.000000) [0.000000|1.000000] "" Vector__XXX
 SG_ LRH_on_off  : 30|2@1+ (1.000000,0.000000) [0.000000|3.000000] "" Vector__XXX
 SG_ LSS_Tastencode  : 32|8@1+ (1.000000,0.000000) [0.000000|255.000000] "" Vector__XXX
 SG_ LRH_aktiv  : 40|1@1+ (1.000000,0.000000) [0.000000|1.000000] "" Vector__XXX
 SG_ SMLS_P_verriegelt  : 41|2@1+ (1.000000,0.000000) [0.000000|3.000000] "" Vector__XXX
 SG_ SMLS_P_verriegelt_plausibel  : 43|1@1+ (1.000000,0.000000) [0.000000|1.000000] "" Vector__XXX
 SG_ WH_SRA  : 44|1@1+ (1.000000,0.000000) [0.000000|1.000000] "" Vector__XXX
 SG_ WH_Wischer_Fehler  : 45|1@1+ (1.000000,0.000000) [0.000000|1.000000] "" Vector__XXX
 SG_ BH_Blinker_Fehler  : 46|1@1+ (1.000000,0.000000) [0.000000|1.000000] "" Vector__XXX
 SG_ SMLS_PTT  : 47|1@1+ (1.000000,0.000000) [0.000000|1.000000] "" Vector__XXX
 SG_ WH_Tipwischen_lang  : 48|1@1+ (1.000000,0.000000) [0.000000|1.000000] "" Vector__XXX

BO_ 2464153718 SOK_FoD_MO_01_Req_Chal_01: 8 Motor_BEV
 SG_ SOK_FoD_MO_01_Req_Challenge  : 0|64@1+ (1.000000,0.000000) [0.000000|18446744073709551616.000000] "Unit_None" ICAS1_Gateway

BO_ 2464284790 SOK_FoD_MO_01_Resp_Chal_01: 8 ICAS1_Gateway
 SG_ SOK_FoD_MO_01_Resp_Challenge  : 0|64@1+ (1.000000,0.000000) [0.000000|18446744073709551616.000000] "Unit_None" Motor_BEV

BO_ 1413 Systeminfo_01: 8 ICAS1_Gateway
 SG_ SI_Sammel_SG_Fehler  : 0|6@1+ (1.000000,0.000000) [0.000000|60.000000] "" Vector__XXX
 SG_ SI_P_Mode_gueltig  : 6|1@1+ (1.000000,0.000000) [0.000000|1.000000] "" Vector__XXX
 SG_ SI_Diagnose_Aktiv  : 7|1@1+ (1.000000,0.000000) [0.000000|1.000000] "" Vector__XXX
 SG_ SI_QRS_Mode  : 8|1@1+ (1.000000,0.000000) [0.000000|1.000000] "" Airbag Motor_BEV
 SG_ SI_T_Mode  : 9|1@1+ (1.000000,0.000000) [0.000000|1.000000] "" Motor_BEV
 SG_ SI_NWDF  : 10|1@1+ (1.000000,0.000000) [0.000000|1.000000] "" Vector__XXX
 SG_ SI_NWDF_gueltig  : 11|1@1+ (1.000000,0.000000) [0.000000|1.000000] "" Vector__XXX
 SG_ SI_Sammelfehler  : 12|1@1+ (1.000000,0.000000) [0.000000|1.000000] "" Vector__XXX
 SG_ GW_KD_Fehler  : 13|1@1+ (1.000000,0.000000) [0.000000|1.000000] "" Vector__XXX
 SG_ SI_T_Schutz  : 14|1@1+ (1.000000,0.000000) [0.000000|1.000000] "" Motor_BEV
 SG_ SI_P_Mode  : 15|1@1+ (1.000000,0.000000) [0.000000|1.000000] "" Vector__XXX
 SG_ SI_BUS_01  : 16|1@1+ (1.000000,0.000000) [0.000000|1.000000] "" Vector__XXX
 SG_ SI_BUS_02  : 17|1@1+ (1.000000,0.000000) [0.000000|1.000000] "" Vector__XXX
 SG_ SI_BUS_03  : 18|1@1+ (1.000000,0.000000) [0.000000|1.000000] "" Vector__XXX
 SG_ SI_BUS_04  : 19|1@1+ (1.000000,0.000000) [0.000000|1.000000] "" Vector__XXX
 SG_ SI_BUS_05  : 20|1@1+ (1.000000,0.000000) [0.000000|1.000000] "" Vector__XXX
 SG_ SI_BUS_06  : 21|1@1+ (1.000000,0.000000) [0.000000|1.000000] "" Vector__XXX
 SG_ SI_BUS_07  : 22|1@1+ (1.000000,0.000000) [0.000000|1.000000] "" Vector__XXX
 SG_ SI_BUS_08  : 23|1@1+ (1.000000,0.000000) [0.000000|1.000000] "" Vector__XXX
 SG_ SI_BUS_09  : 24|1@1+ (1.000000,0.000000) [0.000000|1.000000] "" Vector__XXX
 SG_ SI_BUS_10  : 25|1@1+ (1.000000,0.000000) [0.000000|1.000000] "" Vector__XXX
 SG_ SI_BUS_11  : 26|1@1+ (1.000000,0.000000) [0.000000|1.000000] "" Vector__XXX
 SG_ SI_BUS_12  : 27|1@1+ (1.000000,0.000000) [0.000000|1.000000] "" Vector__XXX
 SG_ SI_BUS_13  : 28|1@1+ (1.000000,0.000000) [0.000000|1.000000] "" Vector__XXX
 SG_ SI_BUS_14  : 29|1@1+ (1.000000,0.000000) [0.000000|1.000000] "" Vector__XXX
 SG_ SI_BUS_15  : 30|1@1+ (1.000000,0.000000) [0.000000|1.000000] "" Vector__XXX
 SG_ SI_Bus_Identifikation  : 32|8@1+ (1.000000,0.000000) [0.000000|255.000000] "" Vector__XXX
 SG_ SI_CAB_V10  : 40|24@1+ (1.000000,0.000000) [0.000000|16777215.000000] "" Vector__XXX

BO_ 2589283396 TSK_09: 8 Motor_BEV
 SG_ TSK_vMax_EfficiencyMode1  : 40|8@1+ (1.000000,0.000000) [0.000000|253.000000] "Unit_KiloMeterPerHour" ICAS1_Gateway
 SG_ TSK_vMax_EfficiencyMode2  : 48|8@1+ (1.000000,0.000000) [0.000000|253.000000] "Unit_KiloMeterPerHour" ICAS1_Gateway
 SG_ TSK_vMax_StandardMode  : 56|8@1+ (1.000000,0.000000) [0.000000|253.000000] "Unit_KiloMeterPerHour" ICAS1_Gateway

BO_ 1019 TSK_Ausrollkurve_01: 8 Motor_BEV
 SG_ TSK_Ausrollkurve_Schub_Reku_01 m0 : 0|7@1+ (2.000000,0.000000) [0.000000|252.000000] "Unit_KiloMeterPerHour" ICAS1_Gateway
 SG_ TSK_Ausrollkurve_Schub_Reku_05 m1 : 0|7@1+ (2.000000,0.000000) [0.000000|252.000000] "Unit_KiloMeterPerHour" ICAS1_Gateway
 SG_ TSK_Ausrollkurve_Schub_Reku_09 m2 : 0|7@1+ (2.000000,0.000000) [0.000000|252.000000] "Unit_KiloMeterPerHour" ICAS1_Gateway
 SG_ TSK_Ausrollkurve_Schub_Reku_13 m3 : 0|7@1+ (2.000000,0.000000) [0.000000|252.000000] "Unit_KiloMeterPerHour" ICAS1_Gateway
 SG_ TSK_Ausrollkurve_Schub_Reku_17 m4 : 0|7@1+ (2.000000,0.000000) [0.000000|252.000000] "Unit_KiloMeterPerHour" ICAS1_Gateway
 SG_ TSK_Ausrollkurve_Schub_Reku_02 m0 : 7|7@1+ (2.000000,0.000000) [0.000000|252.000000] "Unit_KiloMeterPerHour" ICAS1_Gateway
 SG_ TSK_Ausrollkurve_Schub_Reku_06 m1 : 7|7@1+ (2.000000,0.000000) [0.000000|252.000000] "Unit_KiloMeterPerHour" ICAS1_Gateway
 SG_ TSK_Ausrollkurve_Schub_Reku_10 m2 : 7|7@1+ (2.000000,0.000000) [0.000000|252.000000] "Unit_KiloMeterPerHour" ICAS1_Gateway
 SG_ TSK_Ausrollkurve_Schub_Reku_14 m3 : 7|7@1+ (2.000000,0.000000) [0.000000|252.000000] "Unit_KiloMeterPerHour" ICAS1_Gateway
 SG_ TSK_Ausrollkurve_Schub_Reku_18 m4 : 7|7@1+ (2.000000,0.000000) [0.000000|252.000000] "Unit_KiloMeterPerHour" ICAS1_Gateway
 SG_ TSK_Ausrollkurve_Schub_Reku_03 m0 : 14|7@1+ (2.000000,0.000000) [0.000000|252.000000] "Unit_KiloMeterPerHour" ICAS1_Gateway
 SG_ TSK_Ausrollkurve_Schub_Reku_07 m1 : 14|7@1+ (2.000000,0.000000) [0.000000|252.000000] "Unit_KiloMeterPerHour" ICAS1_Gateway
 SG_ TSK_Ausrollkurve_Schub_Reku_11 m2 : 14|7@1+ (2.000000,0.000000) [0.000000|252.000000] "Unit_KiloMeterPerHour" ICAS1_Gateway
 SG_ TSK_Ausrollkurve_Schub_Reku_15 m3 : 14|7@1+ (2.000000,0.000000) [0.000000|252.000000] "Unit_KiloMeterPerHour" ICAS1_Gateway
 SG_ TSK_Ausrollkurve_Schub_Reku_19 m4 : 14|7@1+ (2.000000,0.000000) [0.000000|252.000000] "Unit_KiloMeterPerHour" ICAS1_Gateway
 SG_ TSK_Ausrollkurve_Schub_Reku_04 m0 : 21|7@1+ (2.000000,0.000000) [0.000000|252.000000] "Unit_KiloMeterPerHour" ICAS1_Gateway
 SG_ TSK_Ausrollkurve_Schub_Reku_08 m1 : 21|7@1+ (2.000000,0.000000) [0.000000|252.000000] "Unit_KiloMeterPerHour" ICAS1_Gateway
 SG_ TSK_Ausrollkurve_Schub_Reku_12 m2 : 21|7@1+ (2.000000,0.000000) [0.000000|252.000000] "Unit_KiloMeterPerHour" ICAS1_Gateway
 SG_ TSK_Ausrollkurve_Schub_Reku_16 m3 : 21|7@1+ (2.000000,0.000000) [0.000000|252.000000] "Unit_KiloMeterPerHour" ICAS1_Gateway
 SG_ TSK_Ausrollkurve_Schub_Reku_20 m4 : 21|7@1+ (2.000000,0.000000) [0.000000|252.000000] "Unit_KiloMeterPerHour" ICAS1_Gateway
 SG_ TSK_Ausrollkurve_Segeln_01 m0 : 28|7@1+ (2.000000,0.000000) [0.000000|252.000000] "Unit_KiloMeterPerHour" ICAS1_Gateway
 SG_ TSK_Ausrollkurve_Segeln_05 m1 : 28|7@1+ (2.000000,0.000000) [0.000000|252.000000] "Unit_KiloMeterPerHour" ICAS1_Gateway
 SG_ TSK_Ausrollkurve_Segeln_09 m2 : 28|7@1+ (2.000000,0.000000) [0.000000|252.000000] "Unit_KiloMeterPerHour" ICAS1_Gateway
 SG_ TSK_Ausrollkurve_Segeln_13 m3 : 28|7@1+ (2.000000,0.000000) [0.000000|252.000000] "Unit_KiloMeterPerHour" ICAS1_Gateway
 SG_ TSK_Ausrollkurve_Segeln_17 m4 : 28|7@1+ (2.000000,0.000000) [0.000000|252.000000] "Unit_KiloMeterPerHour" ICAS1_Gateway
 SG_ TSK_Ausrollkurve_Segeln_02 m0 : 35|7@1+ (2.000000,0.000000) [0.000000|252.000000] "Unit_KiloMeterPerHour" ICAS1_Gateway
 SG_ TSK_Ausrollkurve_Segeln_06 m1 : 35|7@1+ (2.000000,0.000000) [0.000000|252.000000] "Unit_KiloMeterPerHour" ICAS1_Gateway
 SG_ TSK_Ausrollkurve_Segeln_10 m2 : 35|7@1+ (2.000000,0.000000) [0.000000|252.000000] "Unit_KiloMeterPerHour" ICAS1_Gateway
 SG_ TSK_Ausrollkurve_Segeln_14 m3 : 35|7@1+ (2.000000,0.000000) [0.000000|252.000000] "Unit_KiloMeterPerHour" ICAS1_Gateway
 SG_ TSK_Ausrollkurve_Segeln_18 m4 : 35|7@1+ (2.000000,0.000000) [0.000000|252.000000] "Unit_KiloMeterPerHour" ICAS1_Gateway
 SG_ TSK_Ausrollkurve_Segeln_03 m0 : 42|7@1+ (2.000000,0.000000) [0.000000|252.000000] "Unit_KiloMeterPerHour" ICAS1_Gateway
 SG_ TSK_Ausrollkurve_Segeln_07 m1 : 42|7@1+ (2.000000,0.000000) [0.000000|252.000000] "Unit_KiloMeterPerHour" ICAS1_Gateway
 SG_ TSK_Ausrollkurve_Segeln_11 m2 : 42|7@1+ (2.000000,0.000000) [0.000000|252.000000] "Unit_KiloMeterPerHour" ICAS1_Gateway
 SG_ TSK_Ausrollkurve_Segeln_15 m3 : 42|7@1+ (2.000000,0.000000) [0.000000|252.000000] "Unit_KiloMeterPerHour" ICAS1_Gateway
 SG_ TSK_Ausrollkurve_Segeln_19 m4 : 42|7@1+ (2.000000,0.000000) [0.000000|252.000000] "Unit_KiloMeterPerHour" ICAS1_Gateway
 SG_ TSK_Ausrollkurve_Segeln_04 m0 : 49|7@1+ (2.000000,0.000000) [0.000000|252.000000] "Unit_KiloMeterPerHour" ICAS1_Gateway
 SG_ TSK_Ausrollkurve_Segeln_08 m1 : 49|7@1+ (2.000000,0.000000) [0.000000|252.000000] "Unit_KiloMeterPerHour" ICAS1_Gateway
 SG_ TSK_Ausrollkurve_Segeln_12 m2 : 49|7@1+ (2.000000,0.000000) [0.000000|252.000000] "Unit_KiloMeterPerHour" ICAS1_Gateway
 SG_ TSK_Ausrollkurve_Segeln_16 m3 : 49|7@1+ (2.000000,0.000000) [0.000000|252.000000] "Unit_KiloMeterPerHour" ICAS1_Gateway
 SG_ TSK_Ausrollkurve_Segeln_20 m4 : 49|7@1+ (2.000000,0.000000) [0.000000|252.000000] "Unit_KiloMeterPerHour" ICAS1_Gateway
 SG_ TSK_Ausrollkurve_Mux M : 56|3@1+ (1.000000,0.000000) [0.000000|7.000000] "" ICAS1_Gateway
 SG_ TSK_Ausrollkurve_Reku  : 59|1@1+ (1.000000,0.000000) [0.000000|1.000000] "" ICAS1_Gateway
 SG_ TSK_Ausrollkurve_Schrittweite  : 60|1@1+ (1.000000,0.000000) [0.000000|1.000000] "" ICAS1_Gateway
 SG_ TSK_Ausrollkurve_Zaehler  : 61|2@1+ (1.000000,0.000000) [0.000000|3.000000] "" ICAS1_Gateway

BO_ 1716 VIN_01: 8 ICAS1_Gateway
 SG_ VIN_01_MUX M : 0|2@1+ (1.000000,0.000000) [0.000000|3.000000] "" Airbag Motor_BEV
 SG_ KS_Geheimnis_1 m0 : 8|8@1+ (1.000000,0.000000) [0.000000|255.000000] "" Airbag
 SG_ VIN_4 m1 : 8|8@1+ (1.000000,0.000000) [0.000000|255.000000] "" Airbag Motor_BEV
 SG_ VIN_11 m2 : 8|8@1+ (1.000000,0.000000) [0.000000|255.000000] "" Airbag Motor_BEV
 SG_ KS_Geheimnis_2 m0 : 16|8@1+ (1.000000,0.000000) [0.000000|255.000000] "" Airbag
 SG_ VIN_5 m1 : 16|8@1+ (1.000000,0.000000) [0.000000|255.000000] "" Airbag Motor_BEV
 SG_ VIN_12 m2 : 16|8@1+ (1.000000,0.000000) [0.000000|255.000000] "" Airbag Motor_BEV
 SG_ KS_Geheimnis_3 m0 : 24|8@1+ (1.000000,0.000000) [0.000000|255.000000] "" Airbag
 SG_ VIN_6 m1 : 24|8@1+ (1.000000,0.000000) [0.000000|255.000000] "" Airbag Motor_BEV
 SG_ VIN_13 m2 : 24|8@1+ (1.000000,0.000000) [0.000000|255.000000] "" Airbag Motor_BEV
 SG_ KS_Geheimnis_4 m0 : 32|8@1+ (1.000000,0.000000) [0.000000|255.000000] "" Airbag
 SG_ VIN_7 m1 : 32|8@1+ (1.000000,0.000000) [0.000000|255.000000] "" Airbag Motor_BEV
 SG_ VIN_14 m2 : 32|8@1+ (1.000000,0.000000) [0.000000|255.000000] "" Airbag Motor_BEV
 SG_ VIN_1 m0 : 40|8@1+ (1.000000,0.000000) [0.000000|255.000000] "" Airbag Motor_BEV
 SG_ VIN_8 m1 : 40|8@1+ (1.000000,0.000000) [0.000000|255.000000] "" Airbag Motor_BEV
 SG_ VIN_15 m2 : 40|8@1+ (1.000000,0.000000) [0.000000|255.000000] "" Airbag Motor_BEV
 SG_ VIN_2 m0 : 48|8@1+ (1.000000,0.000000) [0.000000|255.000000] "" Airbag Motor_BEV
 SG_ VIN_9 m1 : 48|8@1+ (1.000000,0.000000) [0.000000|255.000000] "" Airbag Motor_BEV
 SG_ VIN_16 m2 : 48|8@1+ (1.000000,0.000000) [0.000000|255.000000] "" Airbag Motor_BEV
 SG_ VIN_3 m0 : 56|8@1+ (1.000000,0.000000) [0.000000|255.000000] "" Airbag Motor_BEV
 SG_ VIN_10 m1 : 56|8@1+ (1.000000,0.000000) [0.000000|255.000000] "" Airbag Motor_BEV
 SG_ VIN_17 m2 : 56|8@1+ (1.000000,0.000000) [0.000000|255.000000] "" Airbag Motor_BEV

BO_ 261 VMM_01: 8 ICAS1_Gateway
 SG_ VMM_01_CRC  : 0|8@1+ (1.000000,0.000000) [0.000000|255.000000] "" Motor_BEV
 SG_ VMM_01_BZ  : 8|4@1+ (1.000000,0.000000) [0.000000|15.000000] "" Motor_BEV
 SG_ HMS_P_beibehalten_GE  : 12|2@1+ (1.000000,0.000000) [0.000000|3.000000] "" Vector__XXX
 SG_ VZM_Unterdrueckung_Antriebsmom  : 14|1@1+ (1.000000,0.000000) [0.000000|1.000000] "" Airbag Motor_BEV
 SG_ HMS_halten_nicht_verfuegbar  : 20|1@1+ (1.000000,0.000000) [0.000000|1.000000] "" Vector__XXX
 SG_ HMS_parken_nicht_verfuegbar  : 32|1@1+ (1.000000,0.000000) [0.000000|1.000000] "" Vector__XXX
 SG_ HMS_Anforderung_GE  : 33|3@1+ (1.000000,0.000000) [0.000000|7.000000] "" Vector__XXX
 SG_ HMS_Systemstatus  : 36|4@1+ (1.000000,0.000000) [0.000000|15.000000] "" Motor_BEV
 SG_ HMS_Stillstand  : 40|3@1+ (1.000000,0.000000) [0.000000|7.000000] "" Motor_BEV
 SG_ HMS_aktives_System  : 43|5@1+ (1.000000,0.000000) [0.000000|31.000000] "" Motor_BEV
 SG_ VMM_Inkonsistenz_GE  : 48|1@1+ (1.000000,0.000000) [0.000000|1.000000] "" Motor_BEV
 SG_ VMM_Inkonsistenz_HVLM  : 49|1@1+ (1.000000,0.000000) [0.000000|1.000000] "" Motor_BEV
 SG_ HMS_Fehlerstatus  : 50|3@1+ (1.000000,0.000000) [0.000000|7.000000] "" Vector__XXX
 SG_ HMS_Index_Haltemoment  : 53|1@1+ (1.000000,0.000000) [0.000000|1.000000] "" Motor_BEV
 SG_ HMS_Haltemoment  : 54|10@1+ (10.000000,0.000000) [0.000000|10210.000000] "Unit_NewtoMeter" Motor_BEV

BO_ 313 VMM_02: 32 ICAS1_Gateway
 SG_ VMM_02_CRC  : 0|8@1+ (1.000000,0.000000) [0.000000|255.000000] "" Motor_BEV
 SG_ VMM_02_BZ  : 8|4@1+ (1.000000,0.000000) [0.000000|15.000000] "" Motor_BEV
 SG_ VZM_aktiver_Basisservice  : 12|3@1+ (1.000000,0.000000) [0.000000|7.000000] "" Motor_BEV
 SG_ VZM_Anhalteweg_nicht_verfuegbar  : 15|1@1+ (1.000000,0.000000) [0.000000|1.000000] "" Motor_BEV
 SG_ VZM_Fahrer_bremst  : 16|1@1+ (1.000000,0.000000) [0.000000|1.000000] "" Motor_BEV
 SG_ VZM_QBit_Fahrer_bremst  : 17|1@1+ (1.000000,0.000000) [0.000000|1.000000] "" Motor_BEV
 SG_ VMM_MKB_codiert  : 18|1@1+ (1.000000,0.000000) [0.000000|1.000000] "" Airbag
 SG_ VMM_Inkonsistenz_EBKV  : 19|1@1+ (1.000000,0.000000) [0.000000|1.000000] "" Vector__XXX
 SG_ VMM_Notstopp_Status  : 20|3@1+ (1.000000,0.000000) [0.000000|7.000000] "" Motor_BEV
 SG_ VZM_Warnruck_nicht_verfuegbar  : 23|1@1+ (1.000000,0.000000) [0.000000|1.000000] "" Motor_BEV
 SG_ VZM_Warnruckeln_nicht_verfuegbar  : 24|1@1+ (1.000000,0.000000) [0.000000|1.000000] "" Motor_BEV
 SG_ VZM_Bkd_nicht_verfuegbar  : 25|1@1+ (1.000000,0.000000) [0.000000|1.000000] "" Motor_BEV
 SG_ VMM_Bremslicht_defekt  : 26|1@1+ (1.000000,0.000000) [0.000000|1.000000] "" Motor_BEV
 SG_ VZM_Fahrer_bremst_deutlich  : 27|1@1+ (1.000000,0.000000) [0.000000|1.000000] "" Airbag Motor_BEV
 SG_ VZM_TSK_SRBM_Anf  : 28|1@1+ (1.000000,0.000000) [0.000000|1.000000] "" Motor_BEV
 SG_ VZM_TSK_SRBM_nicht_verfuegbar  : 29|1@1+ (1.000000,0.000000) [0.000000|1.000000] "" Motor_BEV
 SG_ VZM_Verz_Reg_aktiv  : 30|5@1+ (1.000000,0.000000) [0.000000|31.000000] "" Motor_BEV
 SG_ VZM_Verz_Reg_nicht_verfuegbar  : 35|1@1+ (1.000000,0.000000) [0.000000|1.000000] "" Motor_BEV
 SG_ VMM_Inkonsistenz_KAS  : 36|1@1+ (1.000000,0.000000) [0.000000|1.000000] "" Motor_BEV
 SG_ VMM_Bremslicht_unplausibel  : 37|1@1+ (1.000000,0.000000) [0.000000|1.000000] "" Motor_BEV
 SG_ VMM_Inkonsistenz_ACC  : 38|1@1+ (1.000000,0.000000) [0.000000|1.000000] "" Motor_BEV
 SG_ VMM_Inkonsistenz_AWV_PCF  : 39|1@1+ (1.000000,0.000000) [0.000000|1.000000] "" Motor_BEV
 SG_ VMM_Inkonsistenz_ARA  : 40|1@1+ (1.000000,0.000000) [0.000000|1.000000] "" Motor_BEV
 SG_ VMM_Inkonsistenz_ParkAssist  : 41|1@1+ (1.000000,0.000000) [0.000000|1.000000] "" Motor_BEV
 SG_ VMM_Inkonsistenz_FAS_VK  : 42|1@1+ (1.000000,0.000000) [0.000000|1.000000] "" Motor_BEV
 SG_ VMM_Inkonsistenz_NV  : 43|1@1+ (1.000000,0.000000) [0.000000|1.000000] "" Motor_BEV
 SG_ VMM_Inkonsistenz_RCTA  : 44|1@1+ (1.000000,0.000000) [0.000000|1.000000] "" Motor_BEV
 SG_ VMM_Inkonsistenz_TSK  : 45|1@1+ (1.000000,0.000000) [0.000000|1.000000] "" Motor_BEV
 SG_ VMM_Inkonsistenz_MO  : 46|1@1+ (1.000000,0.000000) [0.000000|1.000000] "" Motor_BEV
 SG_ VMM_Inkonsistenz_AEB  : 47|1@1+ (1.000000,0.000000) [0.000000|1.000000] "" Vector__XXX
 SG_ VMM_Fahrer_Bremskraft_bestimmend  : 48|1@1+ (1.000000,0.000000) [0.000000|1.000000] "" Motor_BEV
 SG_ VMM_Inkonsistenz_EA  : 49|1@1+ (1.000000,0.000000) [0.000000|1.000000] "" Motor_BEV
 SG_ VZM_Status_Wegregelung  : 50|2@1+ (1.000000,0.000000) [0.000000|3.000000] "" Motor_BEV
 SG_ VZM_Verz_ASIL_Verfuegbarkeit  : 52|3@1+ (1.000000,0.000000) [0.000000|7.000000] "" Motor_BEV
 SG_ VZM_aktives_System  : 55|5@1+ (1.000000,0.000000) [0.000000|31.000000] "" Airbag Motor_BEV
 SG_ VZM_Verz_Begrenzung  : 60|1@1+ (1.000000,0.000000) [0.000000|1.000000] "" Motor_BEV
 SG_ VZM_Systemstatus  : 61|3@1+ (1.000000,0.000000) [0.000000|7.000000] "" Motor_BEV
 SG_ VZM_SRBM_Soll  : 64|12@1+ (8.000000,0.000000) [0.000000|32744.000000] "Unit_NewtoMeter" Motor_BEV
 SG_ VZM_SRBM_Ist  : 76|12@1+ (8.000000,0.000000) [0.000000|32744.000000] "Unit_NewtoMeter" Motor_BEV
 SG_ VZM_SRBM_max_Gradient  : 88|7@1+ (50.000000,0.000000) [0.000000|6250.000000] "Unit_NewtoMeterPerSecon" Motor_BEV
 SG_ VMM_Inkonsistenz_KAM  : 95|1@1+ (1.000000,0.000000) [0.000000|1.000000] "" Vector__XXX

BU_:  Airbag BAP_Tester ICAS1_Gateway ICAS1_KommunikationsServer LE1 LE2 Motor_BEV Schaltbetaetigung

BO_ 980 SMLS_01: 8 ICAS1_Gateway
 SG_ SMLS_01_CRC  : 0|8@1+ (1.000000,0.000000) [0.000000|255.000000] "" Vector__XXX
 SG_ SMLS_01_BZ  : 8|4@1+ (1.000000,0.000000) [0.000000|15.000000] "" Vector__XXX
 SG_ BH_Blinker_li  : 12|1@1+ (1.000000,0.000000) [0.000000|1.000000] "" Motor_BEV
 SG_ BH_Blinker_re  : 13|1@1+ (1.000000,0.000000) [0.000000|1.000000] "" Motor_BEV
 SG_ BH_Lichthupe  : 14|1@1+ (1.000000,0.000000) [0.000000|1.000000] "" Vector__XXX
 SG_ BH_Fernlicht  : 15|1@1+ (1.000000,0.000000) [0.000000|1.000000] "" Vector__XXX
 SG_ WH_Tipwischen  : 16|1@1+ (1.000000,0.000000) [0.000000|1.000000] "" Vector__XXX
 SG_ WH_Intervall  : 17|1@1+ (1.000000,0.000000) [0.000000|1.000000] "" Vector__XXX
 SG_ WH_WischerStufe1  : 18|1@1+ (1.000000,0.000000) [0.000000|1.000000] "" Vector__XXX
 SG_ WH_WischerStufe2  : 19|1@1+ (1.000000,0.000000) [0.000000|1.000000] "" Vector__XXX
 SG_ WH_Frontwaschen  : 20|1@1+ (1.000000,0.000000) [0.000000|1.000000] "" Vector__XXX
 SG_ WH_Heckintervall  : 21|1@1+ (1.000000,0.000000) [0.000000|1.000000] "" Vector__XXX
 SG_ WH_Heckwaschen  : 22|1@1+ (1.000000,0.000000) [0.000000|1.000000] "" Vector__XXX
 SG_ WH_Intervallstufen  : 23|4@1+ (1.000000,0.000000) [0.000000|15.000000] "" Vector__XXX
 SG_ FAS_Taster  : 27|1@1+ (1.000000,0.000000) [0.000000|1.000000] "" Vector__XXX
 SG_ FAS_Taster_Fehler  : 28|1@1+ (1.000000,0.000000) [0.000000|1.000000] "" Vector__XXX
 SG_ SMLS_Hupe  : 29|1@1+ (1.000000,0.000000) [0.000000|1.000000] "" Vector__XXX
 SG_ LRH_on_off  : 30|2@1+ (1.000000,0.000000) [0.000000|3.000000] "" Vector__XXX
 SG_ LSS_Tastencode  : 32|8@1+ (1.000000,0.000000) [0.000000|255.000000] "" Vector__XXX
 SG_ LRH_aktiv  : 40|1@1+ (1.000000,0.000000) [0.000000|1.000000] "" Vector__XXX
 SG_ SMLS_P_verriegelt  : 41|2@1+ (1.000000,0.000000) [0.000000|3.000000] "" Vector__XXX
 SG_ SMLS_P_verriegelt_plausibel  : 43|1@1+ (1.000000,0.000000) [0.000000|1.000000] "" Vector__XXX
 SG_ WH_SRA  : 44|1@1+ (1.000000,0.000000) [0.000000|1.000000] "" Vector__XXX
 SG_ WH_Wischer_Fehler  : 45|1@1+ (1.000000,0.000000) [0.000000|1.000000] "" Vector__XXX
 SG_ BH_Blinker_Fehler  : 46|1@1+ (1.000000,0.000000) [0.000000|1.000000] "" Vector__XXX
 SG_ SMLS_PTT  : 47|1@1+ (1.000000,0.000000) [0.000000|1.000000] "" Vector__XXX
 SG_ WH_Tipwischen_lang  : 48|1@1+ (1.000000,0.000000) [0.000000|1.000000] "" Vector__XXX

BO_ 2464153718 SOK_FoD_MO_01_Req_Chal_01: 8 Motor_BEV
 SG_ SOK_FoD_MO_01_Req_Challenge  : 0|64@1+ (1.000000,0.000000) [0.000000|18446744073709551616.000000] "Unit_None" ICAS1_Gateway

BO_ 2464284790 SOK_FoD_MO_01_Resp_Chal_01: 8 ICAS1_Gateway
 SG_ SOK_FoD_MO_01_Resp_Challenge  : 0|64@1+ (1.000000,0.000000) [0.000000|18446744073709551616.000000] "Unit_None" Motor_BEV

BO_ 1413 Systeminfo_01: 8 ICAS1_Gateway
 SG_ SI_Sammel_SG_Fehler  : 0|6@1+ (1.000000,0.000000) [0.000000|60.000000] "" Vector__XXX
 SG_ SI_P_Mode_gueltig  : 6|1@1+ (1.000000,0.000000) [0.000000|1.000000] "" Vector__XXX
 SG_ SI_Diagnose_Aktiv  : 7|1@1+ (1.000000,0.000000) [0.000000|1.000000] "" Vector__XXX
 SG_ SI_QRS_Mode  : 8|1@1+ (1.000000,0.000000) [0.000000|1.000000] "" Airbag Motor_BEV
 SG_ SI_T_Mode  : 9|1@1+ (1.000000,0.000000) [0.000000|1.000000] "" Motor_BEV
 SG_ SI_NWDF  : 10|1@1+ (1.000000,0.000000) [0.000000|1.000000] "" Vector__XXX
 SG_ SI_NWDF_gueltig  : 11|1@1+ (1.000000,0.000000) [0.000000|1.000000] "" Vector__XXX
 SG_ SI_Sammelfehler  : 12|1@1+ (1.000000,0.000000) [0.000000|1.000000] "" Vector__XXX
 SG_ GW_KD_Fehler  : 13|1@1+ (1.000000,0.000000) [0.000000|1.000000] "" Vector__XXX
 SG_ SI_T_Schutz  : 14|1@1+ (1.000000,0.000000) [0.000000|1.000000] "" Motor_BEV
 SG_ SI_P_Mode  : 15|1@1+ (1.000000,0.000000) [0.000000|1.000000] "" Vector__XXX
 SG_ SI_BUS_01  : 16|1@1+ (1.000000,0.000000) [0.000000|1.000000] "" Vector__XXX
 SG_ SI_BUS_02  : 17|1@1+ (1.000000,0.000000) [0.000000|1.000000] "" Vector__XXX
 SG_ SI_BUS_03  : 18|1@1+ (1.000000,0.000000) [0.000000|1.000000] "" Vector__XXX
 SG_ SI_BUS_04  : 19|1@1+ (1.000000,0.000000) [0.000000|1.000000] "" Vector__XXX
 SG_ SI_BUS_05  : 20|1@1+ (1.000000,0.000000) [0.000000|1.000000] "" Vector__XXX
 SG_ SI_BUS_06  : 21|1@1+ (1.000000,0.000000) [0.000000|1.000000] "" Vector__XXX
 SG_ SI_BUS_07  : 22|1@1+ (1.000000,0.000000) [0.000000|1.000000] "" Vector__XXX
 SG_ SI_BUS_08  : 23|1@1+ (1.000000,0.000000) [0.000000|1.000000] "" Vector__XXX
 SG_ SI_BUS_09  : 24|1@1+ (1.000000,0.000000) [0.000000|1.000000] "" Vector__XXX
 SG_ SI_BUS_10  : 25|1@1+ (1.000000,0.000000) [0.000000|1.000000] "" Vector__XXX
 SG_ SI_BUS_11  : 26|1@1+ (1.000000,0.000000) [0.000000|1.000000] "" Vector__XXX
 SG_ SI_BUS_12  : 27|1@1+ (1.000000,0.000000) [0.000000|1.000000] "" Vector__XXX
 SG_ SI_BUS_13  : 28|1@1+ (1.000000,0.000000) [0.000000|1.000000] "" Vector__XXX
 SG_ SI_BUS_14  : 29|1@1+ (1.000000,0.000000) [0.000000|1.000000] "" Vector__XXX
 SG_ SI_BUS_15  : 30|1@1+ (1.000000,0.000000) [0.000000|1.000000] "" Vector__XXX
 SG_ SI_Bus_Identifikation  : 32|8@1+ (1.000000,0.000000) [0.000000|255.000000] "" Vector__XXX
 SG_ SI_CAB_V10  : 40|24@1+ (1.000000,0.000000) [0.000000|16777215.000000] "" Vector__XXX

BO_ 2589283396 TSK_09: 8 Motor_BEV
 SG_ TSK_vMax_EfficiencyMode1  : 40|8@1+ (1.000000,0.000000) [0.000000|253.000000] "Unit_KiloMeterPerHour" ICAS1_Gateway
 SG_ TSK_vMax_EfficiencyMode2  : 48|8@1+ (1.000000,0.000000) [0.000000|253.000000] "Unit_KiloMeterPerHour" ICAS1_Gateway
 SG_ TSK_vMax_StandardMode  : 56|8@1+ (1.000000,0.000000) [0.000000|253.000000] "Unit_KiloMeterPerHour" ICAS1_Gateway

BO_ 1019 TSK_Ausrollkurve_01: 8 Motor_BEV
 SG_ TSK_Ausrollkurve_Schub_Reku_01 m0 : 0|7@1+ (2.000000,0.000000) [0.000000|252.000000] "Unit_KiloMeterPerHour" ICAS1_Gateway
 SG_ TSK_Ausrollkurve_Schub_Reku_05 m1 : 0|7@1+ (2.000000,0.000000) [0.000000|252.000000] "Unit_KiloMeterPerHour" ICAS1_Gateway
 SG_ TSK_Ausrollkurve_Schub_Reku_09 m2 : 0|7@1+ (2.000000,0.000000) [0.000000|252.000000] "Unit_KiloMeterPerHour" ICAS1_Gateway
 SG_ TSK_Ausrollkurve_Schub_Reku_13 m3 : 0|7@1+ (2.000000,0.000000) [0.000000|252.000000] "Unit_KiloMeterPerHour" ICAS1_Gateway
 SG_ TSK_Ausrollkurve_Schub_Reku_17 m4 : 0|7@1+ (2.000000,0.000000) [0.000000|252.000000] "Unit_KiloMeterPerHour" ICAS1_Gateway
 SG_ TSK_Ausrollkurve_Schub_Reku_02 m0 : 7|7@1+ (2.000000,0.000000) [0.000000|252.000000] "Unit_KiloMeterPerHour" ICAS1_Gateway
 SG_ TSK_Ausrollkurve_Schub_Reku_06 m1 : 7|7@1+ (2.000000,0.000000) [0.000000|252.000000] "Unit_KiloMeterPerHour" ICAS1_Gateway
 SG_ TSK_Ausrollkurve_Schub_Reku_10 m2 : 7|7@1+ (2.000000,0.000000) [0.000000|252.000000] "Unit_KiloMeterPerHour" ICAS1_Gateway
 SG_ TSK_Ausrollkurve_Schub_Reku_14 m3 : 7|7@1+ (2.000000,0.000000) [0.000000|252.000000] "Unit_KiloMeterPerHour" ICAS1_Gateway
 SG_ TSK_Ausrollkurve_Schub_Reku_18 m4 : 7|7@1+ (2.000000,0.000000) [0.000000|252.000000] "Unit_KiloMeterPerHour" ICAS1_Gateway
 SG_ TSK_Ausrollkurve_Schub_Reku_03 m0 : 14|7@1+ (2.000000,0.000000) [0.000000|252.000000] "Unit_KiloMeterPerHour" ICAS1_Gateway
 SG_ TSK_Ausrollkurve_Schub_Reku_07 m1 : 14|7@1+ (2.000000,0.000000) [0.000000|252.000000] "Unit_KiloMeterPerHour" ICAS1_Gateway
 SG_ TSK_Ausrollkurve_Schub_Reku_11 m2 : 14|7@1+ (2.000000,0.000000) [0.000000|252.000000] "Unit_KiloMeterPerHour" ICAS1_Gateway
 SG_ TSK_Ausrollkurve_Schub_Reku_15 m3 : 14|7@1+ (2.000000,0.000000) [0.000000|252.000000] "Unit_KiloMeterPerHour" ICAS1_Gateway
 SG_ TSK_Ausrollkurve_Schub_Reku_19 m4 : 14|7@1+ (2.000000,0.000000) [0.000000|252.000000] "Unit_KiloMeterPerHour" ICAS1_Gateway
 SG_ TSK_Ausrollkurve_Schub_Reku_04 m0 : 21|7@1+ (2.000000,0.000000) [0.000000|252.000000] "Unit_KiloMeterPerHour" ICAS1_Gateway
 SG_ TSK_Ausrollkurve_Schub_Reku_08 m1 : 21|7@1+ (2.000000,0.000000) [0.000000|252.000000] "Unit_KiloMeterPerHour" ICAS1_Gateway
 SG_ TSK_Ausrollkurve_Schub_Reku_12 m2 : 21|7@1+ (2.000000,0.000000) [0.000000|252.000000] "Unit_KiloMeterPerHour" ICAS1_Gateway
 SG_ TSK_Ausrollkurve_Schub_Reku_16 m3 : 21|7@1+ (2.000000,0.000000) [0.000000|252.000000] "Unit_KiloMeterPerHour" ICAS1_Gateway
 SG_ TSK_Ausrollkurve_Schub_Reku_20 m4 : 21|7@1+ (2.000000,0.000000) [0.000000|252.000000] "Unit_KiloMeterPerHour" ICAS1_Gateway
 SG_ TSK_Ausrollkurve_Segeln_01 m0 : 28|7@1+ (2.000000,0.000000) [0.000000|252.000000] "Unit_KiloMeterPerHour" ICAS1_Gateway
 SG_ TSK_Ausrollkurve_Segeln_05 m1 : 28|7@1+ (2.000000,0.000000) [0.000000|252.000000] "Unit_KiloMeterPerHour" ICAS1_Gateway
 SG_ TSK_Ausrollkurve_Segeln_09 m2 : 28|7@1+ (2.000000,0.000000) [0.000000|252.000000] "Unit_KiloMeterPerHour" ICAS1_Gateway
 SG_ TSK_Ausrollkurve_Segeln_13 m3 : 28|7@1+ (2.000000,0.000000) [0.000000|252.000000] "Unit_KiloMeterPerHour" ICAS1_Gateway
 SG_ TSK_Ausrollkurve_Segeln_17 m4 : 28|7@1+ (2.000000,0.000000) [0.000000|252.000000] "Unit_KiloMeterPerHour" ICAS1_Gateway
 SG_ TSK_Ausrollkurve_Segeln_02 m0 : 35|7@1+ (2.000000,0.000000) [0.000000|252.000000] "Unit_KiloMeterPerHour" ICAS1_Gateway
 SG_ TSK_Ausrollkurve_Segeln_06 m1 : 35|7@1+ (2.000000,0.000000) [0.000000|252.000000] "Unit_KiloMeterPerHour" ICAS1_Gateway
 SG_ TSK_Ausrollkurve_Segeln_10 m2 : 35|7@1+ (2.000000,0.000000) [0.000000|252.000000] "Unit_KiloMeterPerHour" ICAS1_Gateway
 SG_ TSK_Ausrollkurve_Segeln_14 m3 : 35|7@1+ (2.000000,0.000000) [0.000000|252.000000] "Unit_KiloMeterPerHour" ICAS1_Gateway
 SG_ TSK_Ausrollkurve_Segeln_18 m4 : 35|7@1+ (2.000000,0.000000) [0.000000|252.000000] "Unit_KiloMeterPerHour" ICAS1_Gateway
 SG_ TSK_Ausrollkurve_Segeln_03 m0 : 42|7@1+ (2.000000,0.000000) [0.000000|252.000000] "Unit_KiloMeterPerHour" ICAS1_Gateway
 SG_ TSK_Ausrollkurve_Segeln_07 m1 : 42|7@1+ (2.000000,0.000000) [0.000000|252.000000] "Unit_KiloMeterPerHour" ICAS1_Gateway
 SG_ TSK_Ausrollkurve_Segeln_11 m2 : 42|7@1+ (2.000000,0.000000) [0.000000|252.000000] "Unit_KiloMeterPerHour" ICAS1_Gateway
 SG_ TSK_Ausrollkurve_Segeln_15 m3 : 42|7@1+ (2.000000,0.000000) [0.000000|252.000000] "Unit_KiloMeterPerHour" ICAS1_Gateway
 SG_ TSK_Ausrollkurve_Segeln_19 m4 : 42|7@1+ (2.000000,0.000000) [0.000000|252.000000] "Unit_KiloMeterPerHour" ICAS1_Gateway
 SG_ TSK_Ausrollkurve_Segeln_04 m0 : 49|7@1+ (2.000000,0.000000) [0.000000|252.000000] "Unit_KiloMeterPerHour" ICAS1_Gateway
 SG_ TSK_Ausrollkurve_Segeln_08 m1 : 49|7@1+ (2.000000,0.000000) [0.000000|252.000000] "Unit_KiloMeterPerHour" ICAS1_Gateway
 SG_ TSK_Ausrollkurve_Segeln_12 m2 : 49|7@1+ (2.000000,0.000000) [0.000000|252.000000] "Unit_KiloMeterPerHour" ICAS1_Gateway
 SG_ TSK_Ausrollkurve_Segeln_16 m3 : 49|7@1+ (2.000000,0.000000) [0.000000|252.000000] "Unit_KiloMeterPerHour" ICAS1_Gateway
 SG_ TSK_Ausrollkurve_Segeln_20 m4 : 49|7@1+ (2.000000,0.000000) [0.000000|252.000000] "Unit_KiloMeterPerHour" ICAS1_Gateway
 SG_ TSK_Ausrollkurve_Mux M : 56|3@1+ (1.000000,0.000000) [0.000000|7.000000] "" ICAS1_Gateway
 SG_ TSK_Ausrollkurve_Reku  : 59|1@1+ (1.000000,0.000000) [0.000000|1.000000] "" ICAS1_Gateway
 SG_ TSK_Ausrollkurve_Schrittweite  : 60|1@1+ (1.000000,0.000000) [0.000000|1.000000] "" ICAS1_Gateway
 SG_ TSK_Ausrollkurve_Zaehler  : 61|2@1+ (1.000000,0.000000) [0.000000|3.000000] "" ICAS1_Gateway

BO_ 1716 VIN_01: 8 ICAS1_Gateway
 SG_ VIN_01_MUX M : 0|2@1+ (1.000000,0.000000) [0.000000|3.000000] "" Airbag Motor_BEV
 SG_ KS_Geheimnis_1 m0 : 8|8@1+ (1.000000,0.000000) [0.000000|255.000000] "" Airbag
 SG_ VIN_4 m1 : 8|8@1+ (1.000000,0.000000) [0.000000|255.000000] "" Airbag Motor_BEV
 SG_ VIN_11 m2 : 8|8@1+ (1.000000,0.000000) [0.000000|255.000000] "" Airbag Motor_BEV
 SG_ KS_Geheimnis_2 m0 : 16|8@1+ (1.000000,0.000000) [0.000000|255.000000] "" Airbag
 SG_ VIN_5 m1 : 16|8@1+ (1.000000,0.000000) [0.000000|255.000000] "" Airbag Motor_BEV
 SG_ VIN_12 m2 : 16|8@1+ (1.000000,0.000000) [0.000000|255.000000] "" Airbag Motor_BEV
 SG_ KS_Geheimnis_3 m0 : 24|8@1+ (1.000000,0.000000) [0.000000|255.000000] "" Airbag
 SG_ VIN_6 m1 : 24|8@1+ (1.000000,0.000000) [0.000000|255.000000] "" Airbag Motor_BEV
 SG_ VIN_13 m2 : 24|8@1+ (1.000000,0.000000) [0.000000|255.000000] "" Airbag Motor_BEV
 SG_ KS_Geheimnis_4 m0 : 32|8@1+ (1.000000,0.000000) [0.000000|255.000000] "" Airbag
 SG_ VIN_7 m1 : 32|8@1+ (1.000000,0.000000) [0.000000|255.000000] "" Airbag Motor_BEV
 SG_ VIN_14 m2 : 32|8@1+ (1.000000,0.000000) [0.000000|255.000000] "" Airbag Motor_BEV
 SG_ VIN_1 m0 : 40|8@1+ (1.000000,0.000000) [0.000000|255.000000] "" Airbag Motor_BEV
 SG_ VIN_8 m1 : 40|8@1+ (1.000000,0.000000) [0.000000|255.000000] "" Airbag Motor_BEV
 SG_ VIN_15 m2 : 40|8@1+ (1.000000,0.000000) [0.000000|255.000000] "" Airbag Motor_BEV
 SG_ VIN_2 m0 : 48|8@1+ (1.000000,0.000000) [0.000000|255.000000] "" Airbag Motor_BEV
 SG_ VIN_9 m1 : 48|8@1+ (1.000000,0.000000) [0.000000|255.000000] "" Airbag Motor_BEV
 SG_ VIN_16 m2 : 48|8@1+ (1.000000,0.000000) [0.000000|255.000000] "" Airbag Motor_BEV
 SG_ VIN_3 m0 : 56|8@1+ (1.000000,0.000000) [0.000000|255.000000] "" Airbag Motor_BEV
 SG_ VIN_10 m1 : 56|8@1+ (1.000000,0.000000) [0.000000|255.000000] "" Airbag Motor_BEV
 SG_ VIN_17 m2 : 56|8@1+ (1.000000,0.000000) [0.000000|255.000000] "" Airbag Motor_BEV

BO_ 261 VMM_01: 8 ICAS1_Gateway
 SG_ VMM_01_CRC  : 0|8@1+ (1.000000,0.000000) [0.000000|255.000000] "" Motor_BEV
 SG_ VMM_01_BZ  : 8|4@1+ (1.000000,0.000000) [0.000000|15.000000] "" Motor_BEV
 SG_ HMS_P_beibehalten_GE  : 12|2@1+ (1.000000,0.000000) [0.000000|3.000000] "" Vector__XXX
 SG_ VZM_Unterdrueckung_Antriebsmom  : 14|1@1+ (1.000000,0.000000) [0.000000|1.000000] "" Airbag Motor_BEV
 SG_ HMS_halten_nicht_verfuegbar  : 20|1@1+ (1.000000,0.000000) [0.000000|1.000000] "" Vector__XXX
 SG_ HMS_parken_nicht_verfuegbar  : 32|1@1+ (1.000000,0.000000) [0.000000|1.000000] "" Vector__XXX
 SG_ HMS_Anforderung_GE  : 33|3@1+ (1.000000,0.000000) [0.000000|7.000000] "" Vector__XXX
 SG_ HMS_Systemstatus  : 36|4@1+ (1.000000,0.000000) [0.000000|15.000000] "" Motor_BEV
 SG_ HMS_Stillstand  : 40|3@1+ (1.000000,0.000000) [0.000000|7.000000] "" Motor_BEV
 SG_ HMS_aktives_System  : 43|5@1+ (1.000000,0.000000) [0.000000|31.000000] "" Motor_BEV
 SG_ VMM_Inkonsistenz_GE  : 48|1@1+ (1.000000,0.000000) [0.000000|1.000000] "" Motor_BEV
 SG_ VMM_Inkonsistenz_HVLM  : 49|1@1+ (1.000000,0.000000) [0.000000|1.000000] "" Motor_BEV
 SG_ HMS_Fehlerstatus  : 50|3@1+ (1.000000,0.000000) [0.000000|7.000000] "" Vector__XXX
 SG_ HMS_Index_Haltemoment  : 53|1@1+ (1.000000,0.000000) [0.000000|1.000000] "" Motor_BEV
 SG_ HMS_Haltemoment  : 54|10@1+ (10.000000,0.000000) [0.000000|10210.000000] "Unit_NewtoMeter" Motor_BEV

BO_ 313 VMM_02: 32 ICAS1_Gateway
 SG_ VMM_02_CRC  : 0|8@1+ (1.000000,0.000000) [0.000000|255.000000] "" Motor_BEV
 SG_ VMM_02_BZ  : 8|4@1+ (1.000000,0.000000) [0.000000|15.000000] "" Motor_BEV
 SG_ VZM_aktiver_Basisservice  : 12|3@1+ (1.000000,0.000000) [0.000000|7.000000] "" Motor_BEV
 SG_ VZM_Anhalteweg_nicht_verfuegbar  : 15|1@1+ (1.000000,0.000000) [0.000000|1.000000] "" Motor_BEV
 SG_ VZM_Fahrer_bremst  : 16|1@1+ (1.000000,0.000000) [0.000000|1.000000] "" Motor_BEV
 SG_ VZM_QBit_Fahrer_bremst  : 17|1@1+ (1.000000,0.000000) [0.000000|1.000000] "" Motor_BEV
 SG_ VMM_MKB_codiert  : 18|1@1+ (1.000000,0.000000) [0.000000|1.000000] "" Airbag
 SG_ VMM_Inkonsistenz_EBKV  : 19|1@1+ (1.000000,0.000000) [0.000000|1.000000] "" Vector__XXX
 SG_ VMM_Notstopp_Status  : 20|3@1+ (1.000000,0.000000) [0.000000|7.000000] "" Motor_BEV
 SG_ VZM_Warnruck_nicht_verfuegbar  : 23|1@1+ (1.000000,0.000000) [0.000000|1.000000] "" Motor_BEV
 SG_ VZM_Warnruckeln_nicht_verfuegbar  : 24|1@1+ (1.000000,0.000000) [0.000000|1.000000] "" Motor_BEV
 SG_ VZM_Bkd_nicht_verfuegbar  : 25|1@1+ (1.000000,0.000000) [0.000000|1.000000] "" Motor_BEV
 SG_ VMM_Bremslicht_defekt  : 26|1@1+ (1.000000,0.000000) [0.000000|1.000000] "" Motor_BEV
 SG_ VZM_Fahrer_bremst_deutlich  : 27|1@1+ (1.000000,0.000000) [0.000000|1.000000] "" Airbag Motor_BEV
 SG_ VZM_TSK_SRBM_Anf  : 28|1@1+ (1.000000,0.000000) [0.000000|1.000000] "" Motor_BEV
 SG_ VZM_TSK_SRBM_nicht_verfuegbar  : 29|1@1+ (1.000000,0.000000) [0.000000|1.000000] "" Motor_BEV
 SG_ VZM_Verz_Reg_aktiv  : 30|5@1+ (1.000000,0.000000) [0.000000|31.000000] "" Motor_BEV
 SG_ VZM_Verz_Reg_nicht_verfuegbar  : 35|1@1+ (1.000000,0.000000) [0.000000|1.000000] "" Motor_BEV
 SG_ VMM_Inkonsistenz_KAS  : 36|1@1+ (1.000000,0.000000) [0.000000|1.000000] "" Motor_BEV
 SG_ VMM_Bremslicht_unplausibel  : 37|1@1+ (1.000000,0.000000) [0.000000|1.000000] "" Motor_BEV
 SG_ VMM_Inkonsistenz_ACC  : 38|1@1+ (1.000000,0.000000) [0.000000|1.000000] "" Motor_BEV
 SG_ VMM_Inkonsistenz_AWV_PCF  : 39|1@1+ (1.000000,0.000000) [0.000000|1.000000] "" Motor_BEV
 SG_ VMM_Inkonsistenz_ARA  : 40|1@1+ (1.000000,0.000000) [0.000000|1.000000] "" Motor_BEV
 SG_ VMM_Inkonsistenz_ParkAssist  : 41|1@1+ (1.000000,0.000000) [0.000000|1.000000] "" Motor_BEV
 SG_ VMM_Inkonsistenz_FAS_VK  : 42|1@1+ (1.000000,0.000000) [0.000000|1.000000] "" Motor_BEV
 SG_ VMM_Inkonsistenz_NV  : 43|1@1+ (1.000000,0.000000) [0.000000|1.000000] "" Motor_BEV
 SG_ VMM_Inkonsistenz_RCTA  : 44|1@1+ (1.000000,0.000000) [0.000000|1.000000] "" Motor_BEV
 SG_ VMM_Inkonsistenz_TSK  : 45|1@1+ (1.000000,0.000000) [0.000000|1.000000] "" Motor_BEV
 SG_ VMM_Inkonsistenz_MO  : 46|1@1+ (1.000000,0.000000) [0.000000|1.000000] "" Motor_BEV
 SG_ VMM_Inkonsistenz_AEB  : 47|1@1+ (1.000000,0.000000) [0.000000|1.000000] "" Vector__XXX
 SG_ VMM_Fahrer_Bremskraft_bestimmend  : 48|1@1+ (1.000000,0.000000) [0.000000|1.000000] "" Motor_BEV
 SG_ VMM_Inkonsistenz_EA  : 49|1@1+ (1.000000,0.000000) [0.000000|1.000000] "" Motor_BEV
 SG_ VZM_Status_Wegregelung  : 50|2@1+ (1.000000,0.000000) [0.000000|3.000000] "" Motor_BEV
 SG_ VZM_Verz_ASIL_Verfuegbarkeit  : 52|3@1+ (1.000000,0.000000) [0.000000|7.000000] "" Motor_BEV
 SG_ VZM_aktives_System  : 55|5@1+ (1.000000,0.000000) [0.000000|31.000000] "" Airbag Motor_BEV
 SG_ VZM_Verz_Begrenzung  : 60|1@1+ (1.000000,0.000000) [0.000000|1.000000] "" Motor_BEV
 SG_ VZM_Systemstatus  : 61|3@1+ (1.000000,0.000000) [0.000000|7.000000] "" Motor_BEV
 SG_ VZM_SRBM_Soll  : 64|12@1+ (8.000000,0.000000) [0.000000|32744.000000] "Unit_NewtoMeter" Motor_BEV
 SG_ VZM_SRBM_Ist  : 76|12@1+ (8.000000,0.000000) [0.000000|32744.000000] "Unit_NewtoMeter" Motor_BEV
 SG_ VZM_SRBM_max_Gradient  : 88|7@1+ (50.000000,0.000000) [0.000000|6250.000000] "Unit_NewtoMeterPerSecon" Motor_BEV
 SG_ VMM_Inkonsistenz_KAM  : 95|1@1+ (1.000000,0.000000) [0.000000|1.000000] "" Vector__XXX

BU_:  Airbag BAP_Tester ICAS1_Gateway ICAS1_KommunikationsServer LE1 LE2 Motor_BEV Schaltbetaetigung

BO_ 980 SMLS_01: 8 ICAS1_Gateway
 SG_ SMLS_01_CRC  : 0|8@1+ (1.000000,0.000000) [0.000000|255.000000] "" Vector__XXX
 SG_ SMLS_01_BZ  : 8|4@1+ (1.000000,0.000000) [0.000000|15.000000] "" Vector__XXX
 SG_ BH_Blinker_li  : 12|1@1+ (1.000000,0.000000) [0.000000|1.000000] "" Motor_BEV
 SG_ BH_Blinker_re  : 13|1@1+ (1.000000,0.000000) [0.000000|1.000000] "" Motor_BEV
 SG_ BH_Lichthupe  : 14|1@1+ (1.000000,0.000000) [0.000000|1.000000] "" Vector__XXX
 SG_ BH_Fernlicht  : 15|1@1+ (1.000000,0.000000) [0.000000|1.000000] "" Vector__XXX
 SG_ WH_Tipwischen  : 16|1@1+ (1.000000,0.000000) [0.000000|1.000000] "" Vector__XXX
 SG_ WH_Intervall  : 17|1@1+ (1.000000,0.000000) [0.000000|1.000000] "" Vector__XXX
 SG_ WH_WischerStufe1  : 18|1@1+ (1.000000,0.000000) [0.000000|1.000000] "" Vector__XXX
 SG_ WH_WischerStufe2  : 19|1@1+ (1.000000,0.000000) [0.000000|1.000000] "" Vector__XXX
 SG_ WH_Frontwaschen  : 20|1@1+ (1.000000,0.000000) [0.000000|1.000000] "" Vector__XXX
 SG_ WH_Heckintervall  : 21|1@1+ (1.000000,0.000000) [0.000000|1.000000] "" Vector__XXX
 SG_ WH_Heckwaschen  : 22|1@1+ (1.000000,0.000000) [0.000000|1.000000] "" Vector__XXX
 SG_ WH_Intervallstufen  : 23|4@1+ (1.000000,0.000000) [0.000000|15.000000] "" Vector__XXX
 SG_ FAS_Taster  : 27|1@1+ (1.000000,0.000000) [0.000000|1.000000] "" Vector__XXX
 SG_ FAS_Taster_Fehler  : 28|1@1+ (1.000000,0.000000) [0.000000|1.000000] "" Vector__XXX
 SG_ SMLS_Hupe  : 29|1@1+ (1.000000,0.000000) [0.000000|1.000000] "" Vector__XXX
 SG_ LRH_on_off  : 30|2@1+ (1.000000,0.000000) [0.000000|3.000000] "" Vector__XXX
 SG_ LSS_Tastencode  : 32|8@1+ (1.000000,0.000000) [0.000000|255.000000] "" Vector__XXX
 SG_ LRH_aktiv  : 40|1@1+ (1.000000,0.000000) [0.000000|1.000000] "" Vector__XXX
 SG_ SMLS_P_verriegelt  : 41|2@1+ (1.000000,0.000000) [0.000000|3.000000] "" Vector__XXX
 SG_ SMLS_P_verriegelt_plausibel  : 43|1@1+ (1.000000,0.000000) [0.000000|1.000000] "" Vector__XXX
 SG_ WH_SRA  : 44|1@1+ (1.000000,0.000000) [0.000000|1.000000] "" Vector__XXX
 SG_ WH_Wischer_Fehler  : 45|1@1+ (1.000000,0.000000) [0.000000|1.000000] "" Vector__XXX
 SG_ BH_Blinker_Fehler  : 46|1@1+ (1.000000,0.000000) [0.000000|1.000000] "" Vector__XXX
 SG_ SMLS_PTT  : 47|1@1+ (1.000000,0.000000) [0.000000|1.000000] "" Vector__XXX
 SG_ WH_Tipwischen_lang  : 48|1@1+ (1.000000,0.000000) [0.000000|1.000000] "" Vector__XXX

BO_ 2464153718 SOK_FoD_MO_01_Req_Chal_01: 8 Motor_BEV
 SG_ SOK_FoD_MO_01_Req_Challenge  : 0|64@1+ (1.000000,0.000000) [0.000000|18446744073709551616.000000] "Unit_None" ICAS1_Gateway

BO_ 2464284790 SOK_FoD_MO_01_Resp_Chal_01: 8 ICAS1_Gateway
 SG_ SOK_FoD_MO_01_Resp_Challenge  : 0|64@1+ (1.000000,0.000000) [0.000000|18446744073709551616.000000] "Unit_None" Motor_BEV

BO_ 1413 Systeminfo_01: 8 ICAS1_Gateway
 SG_ SI_Sammel_SG_Fehler  : 0|6@1+ (1.000000,0.000000) [0.000000|60.000000] "" Vector__XXX
 SG_ SI_P_Mode_gueltig  : 6|1@1+ (1.000000,0.000000) [0.000000|1.000000] "" Vector__XXX
 SG_ SI_Diagnose_Aktiv  : 7|1@1+ (1.000000,0.000000) [0.000000|1.000000] "" Vector__XXX
 SG_ SI_QRS_Mode  : 8|1@1+ (1.000000,0.000000) [0.000000|1.000000] "" Airbag Motor_BEV
 SG_ SI_T_Mode  : 9|1@1+ (1.000000,0.000000) [0.000000|1.000000] "" Motor_BEV
 SG_ SI_NWDF  : 10|1@1+ (1.000000,0.000000) [0.000000|1.000000] "" Vector__XXX
 SG_ SI_NWDF_gueltig  : 11|1@1+ (1.000000,0.000000) [0.000000|1.000000] "" Vector__XXX
 SG_ SI_Sammelfehler  : 12|1@1+ (1.000000,0.000000) [0.000000|1.000000] "" Vector__XXX
 SG_ GW_KD_Fehler  : 13|1@1+ (1.000000,0.000000) [0.000000|1.000000] "" Vector__XXX
 SG_ SI_T_Schutz  : 14|1@1+ (1.000000,0.000000) [0.000000|1.000000] "" Motor_BEV
 SG_ SI_P_Mode  : 15|1@1+ (1.000000,0.000000) [0.000000|1.000000] "" Vector__XXX
 SG_ SI_BUS_01  : 16|1@1+ (1.000000,0.000000) [0.000000|1.000000] "" Vector__XXX
 SG_ SI_BUS_02  : 17|1@1+ (1.000000,0.000000) [0.000000|1.000000] "" Vector__XXX
 SG_ SI_BUS_03  : 18|1@1+ (1.000000,0.000000) [0.000000|1.000000] "" Vector__XXX
 SG_ SI_BUS_04  : 19|1@1+ (1.000000,0.000000) [0.000000|1.000000] "" Vector__XXX
 SG_ SI_BUS_05  : 20|1@1+ (1.000000,0.000000) [0.000000|1.000000] "" Vector__XXX
 SG_ SI_BUS_06  : 21|1@1+ (1.000000,0.000000) [0.000000|1.000000] "" Vector__XXX
 SG_ SI_BUS_07  : 22|1@1+ (1.000000,0.000000) [0.000000|1.000000] "" Vector__XXX
 SG_ SI_BUS_08  : 23|1@1+ (1.000000,0.000000) [0.000000|1.000000] "" Vector__XXX
 SG_ SI_BUS_09  : 24|1@1+ (1.000000,0.000000) [0.000000|1.000000] "" Vector__XXX
 SG_ SI_BUS_10  : 25|1@1+ (1.000000,0.000000) [0.000000|1.000000] "" Vector__XXX
 SG_ SI_BUS_11  : 26|1@1+ (1.000000,0.000000) [0.000000|1.000000] "" Vector__XXX
 SG_ SI_BUS_12  : 27|1@1+ (1.000000,0.000000) [0.000000|1.000000] "" Vector__XXX
 SG_ SI_BUS_13  : 28|1@1+ (1.000000,0.000000) [0.000000|1.000000] "" Vector__XXX
 SG_ SI_BUS_14  : 29|1@1+ (1.000000,0.000000) [0.000000|1.000000] "" Vector__XXX
 SG_ SI_BUS_15  : 30|1@1+ (1.000000,0.000000) [0.000000|1.000000] "" Vector__XXX
 SG_ SI_Bus_Identifikation  : 32|8@1+ (1.000000,0.000000) [0.000000|255.000000] "" Vector__XXX
 SG_ SI_CAB_V10  : 40|24@1+ (1.000000,0.000000) [0.000000|16777215.000000] "" Vector__XXX

BO_ 2589283396 TSK_09: 8 Motor_BEV
 SG_ TSK_vMax_EfficiencyMode1  : 40|8@1+ (1.000000,0.000000) [0.000000|253.000000] "Unit_KiloMeterPerHour" ICAS1_Gateway
 SG_ TSK_vMax_EfficiencyMode2  : 48|8@1+ (1.000000,0.000000) [0.000000|253.000000] "Unit_KiloMeterPerHour" ICAS1_Gateway
 SG_ TSK_vMax_StandardMode  : 56|8@1+ (1.000000,0.000000) [0.000000|253.000000] "Unit_KiloMeterPerHour" ICAS1_Gateway

BO_ 1019 TSK_Ausrollkurve_01: 8 Motor_BEV
 SG_ TSK_Ausrollkurve_Schub_Reku_01 m0 : 0|7@1+ (2.000000,0.000000) [0.000000|252.000000] "Unit_KiloMeterPerHour" ICAS1_Gateway
 SG_ TSK_Ausrollkurve_Schub_Reku_05 m1 : 0|7@1+ (2.000000,0.000000) [0.000000|252.000000] "Unit_KiloMeterPerHour" ICAS1_Gateway
 SG_ TSK_Ausrollkurve_Schub_Reku_09 m2 : 0|7@1+ (2.000000,0.000000) [0.000000|252.000000] "Unit_KiloMeterPerHour" ICAS1_Gateway
 SG_ TSK_Ausrollkurve_Schub_Reku_13 m3 : 0|7@1+ (2.000000,0.000000) [0.000000|252.000000] "Unit_KiloMeterPerHour" ICAS1_Gateway
 SG_ TSK_Ausrollkurve_Schub_Reku_17 m4 : 0|7@1+ (2.000000,0.000000) [0.000000|252.000000] "Unit_KiloMeterPerHour" ICAS1_Gateway
 SG_ TSK_Ausrollkurve_Schub_Reku_02 m0 : 7|7@1+ (2.000000,0.000000) [0.000000|252.000000] "Unit_KiloMeterPerHour" ICAS1_Gateway
 SG_ TSK_Ausrollkurve_Schub_Reku_06 m1 : 7|7@1+ (2.000000,0.000000) [0.000000|252.000000] "Unit_KiloMeterPerHour" ICAS1_Gateway
 SG_ TSK_Ausrollkurve_Schub_Reku_10 m2 : 7|7@1+ (2.000000,0.000000) [0.000000|252.000000] "Unit_KiloMeterPerHour" ICAS1_Gateway
 SG_ TSK_Ausrollkurve_Schub_Reku_14 m3 : 7|7@1+ (2.000000,0.000000) [0.000000|252.000000] "Unit_KiloMeterPerHour" ICAS1_Gateway
 SG_ TSK_Ausrollkurve_Schub_Reku_18 m4 : 7|7@1+ (2.000000,0.000000) [0.000000|252.000000] "Unit_KiloMeterPerHour" ICAS1_Gateway
 SG_ TSK_Ausrollkurve_Schub_Reku_03 m0 : 14|7@1+ (2.000000,0.000000) [0.000000|252.000000] "Unit_KiloMeterPerHour" ICAS1_Gateway
 SG_ TSK_Ausrollkurve_Schub_Reku_07 m1 : 14|7@1+ (2.000000,0.000000) [0.000000|252.000000] "Unit_KiloMeterPerHour" ICAS1_Gateway
 SG_ TSK_Ausrollkurve_Schub_Reku_11 m2 : 14|7@1+ (2.000000,0.000000) [0.000000|252.000000] "Unit_KiloMeterPerHour" ICAS1_Gateway
 SG_ TSK_Ausrollkurve_Schub_Reku_15 m3 : 14|7@1+ (2.000000,0.000000) [0.000000|252.000000] "Unit_KiloMeterPerHour" ICAS1_Gateway
 SG_ TSK_Ausrollkurve_Schub_Reku_19 m4 : 14|7@1+ (2.000000,0.000000) [0.000000|252.000000] "Unit_KiloMeterPerHour" ICAS1_Gateway
 SG_ TSK_Ausrollkurve_Schub_Reku_04 m0 : 21|7@1+ (2.000000,0.000000) [0.000000|252.000000] "Unit_KiloMeterPerHour" ICAS1_Gateway
 SG_ TSK_Ausrollkurve_Schub_Reku_08 m1 : 21|7@1+ (2.000000,0.000000) [0.000000|252.000000] "Unit_KiloMeterPerHour" ICAS1_Gateway
 SG_ TSK_Ausrollkurve_Schub_Reku_12 m2 : 21|7@1+ (2.000000,0.000000) [0.000000|252.000000] "Unit_KiloMeterPerHour" ICAS1_Gateway
 SG_ TSK_Ausrollkurve_Schub_Reku_16 m3 : 21|7@1+ (2.000000,0.000000) [0.000000|252.000000] "Unit_KiloMeterPerHour" ICAS1_Gateway
 SG_ TSK_Ausrollkurve_Schub_Reku_20 m4 : 21|7@1+ (2.000000,0.000000) [0.000000|252.000000] "Unit_KiloMeterPerHour" ICAS1_Gateway
 SG_ TSK_Ausrollkurve_Segeln_01 m0 : 28|7@1+ (2.000000,0.000000) [0.000000|252.000000] "Unit_KiloMeterPerHour" ICAS1_Gateway
 SG_ TSK_Ausrollkurve_Segeln_05 m1 : 28|7@1+ (2.000000,0.000000) [0.000000|252.000000] "Unit_KiloMeterPerHour" ICAS1_Gateway
 SG_ TSK_Ausrollkurve_Segeln_09 m2 : 28|7@1+ (2.000000,0.000000) [0.000000|252.000000] "Unit_KiloMeterPerHour" ICAS1_Gateway
 SG_ TSK_Ausrollkurve_Segeln_13 m3 : 28|7@1+ (2.000000,0.000000) [0.000000|252.000000] "Unit_KiloMeterPerHour" ICAS1_Gateway
 SG_ TSK_Ausrollkurve_Segeln_17 m4 : 28|7@1+ (2.000000,0.000000) [0.000000|252.000000] "Unit_KiloMeterPerHour" ICAS1_Gateway
 SG_ TSK_Ausrollkurve_Segeln_02 m0 : 35|7@1+ (2.000000,0.000000) [0.000000|252.000000] "Unit_KiloMeterPerHour" ICAS1_Gateway
 SG_ TSK_Ausrollkurve_Segeln_06 m1 : 35|7@1+ (2.000000,0.000000) [0.000000|252.000000] "Unit_KiloMeterPerHour" ICAS1_Gateway
 SG_ TSK_Ausrollkurve_Segeln_10 m2 : 35|7@1+ (2.000000,0.000000) [0.000000|252.000000] "Unit_KiloMeterPerHour" ICAS1_Gateway
 SG_ TSK_Ausrollkurve_Segeln_14 m3 : 35|7@1+ (2.000000,0.000000) [0.000000|252.000000] "Unit_KiloMeterPerHour" ICAS1_Gateway
 SG_ TSK_Ausrollkurve_Segeln_18 m4 : 35|7@1+ (2.000000,0.000000) [0.000000|252.000000] "Unit_KiloMeterPerHour" ICAS1_Gateway
 SG_ TSK_Ausrollkurve_Segeln_03 m0 : 42|7@1+ (2.000000,0.000000) [0.000000|252.000000] "Unit_KiloMeterPerHour" ICAS1_Gateway
 SG_ TSK_Ausrollkurve_Segeln_07 m1 : 42|7@1+ (2.000000,0.000000) [0.000000|252.000000] "Unit_KiloMeterPerHour" ICAS1_Gateway
 SG_ TSK_Ausrollkurve_Segeln_11 m2 : 42|7@1+ (2.000000,0.000000) [0.000000|252.000000] "Unit_KiloMeterPerHour" ICAS1_Gateway
 SG_ TSK_Ausrollkurve_Segeln_15 m3 : 42|7@1+ (2.000000,0.000000) [0.000000|252.000000] "Unit_KiloMeterPerHour" ICAS1_Gateway
 SG_ TSK_Ausrollkurve_Segeln_19 m4 : 42|7@1+ (2.000000,0.000000) [0.000000|252.000000] "Unit_KiloMeterPerHour" ICAS1_Gateway
 SG_ TSK_Ausrollkurve_Segeln_04 m0 : 49|7@1+ (2.000000,0.000000) [0.000000|252.000000] "Unit_KiloMeterPerHour" ICAS1_Gateway
 SG_ TSK_Ausrollkurve_Segeln_08 m1 : 49|7@1+ (2.000000,0.000000) [0.000000|252.000000] "Unit_KiloMeterPerHour" ICAS1_Gateway
 SG_ TSK_Ausrollkurve_Segeln_12 m2 : 49|7@1+ (2.000000,0.000000) [0.000000|252.000000] "Unit_KiloMeterPerHour" ICAS1_Gateway
 SG_ TSK_Ausrollkurve_Segeln_16 m3 : 49|7@1+ (2.000000,0.000000) [0.000000|252.000000] "Unit_KiloMeterPerHour" ICAS1_Gateway
 SG_ TSK_Ausrollkurve_Segeln_20 m4 : 49|7@1+ (2.000000,0.000000) [0.000000|252.000000] "Unit_KiloMeterPerHour" ICAS1_Gateway
 SG_ TSK_Ausrollkurve_Mux M : 56|3@1+ (1.000000,0.000000) [0.000000|7.000000] "" ICAS1_Gateway
 SG_ TSK_Ausrollkurve_Reku  : 59|1@1+ (1.000000,0.000000) [0.000000|1.000000] "" ICAS1_Gateway
 SG_ TSK_Ausrollkurve_Schrittweite  : 60|1@1+ (1.000000,0.000000) [0.000000|1.000000] "" ICAS1_Gateway
 SG_ TSK_Ausrollkurve_Zaehler  : 61|2@1+ (1.000000,0.000000) [0.000000|3.000000] "" ICAS1_Gateway

BO_ 1716 VIN_01: 8 ICAS1_Gateway
 SG_ VIN_01_MUX M : 0|2@1+ (1.000000,0.000000) [0.000000|3.000000] "" Airbag Motor_BEV
 SG_ KS_Geheimnis_1 m0 : 8|8@1+ (1.000000,0.000000) [0.000000|255.000000] "" Airbag
 SG_ VIN_4 m1 : 8|8@1+ (1.000000,0.000000) [0.000000|255.000000] "" Airbag Motor_BEV
 SG_ VIN_11 m2 : 8|8@1+ (1.000000,0.000000) [0.000000|255.000000] "" Airbag Motor_BEV
 SG_ KS_Geheimnis_2 m0 : 16|8@1+ (1.000000,0.000000) [0.000000|255.000000] "" Airbag
 SG_ VIN_5 m1 : 16|8@1+ (1.000000,0.000000) [0.000000|255.000000] "" Airbag Motor_BEV
 SG_ VIN_12 m2 : 16|8@1+ (1.000000,0.000000) [0.000000|255.000000] "" Airbag Motor_BEV
 SG_ KS_Geheimnis_3 m0 : 24|8@1+ (1.000000,0.000000) [0.000000|255.000000] "" Airbag
 SG_ VIN_6 m1 : 24|8@1+ (1.000000,0.000000) [0.000000|255.000000] "" Airbag Motor_BEV
 SG_ VIN_13 m2 : 24|8@1+ (1.000000,0.000000) [0.000000|255.000000] "" Airbag Motor_BEV
 SG_ KS_Geheimnis_4 m0 : 32|8@1+ (1.000000,0.000000) [0.000000|255.000000] "" Airbag
 SG_ VIN_7 m1 : 32|8@1+ (1.000000,0.000000) [0.000000|255.000000] "" Airbag Motor_BEV
 SG_ VIN_14 m2 : 32|8@1+ (1.000000,0.000000) [0.000000|255.000000] "" Airbag Motor_BEV
 SG_ VIN_1 m0 : 40|8@1+ (1.000000,0.000000) [0.000000|255.000000] "" Airbag Motor_BEV
 SG_ VIN_8 m1 : 40|8@1+ (1.000000,0.000000) [0.000000|255.000000] "" Airbag Motor_BEV
 SG_ VIN_15 m2 : 40|8@1+ (1.000000,0.000000) [0.000000|255.000000] "" Airbag Motor_BEV
 SG_ VIN_2 m0 : 48|8@1+ (1.000000,0.000000) [0.000000|255.000000] "" Airbag Motor_BEV
 SG_ VIN_9 m1 : 48|8@1+ (1.000000,0.000000) [0.000000|255.000000] "" Airbag Motor_BEV
 SG_ VIN_16 m2 : 48|8@1+ (1.000000,0.000000) [0.000000|255.000000] "" Airbag Motor_BEV
 SG_ VIN_3 m0 : 56|8@1+ (1.000000,0.000000) [0.000000|255.000000] "" Airbag Motor_BEV
 SG_ VIN_10 m1 : 56|8@1+ (1.000000,0.000000) [0.000000|255.000000] "" Airbag Motor_BEV
 SG_ VIN_17 m2 : 56|8@1+ (1.000000,0.000000) [0.000000|255.000000] "" Airbag Motor_BEV

BO_ 261 VMM_01: 8 ICAS1_Gateway
 SG_ VMM_01_CRC  : 0|8@1+ (1.000000,0.000000) [0.000000|255.000000] "" Motor_BEV
 SG_ VMM_01_BZ  : 8|4@1+ (1.000000,0.000000) [0.000000|15.000000] "" Motor_BEV
 SG_ HMS_P_beibehalten_GE  : 12|2@1+ (1.000000,0.000000) [0.000000|3.000000] "" Vector__XXX
 SG_ VZM_Unterdrueckung_Antriebsmom  : 14|1@1+ (1.000000,0.000000) [0.000000|1.000000] "" Airbag Motor_BEV
 SG_ HMS_halten_nicht_verfuegbar  : 20|1@1+ (1.000000,0.000000) [0.000000|1.000000] "" Vector__XXX
 SG_ HMS_parken_nicht_verfuegbar  : 32|1@1+ (1.000000,0.000000) [0.000000|1.000000] "" Vector__XXX
 SG_ HMS_Anforderung_GE  : 33|3@1+ (1.000000,0.000000) [0.000000|7.000000] "" Vector__XXX
 SG_ HMS_Systemstatus  : 36|4@1+ (1.000000,0.000000) [0.000000|15.000000] "" Motor_BEV
 SG_ HMS_Stillstand  : 40|3@1+ (1.000000,0.000000) [0.000000|7.000000] "" Motor_BEV
 SG_ HMS_aktives_System  : 43|5@1+ (1.000000,0.000000) [0.000000|31.000000] "" Motor_BEV
 SG_ VMM_Inkonsistenz_GE  : 48|1@1+ (1.000000,0.000000) [0.000000|1.000000] "" Motor_BEV
 SG_ VMM_Inkonsistenz_HVLM  : 49|1@1+ (1.000000,0.000000) [0.000000|1.000000] "" Motor_BEV
 SG_ HMS_Fehlerstatus  : 50|3@1+ (1.000000,0.000000) [0.000000|7.000000] "" Vector__XXX
 SG_ HMS_Index_Haltemoment  : 53|1@1+ (1.000000,0.000000) [0.000000|1.000000] "" Motor_BEV
 SG_ HMS_Haltemoment  : 54|10@1+ (10.000000,0.000000) [0.000000|10210.000000] "Unit_NewtoMeter" Motor_BEV

BO_ 313 VMM_02: 32 ICAS1_Gateway
 SG_ VMM_02_CRC  : 0|8@1+ (1.000000,0.000000) [0.000000|255.000000] "" Motor_BEV
 SG_ VMM_02_BZ  : 8|4@1+ (1.000000,0.000000) [0.000000|15.000000] "" Motor_BEV
 SG_ VZM_aktiver_Basisservice  : 12|3@1+ (1.000000,0.000000) [0.000000|7.000000] "" Motor_BEV
 SG_ VZM_Anhalteweg_nicht_verfuegbar  : 15|1@1+ (1.000000,0.000000) [0.000000|1.000000] "" Motor_BEV
 SG_ VZM_Fahrer_bremst  : 16|1@1+ (1.000000,0.000000) [0.000000|1.000000] "" Motor_BEV
 SG_ VZM_QBit_Fahrer_bremst  : 17|1@1+ (1.000000,0.000000) [0.000000|1.000000] "" Motor_BEV
 SG_ VMM_MKB_codiert  : 18|1@1+ (1.000000,0.000000) [0.000000|1.000000] "" Airbag
 SG_ VMM_Inkonsistenz_EBKV  : 19|1@1+ (1.000000,0.000000) [0.000000|1.000000] "" Vector__XXX
 SG_ VMM_Notstopp_Status  : 20|3@1+ (1.000000,0.000000) [0.000000|7.000000] "" Motor_BEV
 SG_ VZM_Warnruck_nicht_verfuegbar  : 23|1@1+ (1.000000,0.000000) [0.000000|1.000000] "" Motor_BEV
 SG_ VZM_Warnruckeln_nicht_verfuegbar  : 24|1@1+ (1.000000,0.000000) [0.000000|1.000000] "" Motor_BEV
 SG_ VZM_Bkd_nicht_verfuegbar  : 25|1@1+ (1.000000,0.000000) [0.000000|1.000000] "" Motor_BEV
 SG_ VMM_Bremslicht_defekt  : 26|1@1+ (1.000000,0.000000) [0.000000|1.000000] "" Motor_BEV
 SG_ VZM_Fahrer_bremst_deutlich  : 27|1@1+ (1.000000,0.000000) [0.000000|1.000000] "" Airbag Motor_BEV
 SG_ VZM_TSK_SRBM_Anf  : 28|1@1+ (1.000000,0.000000) [0.000000|1.000000] "" Motor_BEV
 SG_ VZM_TSK_SRBM_nicht_verfuegbar  : 29|1@1+ (1.000000,0.000000) [0.000000|1.000000] "" Motor_BEV
 SG_ VZM_Verz_Reg_aktiv  : 30|5@1+ (1.000000,0.000000) [0.000000|31.000000] "" Motor_BEV
 SG_ VZM_Verz_Reg_nicht_verfuegbar  : 35|1@1+ (1.000000,0.000000) [0.000000|1.000000] "" Motor_BEV
 SG_ VMM_Inkonsistenz_KAS  : 36|1@1+ (1.000000,0.000000) [0.000000|1.000000] "" Motor_BEV
 SG_ VMM_Bremslicht_unplausibel  : 37|1@1+ (1.000000,0.000000) [0.000000|1.000000] "" Motor_BEV
 SG_ VMM_Inkonsistenz_ACC  : 38|1@1+ (1.000000,0.000000) [0.000000|1.000000] "" Motor_BEV
 SG_ VMM_Inkonsistenz_AWV_PCF  : 39|1@1+ (1.000000,0.000000) [0.000000|1.000000] "" Motor_BEV
 SG_ VMM_Inkonsistenz_ARA  : 40|1@1+ (1.000000,0.000000) [0.000000|1.000000] "" Motor_BEV
 SG_ VMM_Inkonsistenz_ParkAssist  : 41|1@1+ (1.000000,0.000000) [0.000000|1.000000] "" Motor_BEV
 SG_ VMM_Inkonsistenz_FAS_VK  : 42|1@1+ (1.000000,0.000000) [0.000000|1.000000] "" Motor_BEV
 SG_ VMM_Inkonsistenz_NV  : 43|1@1+ (1.000000,0.000000) [0.000000|1.000000] "" Motor_BEV
 SG_ VMM_Inkonsistenz_RCTA  : 44|1@1+ (1.000000,0.000000) [0.000000|1.000000] "" Motor_BEV
 SG_ VMM_Inkonsistenz_TSK  : 45|1@1+ (1.000000,0.000000) [0.000000|1.000000] "" Motor_BEV
 SG_ VMM_Inkonsistenz_MO  : 46|1@1+ (1.000000,0.000000) [0.000000|1.000000] "" Motor_BEV
 SG_ VMM_Inkonsistenz_AEB  : 47|1@1+ (1.000000,0.000000) [0.000000|1.000000] "" Vector__XXX
 SG_ VMM_Fahrer_Bremskraft_bestimmend  : 48|1@1+ (1.000000,0.000000) [0.000000|1.000000] "" Motor_BEV
 SG_ VMM_Inkonsistenz_EA  : 49|1@1+ (1.000000,0.000000) [0.000000|1.000000] "" Motor_BEV
 SG_ VZM_Status_Wegregelung  : 50|2@1+ (1.000000,0.000000) [0.000000|3.000000] "" Motor_BEV
 SG_ VZM_Verz_ASIL_Verfuegbarkeit  : 52|3@1+ (1.000000,0.000000) [0.000000|7.000000] "" Motor_BEV
 SG_ VZM_aktives_System  : 55|5@1+ (1.000000,0.000000) [0.000000|31.000000] "" Airbag Motor_BEV
 SG_ VZM_Verz_Begrenzung  : 60|1@1+ (1.000000,0.000000) [0.000000|1.000000] "" Motor_BEV
 SG_ VZM_Systemstatus  : 61|3@1+ (1.000000,0.000000) [0.000000|7.000000] "" Motor_BEV
 SG_ VZM_SRBM_Soll  : 64|12@1+ (8.000000,0.000000) [0.000000|32744.000000] "Unit_NewtoMeter" Motor_BEV
 SG_ VZM_SRBM_Ist  : 76|12@1+ (8.000000,0.000000) [0.000000|32744.000000] "Unit_NewtoMeter" Motor_BEV
 SG_ VZM_SRBM_max_Gradient  : 88|7@1+ (50.000000,0.000000) [0.000000|6250.000000] "Unit_NewtoMeterPerSecon" Motor_BEV
 SG_ VMM_Inkonsistenz_KAM  : 95|1@1+ (1.000000,0.000000) [0.000000|1.000000] "" Vector__XXX

BU_:  Airbag BAP_Tester ICAS1_Gateway ICAS1_KommunikationsServer LE1 LE2 Motor_BEV Schaltbetaetigung

BO_ 980 SMLS_01: 8 ICAS1_Gateway
 SG_ SMLS_01_CRC  : 0|8@1+ (1.000000,0.000000) [0.000000|255.000000] "" Vector__XXX
 SG_ SMLS_01_BZ  : 8|4@1+ (1.000000,0.000000) [0.000000|15.000000] "" Vector__XXX
 SG_ BH_Blinker_li  : 12|1@1+ (1.000000,0.000000) [0.000000|1.000000] "" Motor_BEV
 SG_ BH_Blinker_re  : 13|1@1+ (1.000000,0.000000) [0.000000|1.000000] "" Motor_BEV
 SG_ BH_Lichthupe  : 14|1@1+ (1.000000,0.000000) [0.000000|1.000000] "" Vector__XXX
 SG_ BH_Fernlicht  : 15|1@1+ (1.000000,0.000000) [0.000000|1.000000] "" Vector__XXX
 SG_ WH_Tipwischen  : 16|1@1+ (1.000000,0.000000) [0.000000|1.000000] "" Vector__XXX
 SG_ WH_Intervall  : 17|1@1+ (1.000000,0.000000) [0.000000|1.000000] "" Vector__XXX
 SG_ WH_WischerStufe1  : 18|1@1+ (1.000000,0.000000) [0.000000|1.000000] "" Vector__XXX
 SG_ WH_WischerStufe2  : 19|1@1+ (1.000000,0.000000) [0.000000|1.000000] "" Vector__XXX
 SG_ WH_Frontwaschen  : 20|1@1+ (1.000000,0.000000) [0.000000|1.000000] "" Vector__XXX
 SG_ WH_Heckintervall  : 21|1@1+ (1.000000,0.000000) [0.000000|1.000000] "" Vector__XXX
 SG_ WH_Heckwaschen  : 22|1@1+ (1.000000,0.000000) [0.000000|1.000000] "" Vector__XXX
 SG_ WH_Intervallstufen  : 23|4@1+ (1.000000,0.000000) [0.000000|15.000000] "" Vector__XXX
 SG_ FAS_Taster  : 27|1@1+ (1.000000,0.000000) [0.000000|1.000000] "" Vector__XXX
 SG_ FAS_Taster_Fehler  : 28|1@1+ (1.000000,0.000000) [0.000000|1.000000] "" Vector__XXX
 SG_ SMLS_Hupe  : 29|1@1+ (1.000000,0.000000) [0.000000|1.000000] "" Vector__XXX
 SG_ LRH_on_off  : 30|2@1+ (1.000000,0.000000) [0.000000|3.000000] "" Vector__XXX
 SG_ LSS_Tastencode  : 32|8@1+ (1.000000,0.000000) [0.000000|255.000000] "" Vector__XXX
 SG_ LRH_aktiv  : 40|1@1+ (1.000000,0.000000) [0.000000|1.000000] "" Vector__XXX
 SG_ SMLS_P_verriegelt  : 41|2@1+ (1.000000,0.000000) [0.000000|3.000000] "" Vector__XXX
 SG_ SMLS_P_verriegelt_plausibel  : 43|1@1+ (1.000000,0.000000) [0.000000|1.000000] "" Vector__XXX
 SG_ WH_SRA  : 44|1@1+ (1.000000,0.000000) [0.000000|1.000000] "" Vector__XXX
 SG_ WH_Wischer_Fehler  : 45|1@1+ (1.000000,0.000000) [0.000000|1.000000] "" Vector__XXX
 SG_ BH_Blinker_Fehler  : 46|1@1+ (1.000000,0.000000) [0.000000|1.000000] "" Vector__XXX
 SG_ SMLS_PTT  : 47|1@1+ (1.000000,0.000000) [0.000000|1.000000] "" Vector__XXX
 SG_ WH_Tipwischen_lang  : 48|1@1+ (1.000000,0.000000) [0.000000|1.000000] "" Vector__XXX

BO_ 2464153718 SOK_FoD_MO_01_Req_Chal_01: 8 Motor_BEV
 SG_ SOK_FoD_MO_01_Req_Challenge  : 0|64@1+ (1.000000,0.000000) [0.000000|18446744073709551616.000000] "Unit_None" ICAS1_Gateway

BO_ 2464284790 SOK_FoD_MO_01_Resp_Chal_01: 8 ICAS1_Gateway
 SG_ SOK_FoD_MO_01_Resp_Challenge  : 0|64@1+ (1.000000,0.000000) [0.000000|18446744073709551616.000000] "Unit_None" Motor_BEV

BO_ 1413 Systeminfo_01: 8 ICAS1_Gateway
 SG_ SI_Sammel_SG_Fehler  : 0|6@1+ (1.000000,0.000000) [0.000000|60.000000] "" Vector__XXX
 SG_ SI_P_Mode_gueltig  : 6|1@1+ (1.000000,0.000000) [0.000000|1.000000] "" Vector__XXX
 SG_ SI_Diagnose_Aktiv  : 7|1@1+ (1.000000,0.000000) [0.000000|1.000000] "" Vector__XXX
 SG_ SI_QRS_Mode  : 8|1@1+ (1.000000,0.000000) [0.000000|1.000000] "" Airbag Motor_BEV
 SG_ SI_T_Mode  : 9|1@1+ (1.000000,0.000000) [0.000000|1.000000] "" Motor_BEV
 SG_ SI_NWDF  : 10|1@1+ (1.000000,0.000000) [0.000000|1.000000] "" Vector__XXX
 SG_ SI_NWDF_gueltig  : 11|1@1+ (1.000000,0.000000) [0.000000|1.000000] "" Vector__XXX
 SG_ SI_Sammelfehler  : 12|1@1+ (1.000000,0.000000) [0.000000|1.000000] "" Vector__XXX
 SG_ GW_KD_Fehler  : 13|1@1+ (1.000000,0.000000) [0.000000|1.000000] "" Vector__XXX
 SG_ SI_T_Schutz  : 14|1@1+ (1.000000,0.000000) [0.000000|1.000000] "" Motor_BEV
 SG_ SI_P_Mode  : 15|1@1+ (1.000000,0.000000) [0.000000|1.000000] "" Vector__XXX
 SG_ SI_BUS_01  : 16|1@1+ (1.000000,0.000000) [0.000000|1.000000] "" Vector__XXX
 SG_ SI_BUS_02  : 17|1@1+ (1.000000,0.000000) [0.000000|1.000000] "" Vector__XXX
 SG_ SI_BUS_03  : 18|1@1+ (1.000000,0.000000) [0.000000|1.000000] "" Vector__XXX
 SG_ SI_BUS_04  : 19|1@1+ (1.000000,0.000000) [0.000000|1.000000] "" Vector__XXX
 SG_ SI_BUS_05  : 20|1@1+ (1.000000,0.000000) [0.000000|1.000000] "" Vector__XXX
 SG_ SI_BUS_06  : 21|1@1+ (1.000000,0.000000) [0.000000|1.000000] "" Vector__XXX
 SG_ SI_BUS_07  : 22|1@1+ (1.000000,0.000000) [0.000000|1.000000] "" Vector__XXX
 SG_ SI_BUS_08  : 23|1@1+ (1.000000,0.000000) [0.000000|1.000000] "" Vector__XXX
 SG_ SI_BUS_09  : 24|1@1+ (1.000000,0.000000) [0.000000|1.000000] "" Vector__XXX
 SG_ SI_BUS_10  : 25|1@1+ (1.000000,0.000000) [0.000000|1.000000] "" Vector__XXX
 SG_ SI_BUS_11  : 26|1@1+ (1.000000,0.000000) [0.000000|1.000000] "" Vector__XXX
 SG_ SI_BUS_12  : 27|1@1+ (1.000000,0.000000) [0.000000|1.000000] "" Vector__XXX
 SG_ SI_BUS_13  : 28|1@1+ (1.000000,0.000000) [0.000000|1.000000] "" Vector__XXX
 SG_ SI_BUS_14  : 29|1@1+ (1.000000,0.000000) [0.000000|1.000000] "" Vector__XXX
 SG_ SI_BUS_15  : 30|1@1+ (1.000000,0.000000) [0.000000|1.000000] "" Vector__XXX
 SG_ SI_Bus_Identifikation  : 32|8@1+ (1.000000,0.000000) [0.000000|255.000000] "" Vector__XXX
 SG_ SI_CAB_V10  : 40|24@1+ (1.000000,0.000000) [0.000000|16777215.000000] "" Vector__XXX

BO_ 2589283396 TSK_09: 8 Motor_BEV
 SG_ TSK_vMax_EfficiencyMode1  : 40|8@1+ (1.000000,0.000000) [0.000000|253.000000] "Unit_KiloMeterPerHour" ICAS1_Gateway
 SG_ TSK_vMax_EfficiencyMode2  : 48|8@1+ (1.000000,0.000000) [0.000000|253.000000] "Unit_KiloMeterPerHour" ICAS1_Gateway
 SG_ TSK_vMax_StandardMode  : 56|8@1+ (1.000000,0.000000) [0.000000|253.000000] "Unit_KiloMeterPerHour" ICAS1_Gateway

BO_ 1019 TSK_Ausrollkurve_01: 8 Motor_BEV
 SG_ TSK_Ausrollkurve_Schub_Reku_01 m0 : 0|7@1+ (2.000000,0.000000) [0.000000|252.000000] "Unit_KiloMeterPerHour" ICAS1_Gateway
 SG_ TSK_Ausrollkurve_Schub_Reku_05 m1 : 0|7@1+ (2.000000,0.000000) [0.000000|252.000000] "Unit_KiloMeterPerHour" ICAS1_Gateway
 SG_ TSK_Ausrollkurve_Schub_Reku_09 m2 : 0|7@1+ (2.000000,0.000000) [0.000000|252.000000] "Unit_KiloMeterPerHour" ICAS1_Gateway
 SG_ TSK_Ausrollkurve_Schub_Reku_13 m3 : 0|7@1+ (2.000000,0.000000) [0.000000|252.000000] "Unit_KiloMeterPerHour" ICAS1_Gateway
 SG_ TSK_Ausrollkurve_Schub_Reku_17 m4 : 0|7@1+ (2.000000,0.000000) [0.000000|252.000000] "Unit_KiloMeterPerHour" ICAS1_Gateway
 SG_ TSK_Ausrollkurve_Schub_Reku_02 m0 : 7|7@1+ (2.000000,0.000000) [0.000000|252.000000] "Unit_KiloMeterPerHour" ICAS1_Gateway
 SG_ TSK_Ausrollkurve_Schub_Reku_06 m1 : 7|7@1+ (2.000000,0.000000) [0.000000|252.000000] "Unit_KiloMeterPerHour" ICAS1_Gateway
 SG_ TSK_Ausrollkurve_Schub_Reku_10 m2 : 7|7@1+ (2.000000,0.000000) [0.000000|252.000000] "Unit_KiloMeterPerHour" ICAS1_Gateway
 SG_ TSK_Ausrollkurve_Schub_Reku_14 m3 : 7|7@1+ (2.000000,0.000000) [0.000000|252.000000] "Unit_KiloMeterPerHour" ICAS1_Gateway
 SG_ TSK_Ausrollkurve_Schub_Reku_18 m4 : 7|7@1+ (2.000000,0.000000) [0.000000|252.000000] "Unit_KiloMeterPerHour" ICAS1_Gateway
 SG_ TSK_Ausrollkurve_Schub_Reku_03 m0 : 14|7@1+ (2.000000,0.000000) [0.000000|252.000000] "Unit_KiloMeterPerHour" ICAS1_Gateway
 SG_ TSK_Ausrollkurve_Schub_Reku_07 m1 : 14|7@1+ (2.000000,0.000000) [0.000000|252.000000] "Unit_KiloMeterPerHour" ICAS1_Gateway
 SG_ TSK_Ausrollkurve_Schub_Reku_11 m2 : 14|7@1+ (2.000000,0.000000) [0.000000|252.000000] "Unit_KiloMeterPerHour" ICAS1_Gateway
 SG_ TSK_Ausrollkurve_Schub_Reku_15 m3 : 14|7@1+ (2.000000,0.000000) [0.000000|252.000000] "Unit_KiloMeterPerHour" ICAS1_Gateway
 SG_ TSK_Ausrollkurve_Schub_Reku_19 m4 : 14|7@1+ (2.000000,0.000000) [0.000000|252.000000] "Unit_KiloMeterPerHour" ICAS1_Gateway
 SG_ TSK_Ausrollkurve_Schub_Reku_04 m0 : 21|7@1+ (2.000000,0.000000) [0.000000|252.000000] "Unit_KiloMeterPerHour" ICAS1_Gateway
 SG_ TSK_Ausrollkurve_Schub_Reku_08 m1 : 21|7@1+ (2.000000,0.000000) [0.000000|252.000000] "Unit_KiloMeterPerHour" ICAS1_Gateway
 SG_ TSK_Ausrollkurve_Schub_Reku_12 m2 : 21|7@1+ (2.000000,0.000000) [0.000000|252.000000] "Unit_KiloMeterPerHour" ICAS1_Gateway
 SG_ TSK_Ausrollkurve_Schub_Reku_16 m3 : 21|7@1+ (2.000000,0.000000) [0.000000|252.000000] "Unit_KiloMeterPerHour" ICAS1_Gateway
 SG_ TSK_Ausrollkurve_Schub_Reku_20 m4 : 21|7@1+ (2.000000,0.000000) [0.000000|252.000000] "Unit_KiloMeterPerHour" ICAS1_Gateway
 SG_ TSK_Ausrollkurve_Segeln_01 m0 : 28|7@1+ (2.000000,0.000000) [0.000000|252.000000] "Unit_KiloMeterPerHour" ICAS1_Gateway
 SG_ TSK_Ausrollkurve_Segeln_05 m1 : 28|7@1+ (2.000000,0.000000) [0.000000|252.000000] "Unit_KiloMeterPerHour" ICAS1_Gateway
 SG_ TSK_Ausrollkurve_Segeln_09 m2 : 28|7@1+ (2.000000,0.000000) [0.000000|252.000000] "Unit_KiloMeterPerHour" ICAS1_Gateway
 SG_ TSK_Ausrollkurve_Segeln_13 m3 : 28|7@1+ (2.000000,0.000000) [0.000000|252.000000] "Unit_KiloMeterPerHour" ICAS1_Gateway
 SG_ TSK_Ausrollkurve_Segeln_17 m4 : 28|7@1+ (2.000000,0.000000) [0.000000|252.000000] "Unit_KiloMeterPerHour" ICAS1_Gateway
 SG_ TSK_Ausrollkurve_Segeln_02 m0 : 35|7@1+ (2.000000,0.000000) [0.000000|252.000000] "Unit_KiloMeterPerHour" ICAS1_Gateway
 SG_ TSK_Ausrollkurve_Segeln_06 m1 : 35|7@1+ (2.000000,0.000000) [0.000000|252.000000] "Unit_KiloMeterPerHour" ICAS1_Gateway
 SG_ TSK_Ausrollkurve_Segeln_10 m2 : 35|7@1+ (2.000000,0.000000) [0.000000|252.000000] "Unit_KiloMeterPerHour" ICAS1_Gateway
 SG_ TSK_Ausrollkurve_Segeln_14 m3 : 35|7@1+ (2.000000,0.000000) [0.000000|252.000000] "Unit_KiloMeterPerHour" ICAS1_Gateway
 SG_ TSK_Ausrollkurve_Segeln_18 m4 : 35|7@1+ (2.000000,0.000000) [0.000000|252.000000] "Unit_KiloMeterPerHour" ICAS1_Gateway
 SG_ TSK_Ausrollkurve_Segeln_03 m0 : 42|7@1+ (2.000000,0.000000) [0.000000|252.000000] "Unit_KiloMeterPerHour" ICAS1_Gateway
 SG_ TSK_Ausrollkurve_Segeln_07 m1 : 42|7@1+ (2.000000,0.000000) [0.000000|252.000000] "Unit_KiloMeterPerHour" ICAS1_Gateway
 SG_ TSK_Ausrollkurve_Segeln_11 m2 : 42|7@1+ (2.000000,0.000000) [0.000000|252.000000] "Unit_KiloMeterPerHour" ICAS1_Gateway
 SG_ TSK_Ausrollkurve_Segeln_15 m3 : 42|7@1+ (2.000000,0.000000) [0.000000|252.000000] "Unit_KiloMeterPerHour" ICAS1_Gateway
 SG_ TSK_Ausrollkurve_Segeln_19 m4 : 42|7@1+ (2.000000,0.000000) [0.000000|252.000000] "Unit_KiloMeterPerHour" ICAS1_Gateway
 SG_ TSK_Ausrollkurve_Segeln_04 m0 : 49|7@1+ (2.000000,0.000000) [0.000000|252.000000] "Unit_KiloMeterPerHour" ICAS1_Gateway
 SG_ TSK_Ausrollkurve_Segeln_08 m1 : 49|7@1+ (2.000000,0.000000) [0.000000|252.000000] "Unit_KiloMeterPerHour" ICAS1_Gateway
 SG_ TSK_Ausrollkurve_Segeln_12 m2 : 49|7@1+ (2.000000,0.000000) [0.000000|252.000000] "Unit_KiloMeterPerHour" ICAS1_Gateway
 SG_ TSK_Ausrollkurve_Segeln_16 m3 : 49|7@1+ (2.000000,0.000000) [0.000000|252.000000] "Unit_KiloMeterPerHour" ICAS1_Gateway
 SG_ TSK_Ausrollkurve_Segeln_20 m4 : 49|7@1+ (2.000000,0.000000) [0.000000|252.000000] "Unit_KiloMeterPerHour" ICAS1_Gateway
 SG_ TSK_Ausrollkurve_Mux M : 56|3@1+ (1.000000,0.000000) [0.000000|7.000000] "" ICAS1_Gateway
 SG_ TSK_Ausrollkurve_Reku  : 59|1@1+ (1.000000,0.000000) [0.000000|1.000000] "" ICAS1_Gateway
 SG_ TSK_Ausrollkurve_Schrittweite  : 60|1@1+ (1.000000,0.000000) [0.000000|1.000000] "" ICAS1_Gateway
 SG_ TSK_Ausrollkurve_Zaehler  : 61|2@1+ (1.000000,0.000000) [0.000000|3.000000] "" ICAS1_Gateway

BO_ 1716 VIN_01: 8 ICAS1_Gateway
 SG_ VIN_01_MUX M : 0|2@1+ (1.000000,0.000000) [0.000000|3.000000] "" Airbag Motor_BEV
 SG_ KS_Geheimnis_1 m0 : 8|8@1+ (1.000000,0.000000) [0.000000|255.000000] "" Airbag
 SG_ VIN_4 m1 : 8|8@1+ (1.000000,0.000000) [0.000000|255.000000] "" Airbag Motor_BEV
 SG_ VIN_11 m2 : 8|8@1+ (1.000000,0.000000) [0.000000|255.000000] "" Airbag Motor_BEV
 SG_ KS_Geheimnis_2 m0 : 16|8@1+ (1.000000,0.000000) [0.000000|255.000000] "" Airbag
 SG_ VIN_5 m1 : 16|8@1+ (1.000000,0.000000) [0.000000|255.000000] "" Airbag Motor_BEV
 SG_ VIN_12 m2 : 16|8@1+ (1.000000,0.000000) [0.000000|255.000000] "" Airbag Motor_BEV
 SG_ KS_Geheimnis_3 m0 : 24|8@1+ (1.000000,0.000000) [0.000000|255.000000] "" Airbag
 SG_ VIN_6 m1 : 24|8@1+ (1.000000,0.000000) [0.000000|255.000000] "" Airbag Motor_BEV
 SG_ VIN_13 m2 : 24|8@1+ (1.000000,0.000000) [0.000000|255.000000] "" Airbag Motor_BEV
 SG_ KS_Geheimnis_4 m0 : 32|8@1+ (1.000000,0.000000) [0.000000|255.000000] "" Airbag
 SG_ VIN_7 m1 : 32|8@1+ (1.000000,0.000000) [0.000000|255.000000] "" Airbag Motor_BEV
 SG_ VIN_14 m2 : 32|8@1+ (1.000000,0.000000) [0.000000|255.000000] "" Airbag Motor_BEV
 SG_ VIN_1 m0 : 40|8@1+ (1.000000,0.000000) [0.000000|255.000000] "" Airbag Motor_BEV
 SG_ VIN_8 m1 : 40|8@1+ (1.000000,0.000000) [0.000000|255.000000] "" Airbag Motor_BEV
 SG_ VIN_15 m2 : 40|8@1+ (1.000000,0.000000) [0.000000|255.000000] "" Airbag Motor_BEV
 SG_ VIN_2 m0 : 48|8@1+ (1.000000,0.000000) [0.000000|255.000000] "" Airbag Motor_BEV
 SG_ VIN_9 m1 : 48|8@1+ (1.000000,0.000000) [0.000000|255.000000] "" Airbag Motor_BEV
 SG_ VIN_16 m2 : 48|8@1+ (1.000000,0.000000) [0.000000|255.000000] "" Airbag Motor_BEV
 SG_ VIN_3 m0 : 56|8@1+ (1.000000,0.000000) [0.000000|255.000000] "" Airbag Motor_BEV
 SG_ VIN_10 m1 : 56|8@1+ (1.000000,0.000000) [0.000000|255.000000] "" Airbag Motor_BEV
 SG_ VIN_17 m2 : 56|8@1+ (1.000000,0.000000) [0.000000|255.000000] "" Airbag Motor_BEV

BO_ 261 VMM_01: 8 ICAS1_Gateway
 SG_ VMM_01_CRC  : 0|8@1+ (1.000000,0.000000) [0.000000|255.000000] "" Motor_BEV
 SG_ VMM_01_BZ  : 8|4@1+ (1.000000,0.000000) [0.000000|15.000000] "" Motor_BEV
 SG_ HMS_P_beibehalten_GE  : 12|2@1+ (1.000000,0.000000) [0.000000|3.000000] "" Vector__XXX
 SG_ VZM_Unterdrueckung_Antriebsmom  : 14|1@1+ (1.000000,0.000000) [0.000000|1.000000] "" Airbag Motor_BEV
 SG_ HMS_halten_nicht_verfuegbar  : 20|1@1+ (1.000000,0.000000) [0.000000|1.000000] "" Vector__XXX
 SG_ HMS_parken_nicht_verfuegbar  : 32|1@1+ (1.000000,0.000000) [0.000000|1.000000] "" Vector__XXX
 SG_ HMS_Anforderung_GE  : 33|3@1+ (1.000000,0.000000) [0.000000|7.000000] "" Vector__XXX
 SG_ HMS_Systemstatus  : 36|4@1+ (1.000000,0.000000) [0.000000|15.000000] "" Motor_BEV
 SG_ HMS_Stillstand  : 40|3@1+ (1.000000,0.000000) [0.000000|7.000000] "" Motor_BEV
 SG_ HMS_aktives_System  : 43|5@1+ (1.000000,0.000000) [0.000000|31.000000] "" Motor_BEV
 SG_ VMM_Inkonsistenz_GE  : 48|1@1+ (1.000000,0.000000) [0.000000|1.000000] "" Motor_BEV
 SG_ VMM_Inkonsistenz_HVLM  : 49|1@1+ (1.000000,0.000000) [0.000000|1.000000] "" Motor_BEV
 SG_ HMS_Fehlerstatus  : 50|3@1+ (1.000000,0.000000) [0.000000|7.000000] "" Vector__XXX
 SG_ HMS_Index_Haltemoment  : 53|1@1+ (1.000000,0.000000) [0.000000|1.000000] "" Motor_BEV
 SG_ HMS_Haltemoment  : 54|10@1+ (10.000000,0.000000) [0.000000|10210.000000] "Unit_NewtoMeter" Motor_BEV

BO_ 313 VMM_02: 32 ICAS1_Gateway
 SG_ VMM_02_CRC  : 0|8@1+ (1.000000,0.000000) [0.000000|255.000000] "" Motor_BEV
 SG_ VMM_02_BZ  : 8|4@1+ (1.000000,0.000000) [0.000000|15.000000] "" Motor_BEV
 SG_ VZM_aktiver_Basisservice  : 12|3@1+ (1.000000,0.000000) [0.000000|7.000000] "" Motor_BEV
 SG_ VZM_Anhalteweg_nicht_verfuegbar  : 15|1@1+ (1.000000,0.000000) [0.000000|1.000000] "" Motor_BEV
 SG_ VZM_Fahrer_bremst  : 16|1@1+ (1.000000,0.000000) [0.000000|1.000000] "" Motor_BEV
 SG_ VZM_QBit_Fahrer_bremst  : 17|1@1+ (1.000000,0.000000) [0.000000|1.000000] "" Motor_BEV
 SG_ VMM_MKB_codiert  : 18|1@1+ (1.000000,0.000000) [0.000000|1.000000] "" Airbag
 SG_ VMM_Inkonsistenz_EBKV  : 19|1@1+ (1.000000,0.000000) [0.000000|1.000000] "" Vector__XXX
 SG_ VMM_Notstopp_Status  : 20|3@1+ (1.000000,0.000000) [0.000000|7.000000] "" Motor_BEV
 SG_ VZM_Warnruck_nicht_verfuegbar  : 23|1@1+ (1.000000,0.000000) [0.000000|1.000000] "" Motor_BEV
 SG_ VZM_Warnruckeln_nicht_verfuegbar  : 24|1@1+ (1.000000,0.000000) [0.000000|1.000000] "" Motor_BEV
 SG_ VZM_Bkd_nicht_verfuegbar  : 25|1@1+ (1.000000,0.000000) [0.000000|1.000000] "" Motor_BEV
 SG_ VMM_Bremslicht_defekt  : 26|1@1+ (1.000000,0.000000) [0.000000|1.000000] "" Motor_BEV
 SG_ VZM_Fahrer_bremst_deutlich  : 27|1@1+ (1.000000,0.000000) [0.000000|1.000000] "" Airbag Motor_BEV
 SG_ VZM_TSK_SRBM_Anf  : 28|1@1+ (1.000000,0.000000) [0.000000|1.000000] "" Motor_BEV
 SG_ VZM_TSK_SRBM_nicht_verfuegbar  : 29|1@1+ (1.000000,0.000000) [0.000000|1.000000] "" Motor_BEV
 SG_ VZM_Verz_Reg_aktiv  : 30|5@1+ (1.000000,0.000000) [0.000000|31.000000] "" Motor_BEV
 SG_ VZM_Verz_Reg_nicht_verfuegbar  : 35|1@1+ (1.000000,0.000000) [0.000000|1.000000] "" Motor_BEV
 SG_ VMM_Inkonsistenz_KAS  : 36|1@1+ (1.000000,0.000000) [0.000000|1.000000] "" Motor_BEV
 SG_ VMM_Bremslicht_unplausibel  : 37|1@1+ (1.000000,0.000000) [0.000000|1.000000] "" Motor_BEV
 SG_ VMM_Inkonsistenz_ACC  : 38|1@1+ (1.000000,0.000000) [0.000000|1.000000] "" Motor_BEV
 SG_ VMM_Inkonsistenz_AWV_PCF  : 39|1@1+ (1.000000,0.000000) [0.000000|1.000000] "" Motor_BEV
 SG_ VMM_Inkonsistenz_ARA  : 40|1@1+ (1.000000,0.000000) [0.000000|1.000000] "" Motor_BEV
 SG_ VMM_Inkonsistenz_ParkAssist  : 41|1@1+ (1.000000,0.000000) [0.000000|1.000000] "" Motor_BEV
 SG_ VMM_Inkonsistenz_FAS_VK  : 42|1@1+ (1.000000,0.000000) [0.000000|1.000000] "" Motor_BEV
 SG_ VMM_Inkonsistenz_NV  : 43|1@1+ (1.000000,0.000000) [0.000000|1.000000] "" Motor_BEV
 SG_ VMM_Inkonsistenz_RCTA  : 44|1@1+ (1.000000,0.000000) [0.000000|1.000000] "" Motor_BEV
 SG_ VMM_Inkonsistenz_TSK  : 45|1@1+ (1.000000,0.000000) [0.000000|1.000000] "" Motor_BEV
 SG_ VMM_Inkonsistenz_MO  : 46|1@1+ (1.000000,0.000000) [0.000000|1.000000] "" Motor_BEV
 SG_ VMM_Inkonsistenz_AEB  : 47|1@1+ (1.000000,0.000000) [0.000000|1.000000] "" Vector__XXX
 SG_ VMM_Fahrer_Bremskraft_bestimmend  : 48|1@1+ (1.000000,0.000000) [0.000000|1.000000] "" Motor_BEV
 SG_ VMM_Inkonsistenz_EA  : 49|1@1+ (1.000000,0.000000) [0.000000|1.000000] "" Motor_BEV
 SG_ VZM_Status_Wegregelung  : 50|2@1+ (1.000000,0.000000) [0.000000|3.000000] "" Motor_BEV
 SG_ VZM_Verz_ASIL_Verfuegbarkeit  : 52|3@1+ (1.000000,0.000000) [0.000000|7.000000] "" Motor_BEV
 SG_ VZM_aktives_System  : 55|5@1+ (1.000000,0.000000) [0.000000|31.000000] "" Airbag Motor_BEV
 SG_ VZM_Verz_Begrenzung  : 60|1@1+ (1.000000,0.000000) [0.000000|1.000000] "" Motor_BEV
 SG_ VZM_Systemstatus  : 61|3@1+ (1.000000,0.000000) [0.000000|7.000000] "" Motor_BEV
 SG_ VZM_SRBM_Soll  : 64|12@1+ (8.000000,0.000000) [0.000000|32744.000000] "Unit_NewtoMeter" Motor_BEV
 SG_ VZM_SRBM_Ist  : 76|12@1+ (8.000000,0.000000) [0.000000|32744.000000] "Unit_NewtoMeter" Motor_BEV
 SG_ VZM_SRBM_max_Gradient  : 88|7@1+ (50.000000,0.000000) [0.000000|6250.000000] "Unit_NewtoMeterPerSecon" Motor_BEV
 SG_ VMM_Inkonsistenz_KAM  : 95|1@1+ (1.000000,0.000000) [0.000000|1.000000] "" Vector__XXX

BU_:  Airbag BAP_Tester ICAS1_Gateway ICAS1_KommunikationsServer LE1 LE2 Motor_BEV Schaltbetaetigung

BO_ 980 SMLS_01: 8 ICAS1_Gateway
 SG_ SMLS_01_CRC  : 0|8@1+ (1.000000,0.000000) [0.000000|255.000000] "" Vector__XXX
 SG_ SMLS_01_BZ  : 8|4@1+ (1.000000,0.000000) [0.000000|15.000000] "" Vector__XXX
 SG_ BH_Blinker_li  : 12|1@1+ (1.000000,0.000000) [0.000000|1.000000] "" Motor_BEV
 SG_ BH_Blinker_re  : 13|1@1+ (1.000000,0.000000) [0.000000|1.000000] "" Motor_BEV
 SG_ BH_Lichthupe  : 14|1@1+ (1.000000,0.000000) [0.000000|1.000000] "" Vector__XXX
 SG_ BH_Fernlicht  : 15|1@1+ (1.000000,0.000000) [0.000000|1.000000] "" Vector__XXX
 SG_ WH_Tipwischen  : 16|1@1+ (1.000000,0.000000) [0.000000|1.000000] "" Vector__XXX
 SG_ WH_Intervall  : 17|1@1+ (1.000000,0.000000) [0.000000|1.000000] "" Vector__XXX
 SG_ WH_WischerStufe1  : 18|1@1+ (1.000000,0.000000) [0.000000|1.000000] "" Vector__XXX
 SG_ WH_WischerStufe2  : 19|1@1+ (1.000000,0.000000) [0.000000|1.000000] "" Vector__XXX
 SG_ WH_Frontwaschen  : 20|1@1+ (1.000000,0.000000) [0.000000|1.000000] "" Vector__XXX
 SG_ WH_Heckintervall  : 21|1@1+ (1.000000,0.000000) [0.000000|1.000000] "" Vector__XXX
 SG_ WH_Heckwaschen  : 22|1@1+ (1.000000,0.000000) [0.000000|1.000000] "" Vector__XXX
 SG_ WH_Intervallstufen  : 23|4@1+ (1.000000,0.000000) [0.000000|15.000000] "" Vector__XXX
 SG_ FAS_Taster  : 27|1@1+ (1.000000,0.000000) [0.000000|1.000000] "" Vector__XXX
 SG_ FAS_Taster_Fehler  : 28|1@1+ (1.000000,0.000000) [0.000000|1.000000] "" Vector__XXX
 SG_ SMLS_Hupe  : 29|1@1+ (1.000000,0.000000) [0.000000|1.000000] "" Vector__XXX
 SG_ LRH_on_off  : 30|2@1+ (1.000000,0.000000) [0.000000|3.000000] "" Vector__XXX
 SG_ LSS_Tastencode  : 32|8@1+ (1.000000,0.000000) [0.000000|255.000000] "" Vector__XXX
 SG_ LRH_aktiv  : 40|1@1+ (1.000000,0.000000) [0.000000|1.000000] "" Vector__XXX
 SG_ SMLS_P_verriegelt  : 41|2@1+ (1.000000,0.000000) [0.000000|3.000000] "" Vector__XXX
 SG_ SMLS_P_verriegelt_plausibel  : 43|1@1+ (1.000000,0.000000) [0.000000|1.000000] "" Vector__XXX
 SG_ WH_SRA  : 44|1@1+ (1.000000,0.000000) [0.000000|1.000000] "" Vector__XXX
 SG_ WH_Wischer_Fehler  : 45|1@1+ (1.000000,0.000000) [0.000000|1.000000] "" Vector__XXX
 SG_ BH_Blinker_Fehler  : 46|1@1+ (1.000000,0.000000) [0.000000|1.000000] "" Vector__XXX
 SG_ SMLS_PTT  : 47|1@1+ (1.000000,0.000000) [0.000000|1.000000] "" Vector__XXX
 SG_ WH_Tipwischen_lang  : 48|1@1+ (1.000000,0.000000) [0.000000|1.000000] "" Vector__XXX

BO_ 2464153718 SOK_FoD_MO_01_Req_Chal_01: 8 Motor_BEV
 SG_ SOK_FoD_MO_01_Req_Challenge  : 0|64@1+ (1.000000,0.000000) [0.000000|18446744073709551616.000000] "Unit_None" ICAS1_Gateway

BO_ 2464284790 SOK_FoD_MO_01_Resp_Chal_01: 8 ICAS1_Gateway
 SG_ SOK_FoD_MO_01_Resp_Challenge  : 0|64@1+ (1.000000,0.000000) [0.000000|18446744073709551616.000000] "Unit_None" Motor_BEV

BO_ 1413 Systeminfo_01: 8 ICAS1_Gateway
 SG_ SI_Sammel_SG_Fehler  : 0|6@1+ (1.000000,0.000000) [0.000000|60.000000] "" Vector__XXX
 SG_ SI_P_Mode_gueltig  : 6|1@1+ (1.000000,0.000000) [0.000000|1.000000] "" Vector__XXX
 SG_ SI_Diagnose_Aktiv  : 7|1@1+ (1.000000,0.000000) [0.000000|1.000000] "" Vector__XXX
 SG_ SI_QRS_Mode  : 8|1@1+ (1.000000,0.000000) [0.000000|1.000000] "" Airbag Motor_BEV
 SG_ SI_T_Mode  : 9|1@1+ (1.000000,0.000000) [0.000000|1.000000] "" Motor_BEV
 SG_ SI_NWDF  : 10|1@1+ (1.000000,0.000000) [0.000000|1.000000] "" Vector__XXX
 SG_ SI_NWDF_gueltig  : 11|1@1+ (1.000000,0.000000) [0.000000|1.000000] "" Vector__XXX
 SG_ SI_Sammelfehler  : 12|1@1+ (1.000000,0.000000) [0.000000|1.000000] "" Vector__XXX
 SG_ GW_KD_Fehler  : 13|1@1+ (1.000000,0.000000) [0.000000|1.000000] "" Vector__XXX
 SG_ SI_T_Schutz  : 14|1@1+ (1.000000,0.000000) [0.000000|1.000000] "" Motor_BEV
 SG_ SI_P_Mode  : 15|1@1+ (1.000000,0.000000) [0.000000|1.000000] "" Vector__XXX
 SG_ SI_BUS_01  : 16|1@1+ (1.000000,0.000000) [0.000000|1.000000] "" Vector__XXX
 SG_ SI_BUS_02  : 17|1@1+ (1.000000,0.000000) [0.000000|1.000000] "" Vector__XXX
 SG_ SI_BUS_03  : 18|1@1+ (1.000000,0.000000) [0.000000|1.000000] "" Vector__XXX
 SG_ SI_BUS_04  : 19|1@1+ (1.000000,0.000000) [0.000000|1.000000] "" Vector__XXX
 SG_ SI_BUS_05  : 20|1@1+ (1.000000,0.000000) [0.000000|1.000000] "" Vector__XXX
 SG_ SI_BUS_06  : 21|1@1+ (1.000000,0.000000) [0.000000|1.000000] "" Vector__XXX
 SG_ SI_BUS_07  : 22|1@1+ (1.000000,0.000000) [0.000000|1.000000] "" Vector__XXX
 SG_ SI_BUS_08  : 23|1@1+ (1.000000,0.000000) [0.000000|1.000000] "" Vector__XXX
 SG_ SI_BUS_09  : 24|1@1+ (1.000000,0.000000) [0.000000|1.000000] "" Vector__XXX
 SG_ SI_BUS_10  : 25|1@1+ (1.000000,0.000000) [0.000000|1.000000] "" Vector__XXX
 SG_ SI_BUS_11  : 26|1@1+ (1.000000,0.000000) [0.000000|1.000000] "" Vector__XXX
 SG_ SI_BUS_12  : 27|1@1+ (1.000000,0.000000) [0.000000|1.000000] "" Vector__XXX
 SG_ SI_BUS_13  : 28|1@1+ (1.000000,0.000000) [0.000000|1.000000] "" Vector__XXX
 SG_ SI_BUS_14  : 29|1@1+ (1.000000,0.000000) [0.000000|1.000000] "" Vector__XXX
 SG_ SI_BUS_15  : 30|1@1+ (1.000000,0.000000) [0.000000|1.000000] "" Vector__XXX
 SG_ SI_Bus_Identifikation  : 32|8@1+ (1.000000,0.000000) [0.000000|255.000000] "" Vector__XXX
 SG_ SI_CAB_V10  : 40|24@1+ (1.000000,0.000000) [0.000000|16777215.000000] "" Vector__XXX

BO_ 2589283396 TSK_09: 8 Motor_BEV
 SG_ TSK_vMax_EfficiencyMode1  : 40|8@1+ (1.000000,0.000000) [0.000000|253.000000] "Unit_KiloMeterPerHour" ICAS1_Gateway
 SG_ TSK_vMax_EfficiencyMode2  : 48|8@1+ (1.000000,0.000000) [0.000000|253.000000] "Unit_KiloMeterPerHour" ICAS1_Gateway
 SG_ TSK_vMax_StandardMode  : 56|8@1+ (1.000000,0.000000) [0.000000|253.000000] "Unit_KiloMeterPerHour" ICAS1_Gateway

BO_ 1019 TSK_Ausrollkurve_01: 8 Motor_BEV
 SG_ TSK_Ausrollkurve_Schub_Reku_01 m0 : 0|7@1+ (2.000000,0.000000) [0.000000|252.000000] "Unit_KiloMeterPerHour" ICAS1_Gateway
 SG_ TSK_Ausrollkurve_Schub_Reku_05 m1 : 0|7@1+ (2.000000,0.000000) [0.000000|252.000000] "Unit_KiloMeterPerHour" ICAS1_Gateway
 SG_ TSK_Ausrollkurve_Schub_Reku_09 m2 : 0|7@1+ (2.000000,0.000000) [0.000000|252.000000] "Unit_KiloMeterPerHour" ICAS1_Gateway
 SG_ TSK_Ausrollkurve_Schub_Reku_13 m3 : 0|7@1+ (2.000000,0.000000) [0.000000|252.000000] "Unit_KiloMeterPerHour" ICAS1_Gateway
 SG_ TSK_Ausrollkurve_Schub_Reku_17 m4 : 0|7@1+ (2.000000,0.000000) [0.000000|252.000000] "Unit_KiloMeterPerHour" ICAS1_Gateway
 SG_ TSK_Ausrollkurve_Schub_Reku_02 m0 : 7|7@1+ (2.000000,0.000000) [0.000000|252.000000] "Unit_KiloMeterPerHour" ICAS1_Gateway
 SG_ TSK_Ausrollkurve_Schub_Reku_06 m1 : 7|7@1+ (2.000000,0.000000) [0.000000|252.000000] "Unit_KiloMeterPerHour" ICAS1_Gateway
 SG_ TSK_Ausrollkurve_Schub_Reku_10 m2 : 7|7@1+ (2.000000,0.000000) [0.000000|252.000000] "Unit_KiloMeterPerHour" ICAS1_Gateway
 SG_ TSK_Ausrollkurve_Schub_Reku_14 m3 : 7|7@1+ (2.000000,0.000000) [0.000000|252.000000] "Unit_KiloMeterPerHour" ICAS1_Gateway
 SG_ TSK_Ausrollkurve_Schub_Reku_18 m4 : 7|7@1+ (2.000000,0.000000) [0.000000|252.000000] "Unit_KiloMeterPerHour" ICAS1_Gateway
 SG_ TSK_Ausrollkurve_Schub_Reku_03 m0 : 14|7@1+ (2.000000,0.000000) [0.000000|252.000000] "Unit_KiloMeterPerHour" ICAS1_Gateway
 SG_ TSK_Ausrollkurve_Schub_Reku_07 m1 : 14|7@1+ (2.000000,0.000000) [0.000000|252.000000] "Unit_KiloMeterPerHour" ICAS1_Gateway
 SG_ TSK_Ausrollkurve_Schub_Reku_11 m2 : 14|7@1+ (2.000000,0.000000) [0.000000|252.000000] "Unit_KiloMeterPerHour" ICAS1_Gateway
 SG_ TSK_Ausrollkurve_Schub_Reku_15 m3 : 14|7@1+ (2.000000,0.000000) [0.000000|252.000000] "Unit_KiloMeterPerHour" ICAS1_Gateway
 SG_ TSK_Ausrollkurve_Schub_Reku_19 m4 : 14|7@1+ (2.000000,0.000000) [0.000000|252.000000] "Unit_KiloMeterPerHour" ICAS1_Gateway
 SG_ TSK_Ausrollkurve_Schub_Reku_04 m0 : 21|7@1+ (2.000000,0.000000) [0.000000|252.000000] "Unit_KiloMeterPerHour" ICAS1_Gateway
 SG_ TSK_Ausrollkurve_Schub_Reku_08 m1 : 21|7@1+ (2.000000,0.000000) [0.000000|252.000000] "Unit_KiloMeterPerHour" ICAS1_Gateway
 SG_ TSK_Ausrollkurve_Schub_Reku_12 m2 : 21|7@1+ (2.000000,0.000000) [0.000000|252.000000] "Unit_KiloMeterPerHour" ICAS1_Gateway
 SG_ TSK_Ausrollkurve_Schub_Reku_16 m3 : 21|7@1+ (2.000000,0.000000) [0.000000|252.000000] "Unit_KiloMeterPerHour" ICAS1_Gateway
 SG_ TSK_Ausrollkurve_Schub_Reku_20 m4 : 21|7@1+ (2.000000,0.000000) [0.000000|252.000000] "Unit_KiloMeterPerHour" ICAS1_Gateway
 SG_ TSK_Ausrollkurve_Segeln_01 m0 : 28|7@1+ (2.000000,0.000000) [0.000000|252.000000] "Unit_KiloMeterPerHour" ICAS1_Gateway
 SG_ TSK_Ausrollkurve_Segeln_05 m1 : 28|7@1+ (2.000000,0.000000) [0.000000|252.000000] "Unit_KiloMeterPerHour" ICAS1_Gateway
 SG_ TSK_Ausrollkurve_Segeln_09 m2 : 28|7@1+ (2.000000,0.000000) [0.000000|252.000000] "Unit_KiloMeterPerHour" ICAS1_Gateway
 SG_ TSK_Ausrollkurve_Segeln_13 m3 : 28|7@1+ (2.000000,0.000000) [0.000000|252.000000] "Unit_KiloMeterPerHour" ICAS1_Gateway
 SG_ TSK_Ausrollkurve_Segeln_17 m4 : 28|7@1+ (2.000000,0.000000) [0.000000|252.000000] "Unit_KiloMeterPerHour" ICAS1_Gateway
 SG_ TSK_Ausrollkurve_Segeln_02 m0 : 35|7@1+ (2.000000,0.000000) [0.000000|252.000000] "Unit_KiloMeterPerHour" ICAS1_Gateway
 SG_ TSK_Ausrollkurve_Segeln_06 m1 : 35|7@1+ (2.000000,0.000000) [0.000000|252.000000] "Unit_KiloMeterPerHour" ICAS1_Gateway
 SG_ TSK_Ausrollkurve_Segeln_10 m2 : 35|7@1+ (2.000000,0.000000) [0.000000|252.000000] "Unit_KiloMeterPerHour" ICAS1_Gateway
 SG_ TSK_Ausrollkurve_Segeln_14 m3 : 35|7@1+ (2.000000,0.000000) [0.000000|252.000000] "Unit_KiloMeterPerHour" ICAS1_Gateway
 SG_ TSK_Ausrollkurve_Segeln_18 m4 : 35|7@1+ (2.000000,0.000000) [0.000000|252.000000] "Unit_KiloMeterPerHour" ICAS1_Gateway
 SG_ TSK_Ausrollkurve_Segeln_03 m0 : 42|7@1+ (2.000000,0.000000) [0.000000|252.000000] "Unit_KiloMeterPerHour" ICAS1_Gateway
 SG_ TSK_Ausrollkurve_Segeln_07 m1 : 42|7@1+ (2.000000,0.000000) [0.000000|252.000000] "Unit_KiloMeterPerHour" ICAS1_Gateway
 SG_ TSK_Ausrollkurve_Segeln_11 m2 : 42|7@1+ (2.000000,0.000000) [0.000000|252.000000] "Unit_KiloMeterPerHour" ICAS1_Gateway
 SG_ TSK_Ausrollkurve_Segeln_15 m3 : 42|7@1+ (2.000000,0.000000) [0.000000|252.000000] "Unit_KiloMeterPerHour" ICAS1_Gateway
 SG_ TSK_Ausrollkurve_Segeln_19 m4 : 42|7@1+ (2.000000,0.000000) [0.000000|252.000000] "Unit_KiloMeterPerHour" ICAS1_Gateway
 SG_ TSK_Ausrollkurve_Segeln_04 m0 : 49|7@1+ (2.000000,0.000000) [0.000000|252.000000] "Unit_KiloMeterPerHour" ICAS1_Gateway
 SG_ TSK_Ausrollkurve_Segeln_08 m1 : 49|7@1+ (2.000000,0.000000) [0.000000|252.000000] "Unit_KiloMeterPerHour" ICAS1_Gateway
 SG_ TSK_Ausrollkurve_Segeln_12 m2 : 49|7@1+ (2.000000,0.000000) [0.000000|252.000000] "Unit_KiloMeterPerHour" ICAS1_Gateway
 SG_ TSK_Ausrollkurve_Segeln_16 m3 : 49|7@1+ (2.000000,0.000000) [0.000000|252.000000] "Unit_KiloMeterPerHour" ICAS1_Gateway
 SG_ TSK_Ausrollkurve_Segeln_20 m4 : 49|7@1+ (2.000000,0.000000) [0.000000|252.000000] "Unit_KiloMeterPerHour" ICAS1_Gateway
 SG_ TSK_Ausrollkurve_Mux M : 56|3@1+ (1.000000,0.000000) [0.000000|7.000000] "" ICAS1_Gateway
 SG_ TSK_Ausrollkurve_Reku  : 59|1@1+ (1.000000,0.000000) [0.000000|1.000000] "" ICAS1_Gateway
 SG_ TSK_Ausrollkurve_Schrittweite  : 60|1@1+ (1.000000,0.000000) [0.000000|1.000000] "" ICAS1_Gateway
 SG_ TSK_Ausrollkurve_Zaehler  : 61|2@1+ (1.000000,0.000000) [0.000000|3.000000] "" ICAS1_Gateway

BO_ 1716 VIN_01: 8 ICAS1_Gateway
 SG_ VIN_01_MUX M : 0|2@1+ (1.000000,0.000000) [0.000000|3.000000] "" Airbag Motor_BEV
 SG_ KS_Geheimnis_1 m0 : 8|8@1+ (1.000000,0.000000) [0.000000|255.000000] "" Airbag
 SG_ VIN_4 m1 : 8|8@1+ (1.000000,0.000000) [0.000000|255.000000] "" Airbag Motor_BEV
 SG_ VIN_11 m2 : 8|8@1+ (1.000000,0.000000) [0.000000|255.000000] "" Airbag Motor_BEV
 SG_ KS_Geheimnis_2 m0 : 16|8@1+ (1.000000,0.000000) [0.000000|255.000000] "" Airbag
 SG_ VIN_5 m1 : 16|8@1+ (1.000000,0.000000) [0.000000|255.000000] "" Airbag Motor_BEV
 SG_ VIN_12 m2 : 16|8@1+ (1.000000,0.000000) [0.000000|255.000000] "" Airbag Motor_BEV
 SG_ KS_Geheimnis_3 m0 : 24|8@1+ (1.000000,0.000000) [0.000000|255.000000] "" Airbag
 SG_ VIN_6 m1 : 24|8@1+ (1.000000,0.000000) [0.000000|255.000000] "" Airbag Motor_BEV
 SG_ VIN_13 m2 : 24|8@1+ (1.000000,0.000000) [0.000000|255.000000] "" Airbag Motor_BEV
 SG_ KS_Geheimnis_4 m0 : 32|8@1+ (1.000000,0.000000) [0.000000|255.000000] "" Airbag
 SG_ VIN_7 m1 : 32|8@1+ (1.000000,0.000000) [0.000000|255.000000] "" Airbag Motor_BEV
 SG_ VIN_14 m2 : 32|8@1+ (1.000000,0.000000) [0.000000|255.000000] "" Airbag Motor_BEV
 SG_ VIN_1 m0 : 40|8@1+ (1.000000,0.000000) [0.000000|255.000000] "" Airbag Motor_BEV
 SG_ VIN_8 m1 : 40|8@1+ (1.000000,0.000000) [0.000000|255.000000] "" Airbag Motor_BEV
 SG_ VIN_15 m2 : 40|8@1+ (1.000000,0.000000) [0.000000|255.000000] "" Airbag Motor_BEV
 SG_ VIN_2 m0 : 48|8@1+ (1.000000,0.000000) [0.000000|255.000000] "" Airbag Motor_BEV
 SG_ VIN_9 m1 : 48|8@1+ (1.000000,0.000000) [0.000000|255.000000] "" Airbag Motor_BEV
 SG_ VIN_16 m2 : 48|8@1+ (1.000000,0.000000) [0.000000|255.000000] "" Airbag Motor_BEV
 SG_ VIN_3 m0 : 56|8@1+ (1.000000,0.000000) [0.000000|255.000000] "" Airbag Motor_BEV
 SG_ VIN_10 m1 : 56|8@1+ (1.000000,0.000000) [0.000000|255.000000] "" Airbag Motor_BEV
 SG_ VIN_17 m2 : 56|8@1+ (1.000000,0.000000) [0.000000|255.000000] "" Airbag Motor_BEV

BO_ 261 VMM_01: 8 ICAS1_Gateway
 SG_ VMM_01_CRC  : 0|8@1+ (1.000000,0.000000) [0.000000|255.000000] "" Motor_BEV
 SG_ VMM_01_BZ  : 8|4@1+ (1.000000,0.000000) [0.000000|15.000000] "" Motor_BEV
 SG_ HMS_P_beibehalten_GE  : 12|2@1+ (1.000000,0.000000) [0.000000|3.000000] "" Vector__XXX
 SG_ VZM_Unterdrueckung_Antriebsmom  : 14|1@1+ (1.000000,0.000000) [0.000000|1.000000] "" Airbag Motor_BEV
 SG_ HMS_halten_nicht_verfuegbar  : 20|1@1+ (1.000000,0.000000) [0.000000|1.000000] "" Vector__XXX
 SG_ HMS_parken_nicht_verfuegbar  : 32|1@1+ (1.000000,0.000000) [0.000000|1.000000] "" Vector__XXX
 SG_ HMS_Anforderung_GE  : 33|3@1+ (1.000000,0.000000) [0.000000|7.000000] "" Vector__XXX
 SG_ HMS_Systemstatus  : 36|4@1+ (1.000000,0.000000) [0.000000|15.000000] "" Motor_BEV
 SG_ HMS_Stillstand  : 40|3@1+ (1.000000,0.000000) [0.000000|7.000000] "" Motor_BEV
 SG_ HMS_aktives_System  : 43|5@1+ (1.000000,0.000000) [0.000000|31.000000] "" Motor_BEV
 SG_ VMM_Inkonsistenz_GE  : 48|1@1+ (1.000000,0.000000) [0.000000|1.000000] "" Motor_BEV
 SG_ VMM_Inkonsistenz_HVLM  : 49|1@1+ (1.000000,0.000000) [0.000000|1.000000] "" Motor_BEV
 SG_ HMS_Fehlerstatus  : 50|3@1+ (1.000000,0.000000) [0.000000|7.000000] "" Vector__XXX
 SG_ HMS_Index_Haltemoment  : 53|1@1+ (1.000000,0.000000) [0.000000|1.000000] "" Motor_BEV
 SG_ HMS_Haltemoment  : 54|10@1+ (10.000000,0.000000) [0.000000|10210.000000] "Unit_NewtoMeter" Motor_BEV

BO_ 313 VMM_02: 32 ICAS1_Gateway
 SG_ VMM_02_CRC  : 0|8@1+ (1.000000,0.000000) [0.000000|255.000000] "" Motor_BEV
 SG_ VMM_02_BZ  : 8|4@1+ (1.000000,0.000000) [0.000000|15.000000] "" Motor_BEV
 SG_ VZM_aktiver_Basisservice  : 12|3@1+ (1.000000,0.000000) [0.000000|7.000000] "" Motor_BEV
 SG_ VZM_Anhalteweg_nicht_verfuegbar  : 15|1@1+ (1.000000,0.000000) [0.000000|1.000000] "" Motor_BEV
 SG_ VZM_Fahrer_bremst  : 16|1@1+ (1.000000,0.000000) [0.000000|1.000000] "" Motor_BEV
 SG_ VZM_QBit_Fahrer_bremst  : 17|1@1+ (1.000000,0.000000) [0.000000|1.000000] "" Motor_BEV
 SG_ VMM_MKB_codiert  : 18|1@1+ (1.000000,0.000000) [0.000000|1.000000] "" Airbag
 SG_ VMM_Inkonsistenz_EBKV  : 19|1@1+ (1.000000,0.000000) [0.000000|1.000000] "" Vector__XXX
 SG_ VMM_Notstopp_Status  : 20|3@1+ (1.000000,0.000000) [0.000000|7.000000] "" Motor_BEV
 SG_ VZM_Warnruck_nicht_verfuegbar  : 23|1@1+ (1.000000,0.000000) [0.000000|1.000000] "" Motor_BEV
 SG_ VZM_Warnruckeln_nicht_verfuegbar  : 24|1@1+ (1.000000,0.000000) [0.000000|1.000000] "" Motor_BEV
 SG_ VZM_Bkd_nicht_verfuegbar  : 25|1@1+ (1.000000,0.000000) [0.000000|1.000000] "" Motor_BEV
 SG_ VMM_Bremslicht_defekt  : 26|1@1+ (1.000000,0.000000) [0.000000|1.000000] "" Motor_BEV
 SG_ VZM_Fahrer_bremst_deutlich  : 27|1@1+ (1.000000,0.000000) [0.000000|1.000000] "" Airbag Motor_BEV
 SG_ VZM_TSK_SRBM_Anf  : 28|1@1+ (1.000000,0.000000) [0.000000|1.000000] "" Motor_BEV
 SG_ VZM_TSK_SRBM_nicht_verfuegbar  : 29|1@1+ (1.000000,0.000000) [0.000000|1.000000] "" Motor_BEV
 SG_ VZM_Verz_Reg_aktiv  : 30|5@1+ (1.000000,0.000000) [0.000000|31.000000] "" Motor_BEV
 SG_ VZM_Verz_Reg_nicht_verfuegbar  : 35|1@1+ (1.000000,0.000000) [0.000000|1.000000] "" Motor_BEV
 SG_ VMM_Inkonsistenz_KAS  : 36|1@1+ (1.000000,0.000000) [0.000000|1.000000] "" Motor_BEV
 SG_ VMM_Bremslicht_unplausibel  : 37|1@1+ (1.000000,0.000000) [0.000000|1.000000] "" Motor_BEV
 SG_ VMM_Inkonsistenz_ACC  : 38|1@1+ (1.000000,0.000000) [0.000000|1.000000] "" Motor_BEV
 SG_ VMM_Inkonsistenz_AWV_PCF  : 39|1@1+ (1.000000,0.000000) [0.000000|1.000000] "" Motor_BEV
 SG_ VMM_Inkonsistenz_ARA  : 40|1@1+ (1.000000,0.000000) [0.000000|1.000000] "" Motor_BEV
 SG_ VMM_Inkonsistenz_ParkAssist  : 41|1@1+ (1.000000,0.000000) [0.000000|1.000000] "" Motor_BEV
 SG_ VMM_Inkonsistenz_FAS_VK  : 42|1@1+ (1.000000,0.000000) [0.000000|1.000000] "" Motor_BEV
 SG_ VMM_Inkonsistenz_NV  : 43|1@1+ (1.000000,0.000000) [0.000000|1.000000] "" Motor_BEV
 SG_ VMM_Inkonsistenz_RCTA  : 44|1@1+ (1.000000,0.000000) [0.000000|1.000000] "" Motor_BEV
 SG_ VMM_Inkonsistenz_TSK  : 45|1@1+ (1.000000,0.000000) [0.000000|1.000000] "" Motor_BEV
 SG_ VMM_Inkonsistenz_MO  : 46|1@1+ (1.000000,0.000000) [0.000000|1.000000] "" Motor_BEV
 SG_ VMM_Inkonsistenz_AEB  : 47|1@1+ (1.000000,0.000000) [0.000000|1.000000] "" Vector__XXX
 SG_ VMM_Fahrer_Bremskraft_bestimmend  : 48|1@1+ (1.000000,0.000000) [0.000000|1.000000] "" Motor_BEV
 SG_ VMM_Inkonsistenz_EA  : 49|1@1+ (1.000000,0.000000) [0.000000|1.000000] "" Motor_BEV
 SG_ VZM_Status_Wegregelung  : 50|2@1+ (1.000000,0.000000) [0.000000|3.000000] "" Motor_BEV
 SG_ VZM_Verz_ASIL_Verfuegbarkeit  : 52|3@1+ (1.000000,0.000000) [0.000000|7.000000] "" Motor_BEV
 SG_ VZM_aktives_System  : 55|5@1+ (1.000000,0.000000) [0.000000|31.000000] "" Airbag Motor_BEV
 SG_ VZM_Verz_Begrenzung  : 60|1@1+ (1.000000,0.000000) [0.000000|1.000000] "" Motor_BEV
 SG_ VZM_Systemstatus  : 61|3@1+ (1.000000,0.000000) [0.000000|7.000000] "" Motor_BEV
 SG_ VZM_SRBM_Soll  : 64|12@1+ (8.000000,0.000000) [0.000000|32744.000000] "Unit_NewtoMeter" Motor_BEV
 SG_ VZM_SRBM_Ist  : 76|12@1+ (8.000000,0.000000) [0.000000|32744.000000] "Unit_NewtoMeter" Motor_BEV
 SG_ VZM_SRBM_max_Gradient  : 88|7@1+ (50.000000,0.000000) [0.000000|6250.000000] "Unit_NewtoMeterPerSecon" Motor_BEV
 SG_ VMM_Inkonsistenz_KAM  : 95|1@1+ (1.000000,0.000000) [0.000000|1.000000] "" Vector__XXX
